VERSION "HINBNNNYNNNNNNNNNNNNNNNNNNNNNNNNNNNYYNNNNN/4>%%%/4/'%**4NNN///"

NS_ :

BS_:

BU_: Traffic Tester CGW ADU

BO_ 1103 ADU_HMI_Information_1: 32 ADU
 SG_ PDA_disp_forward_vehicle : 249|2@0+ (1,0) [0|0] ""  CGW
 SG_ PDA_disp_traffic : 251|2@0+ (1,0) [0|0] ""  CGW
 SG_ PDA_disp_curve : 253|2@0+ (1,0) [0|0] ""  CGW
 SG_ PDA_state : 241|4@0+ (1,0) [0|0] ""  CGW
 SG_ ISA_fallback : 244|2@0+ (1,0) [0|0] ""  CGW
 SG_ ISA_overspeed : 246|2@0+ (1,0) [0|0] ""  CGW
 SG_ ISA_state : 234|4@0+ (1,0) [0|0] ""  CGW
 SG_ ISA_EV_kickdown : 235|1@0+ (1,0) [0|0] ""  CGW
 SG_ ISA_sign : 237|2@0+ (1,0) [0|0] ""  CGW
 SG_ ASC_state : 225|4@0+ (1,0) [0|0] ""  CGW
 SG_ ACC_EV_override : 226|1@0+ (1,0) [0|0] ""  CGW
 SG_ ACC_EV_offer_sign : 227|1@0+ (1,0) [0|0] ""  CGW
 SG_ ACC_EV_mode_change_reject : 228|1@0+ (1,0) [0|0] ""  CGW
 SG_ ACC_EV_mode_change_accept : 229|1@0+ (1,0) [0|0] ""  CGW
 SG_ ACC_EV_set_dist : 230|1@0+ (1,0) [0|0] ""  CGW
 SG_ ACC_set_distance : 218|4@0+ (1,0) [0|0] ""  CGW
 SG_ ACC_set_velocity : 210|8@0+ (1,0) [0|127] "Unitless"  CGW
 SG_ ACC_sign : 213|3@0+ (1,0) [0|0] ""  CGW
 SG_ ACC_stop : 215|2@0+ (1,0) [0|0] ""  CGW
 SG_ ACC_target_decel : 203|4@0+ (1,0) [0|0] ""  CGW
 SG_ ACC_state : 207|4@0+ (1,0) [0|0] ""  CGW
 SG_ ACC_target : 194|3@0+ (1,0) [0|0] ""  CGW
 SG_ AD_state : 199|4@0+ (1,0) [0|0] ""  CGW
 SG_ OCP_opp_lh : 176|2@0+ (1,0) [0|0] ""  CGW
 SG_ OCP_opp_rh : 178|2@0+ (1,0) [0|0] ""  CGW
 SG_ OCP_lane_lh : 180|2@0+ (1,0) [0|0] ""  CGW
 SG_ OCP_lane_rh : 182|2@0+ (1,0) [0|0] ""  CGW
 SG_ OCP_state : 170|4@0+ (1,0) [0|0] ""  CGW
 SG_ CBDA_target_lh : 163|2@0+ (1,0) [0|0] ""  CGW
 SG_ CBDA_target_rh : 165|2@0+ (1,0) [0|0] ""  CGW
 SG_ CBDA_state : 153|4@0+ (1,0) [0|0] ""  CGW
 SG_ BSM_target_lh : 146|2@0+ (1,0) [0|0] ""  CGW
 SG_ BSM_target_rh : 148|2@0+ (1,0) [0|0] ""  CGW
 SG_ BSM_state : 136|4@0+ (1,0) [0|0] ""  CGW
 SG_ FCTA_target_lh : 129|2@0+ (1,0) [0|0] ""  CGW
 SG_ FCTA_target_rh : 131|2@0+ (1,0) [0|0] ""  CGW
 SG_ FCTA_state : 135|4@0+ (1,0) [0|0] ""  CGW
 SG_ BSP_target_lh : 112|2@0+ (1,0) [0|0] ""  CGW
 SG_ BSP_target_rh : 114|2@0+ (1,0) [0|0] ""  CGW
 SG_ BSP_lane_lh : 116|2@0+ (1,0) [0|0] ""  CGW
 SG_ BSP_lane_rh : 118|2@0+ (1,0) [0|0] ""  CGW
 SG_ BSP_state : 106|4@0+ (1,0) [0|0] ""  CGW
 SG_ RDP_roadedge_lh : 99|2@0+ (1,0) [0|0] ""  CGW
 SG_ RDP_roadedge_rh : 101|2@0+ (1,0) [0|0] ""  CGW
 SG_ RDP_state : 89|4@0+ (1,0) [0|0] ""  CGW
 SG_ LDW_lane_lh : 82|2@0+ (1,0) [0|0] ""  CGW
 SG_ LDW_lane_rh : 84|2@0+ (1,0) [0|0] ""  CGW
 SG_ LDW_state : 72|4@0+ (1,0) [0|0] ""  CGW
 SG_ LDP_lane_lh : 65|2@0+ (1,0) [0|0] ""  CGW
 SG_ LDP_lane_rh : 67|2@0+ (1,0) [0|0] ""  CGW
 SG_ LDP_state : 71|4@0+ (1,0) [0|0] ""  CGW
 SG_ AES_state : 48|4@0+ (1,0) [0|0] ""  CGW
 SG_ RCTB_state : 55|4@0+ (1,0) [0|0] ""  CGW
 SG_ RCTA_target_lh : 44|2@0+ (1,0) [0|0] ""  CGW
 SG_ RCTA_target_rh : 46|2@0+ (1,0) [0|0] ""  CGW
 SG_ RCTA_state : 34|4@0+ (1,0) [0|0] ""  CGW
 SG_ RPTC_state : 25|4@0+ (1,0) [0|0] ""  CGW
 SG_ PAEB_state : 16|4@0+ (1,0) [0|0] ""  CGW
 SG_ CTB_target_lh : 21|2@0+ (1,0) [0|0] ""  CGW
 SG_ CTB_target_rh : 23|2@0+ (1,0) [0|0] ""  CGW
 SG_ CTB_state : 11|4@0+ (1,0) [0|0] ""  CGW
 SG_ PTC_state : 15|4@0+ (1,0) [0|0] ""  CGW
 SG_ SBS_IND_state : 3|4@0+ (1,0) [0|0] ""  CGW
 SG_ AEB_state : 7|4@0+ (1,0) [0|0] ""  CGW

BO_ 1100 ADAS_HMI_Information6: 32 ADU
 SG_ LMkrRCrv_FSC2_01 : 115|10@0+ (0.00002,-0.01) [-0.01|0.01004] "1/m"  CGW
 SG_ LMkrLCrv_FSC2_01 : 109|10@0+ (0.00002,-0.01) [-0.01|0.01004] "1/m"  CGW
 SG_ LMkrRYaw_FSC1_01 : 101|8@0+ (0.25,-30) [-30|30.5] "deg"  CGW
 SG_ LMkrLYaw_FSC1_01 : 93|8@0+ (0.25,-30) [-30|30.5] "deg"  CGW
 SG_ LMkrRY0_FSC1_01 : 87|10@0+ (0.01,-10) [-10|0.02] "m"  CGW
 SG_ LMkrLY0_FSC1_01 : 65|10@0+ (0.01,0) [0|10.02] "m"  CGW
 SG_ LMkrRReli_FSC1_01 : 68|3@0+ (1,0) [0|0] ""  CGW
 SG_ LMkrLReli_FSC1_01 : 71|3@0+ (1,0) [0|0] ""  CGW

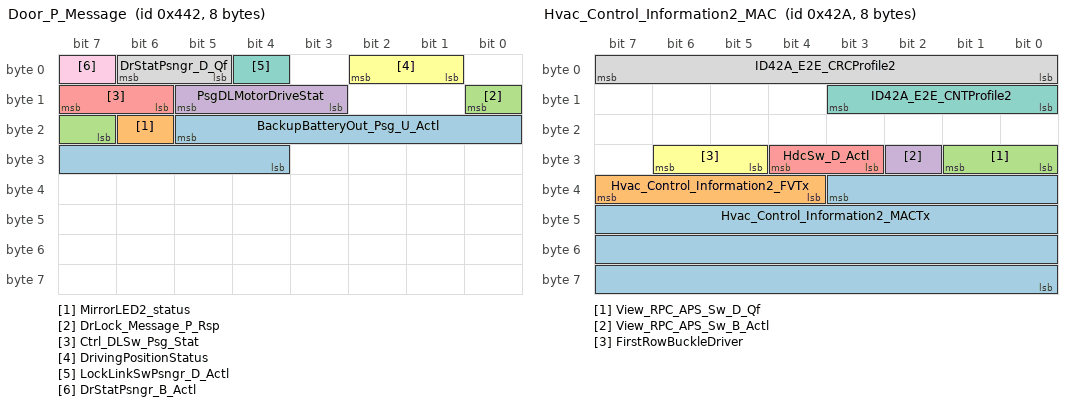
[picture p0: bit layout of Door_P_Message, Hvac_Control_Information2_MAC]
BO_ 1090 Door_P_Message: 8 CGW
 SG_ BackupBatteryOut_Psg_U_Actl : 21|10@0+ (0.02,0) [0|20.44] "V" Vector__XXX
 SG_ MirrorLED2_status : 22|1@0+ (1,0) [0|0] ""  ADU
 SG_ DrLock_Message_P_Rsp : 8|2@0+ (1,0) [0|0] "" Vector__XXX
 SG_ PsgDLMotorDriveStat : 13|3@0+ (1,0) [0|0] "" Vector__XXX
 SG_ Ctrl_DLSw_Psg_Stat : 15|2@0+ (1,0) [0|0] "" Vector__XXX
 SG_ DrivingPositionStatus : 2|2@0+ (1,0) [0|0] "" Vector__XXX
 SG_ LockLinkSwPsngr_D_Actl : 4|1@0+ (1,0) [0|0] ""  ADU
 SG_ DrStatPsngr_D_Qf : 6|2@0+ (1,0) [0|0] ""  ADU
 SG_ DrStatPsngr_B_Actl : 7|1@0+ (1,0) [0|0] ""  ADU

BO_ 1089 TripData_Control2: 32 CGW
 SG_ AvlFuelG_BCM : 119|10@0+ (0.1,0) [0|102.3] "L/100km" Vector__XXX
 SG_ AvlFuelE_BCM : 99|12@0+ (0.025,0) [0|102.375] "km/L" Vector__XXX
 SG_ OdoDistance : 78|27@0+ (0.02,0) [0|2684354.54] "km"  ADU
 SG_ AvlPwrG_BCM : 11|10@0+ (0.1,0) [0|102.3] "kwh/100km" Vector__XXX
 SG_ AvPwrE_BCM : 7|12@0+ (0.025,0) [0|102.375] "km/kwh" Vector__XXX

BO_ 1088 Door_D_Message: 8 CGW
 SG_ DOORDMSG_No_Cs : 63|8@0+ (1,0) [0|255] "" Vector__XXX
 SG_ DOORDMSG_No_Cnt : 51|4@0+ (1,0) [0|15] "" Vector__XXX
 SG_ Move_AutoDposMirror_Res : 53|2@0+ (1,0) [0|0] "" Vector__XXX
 SG_ BackupBatteryOut_Drv_U_Act : 47|10@0+ (0.02,0) [0|20.44] "V" Vector__XXX
 SG_ MirrorLED1_status : 32|1@0+ (1,0) [0|0] ""  ADU
 SG_ DrLock_Message_D_Rsp : 34|2@0+ (1,0) [0|0] "" Vector__XXX
 SG_ DrivingPositionRequest : 36|2@0+ (1,0) [0|0] "" Vector__XXX
 SG_ Mirror_AjustSelSW_Status : 38|2@0+ (1,0) [0|0] "" Vector__XXX
 SG_ MirrorFoldRequest : 24|2@0+ (1,0) [0|0] "" Vector__XXX
 SG_ MirrorAdjustRequest : 27|3@0+ (1,0) [0|0] "" Vector__XXX
 SG_ MirrorAdjst_Manual_Status : 28|1@0+ (1,0) [0|0] "" Vector__XXX
 SG_ MirrorAdjst_Status : 29|1@0+ (1,0) [0|0] "" Vector__XXX
 SG_ Erase_MirrorMem_Res : 31|2@0+ (1,0) [0|0] "" Vector__XXX
 SG_ Recall_MirrorMem_Res : 17|2@0+ (1,0) [0|0] "" Vector__XXX
 SG_ Record_MirrorMem_Res : 19|2@0+ (1,0) [0|0] "" Vector__XXX
 SG_ PW_Move_R : 22|3@0+ (1,0) [0|0] "" Vector__XXX
 SG_ PW_Move_P : 9|3@0+ (1,0) [0|0] "" Vector__XXX
 SG_ PWcut_D_Actl : 11|2@0+ (1,0) [0|0] "" Vector__XXX
 SG_ DrvDLMotorDriveStat : 15|4@0+ (1,0) [0|0] "" Vector__XXX
 SG_ Ctrl_DLSw_Drv_Stat : 1|2@0+ (1,0) [0|0] "" Vector__XXX
 SG_ LockLinkSwDrv_D_Actl : 3|2@0+ (1,0) [0|0] ""  ADU
 SG_ DrStatDrv_D_Qf : 6|2@0+ (1,0) [0|0] ""  ADU
 SG_ DrStatDrv_B_Actl : 7|1@0+ (1,0) [0|0] ""  ADU

BO_ 1087 RBCM_Information1: 8 CGW
 SG_ RBCMINFO1_No_Cs : 63|8@0+ (1,0) [0|255] "" Vector__XXX
 SG_ RBCMINFO1_No_Cnt : 51|4@0+ (1,0) [0|15] "" Vector__XXX
 SG_ RearWipr_Pos_Actl : 53|2@0+ (1,0) [0|0] "" Vector__XXX
 SG_ Rearfog_D_Act : 55|2@0+ (1,0) [0|0] "" Vector__XXX
 SG_ Reverse_D_Act : 41|2@0+ (1,0) [0|0] "" Vector__XXX
 SG_ Stoplamp_D_Act : 43|2@0+ (1,0) [0|0] ""  ADU
 SG_ Taillamp2_D_Act : 45|2@0+ (1,0) [0|0] "" Vector__XXX
 SG_ Taillamp1_D_Act : 47|2@0+ (1,0) [0|0] "" Vector__XXX
 SG_ RearTurnL_D_Act : 33|2@0+ (1,0) [0|0] ""  ADU
 SG_ RearTurnR_D_Act : 35|2@0+ (1,0) [0|0] ""  ADU
 SG_ RearWipr_Stall_Status : 36|1@0+ (1,0) [0|0] "" Vector__XXX
 SG_ RearWipr_Ctrl_Status : 39|3@0+ (1,0) [0|0] "" Vector__XXX
 SG_ Trailer_Towing_B_Actl : 24|1@0+ (1,0) [0|0] ""  ADU
 SG_ Trailer_Hitch_B_Actl : 25|1@0+ (1,0) [0|0] ""  ADU
 SG_ FuelLvlVref_No_Raw : 19|10@0+ (1,0) [0|1023] "" Vector__XXX
 SG_ FuelLvlDssvSide_No_Raw : 13|10@0+ (1,0) [0|1023] "" Vector__XXX
 SG_ FuelLvlActvSide_No_Raw : 7|10@0+ (1,0) [0|1023] "" Vector__XXX

BO_ 1086 Gateway_Information1: 32 CGW
 SG_ PreAirCon_Timer_Reservation_FS : 80|1@0+ (1,0) [0|0] "" Vector__XXX
 SG_ Charge_Timer_Reservation_FS : 81|1@0+ (1,0) [0|0] "" Vector__XXX
 SG_ RsvTime_PreAirCon_Status : 82|1@0+ (1,0) [0|0] "" Vector__XXX
 SG_ Charge_Distance_Impossible : 83|1@0+ (1,0) [0|0] "" Vector__XXX
 SG_ Charge_SOCdistance : 74|7@0+ (1,0) [0|100] "%" Vector__XXX
 SG_ Charge_Available_Distance_Upper : 70|9@0+ (2,0) [0|1000] "km" Vector__XXX
 SG_ RsvTime_Charge_Status : 71|1@0+ (1,0) [0|0] "" Vector__XXX
 SG_ Balarm_Reason_D_Actl : 48|4@0+ (1,0) [0|0] "" Vector__XXX
 SG_ OilDtr_InitTime : 54|6@0+ (1,0) [0|63] "month" Vector__XXX
 SG_ OilDtr_InitDistK : 44|6@0+ (1000,0) [0|63000] "km" Vector__XXX
 SG_ UP_Light_SENSOR_Meas : 38|10@0+ (1,0) [0|1023] "HEX"  ADU
 SG_ UP_Light_SENSOR_Qf : 39|1@0+ (1,0) [0|0] ""  ADU
 SG_ OilDtrWrnB_D_Rq : 25|2@0+ (1,0) [0|3] "" Vector__XXX
 SG_ DrStatHood_B_Actl : 28|1@0+ (1,0) [0|0] "" Vector__XXX
 SG_ Burglar_Status : 31|3@0+ (1,0) [0|0] "" Vector__XXX

BO_ 1084 CBCM_Message: 32 CGW
 SG_ Ota_SuppIgonStat : 127|4@0+ (1,0) [0|0] "" Vector__XXX
 SG_ Charge_Remote_Flag : 113|2@0+ (1,0) [0|0] "" Vector__XXX
 SG_ Defroster_Rear_Remote : 115|2@0+ (1,0) [0|0] "" Vector__XXX
 SG_ Defroster_Front_Remote : 117|2@0+ (1,0) [0|0] "" Vector__XXX
 SG_ PreAircon_RemoteTemperature : 109|8@0+ (0.1,12) [12|37.5] "deg.C" Vector__XXX
 SG_ PreAircon_Remote_Flag : 111|2@0+ (1,0) [0|0] "" Vector__XXX
 SG_ PreAircon_Remote_Cancel_Flag : 97|2@0+ (1,0) [0|0] "" Vector__XXX
 SG_ SeatCtrl_Remote_Rr_LH : 101|4@0+ (1,0) [0|0] "" Vector__XXX
 SG_ SeatCtrl_Remote_Rr_RH : 89|4@0+ (1,0) [0|0] "" Vector__XXX
 SG_ SteeringHeater_Remote : 91|2@0+ (1,0) [0|0] "" Vector__XXX
 SG_ SeatCtrl_Remote_Ps : 95|4@0+ (1,0) [0|0] "" Vector__XXX
 SG_ SeatCtrl_Remote_Dr : 83|4@0+ (1,0) [0|0] "" Vector__XXX
 SG_ RemDrvDistPer_D_Actl : 50|8@0+ (0.5,0) [0|100] "percent" Vector__XXX
 SG_ Fuel_Lid_Motor_Lock_Request : 52|2@0+ (1,0) [0|0] "" Vector__XXX
 SG_ FWD_Light_SENSOR_Meas : 46|10@0+ (1,0) [0|1023] "HEX"  ADU
 SG_ FWD_Light_SENSOR_Qf : 47|1@0+ (1,0) [0|0] ""  ADU
 SG_ DrStatRr_B_Actl : 32|1@0+ (1,0) [0|0] ""  ADU
 SG_ PwSavMode_D_Actl : 34|2@0+ (1,0) [0|0] "" Vector__XXX
 SG_ DrStatC_D_Qf : 36|2@0+ (1,0) [0|0] ""  ADU
 SG_ SecurityStatus : 37|1@0+ (1,0) [0|0] "" Vector__XXX
 SG_ PwSavModeDisp_D_Req : 24|2@0+ (1,0) [0|0] "" Vector__XXX
 SG_ GlobalOpenClose_Request : 26|2@0+ (1,0) [0|0] "" Vector__XXX
 SG_ TrnkLg_Motor_Request : 27|1@0+ (1,0) [0|0] "" Vector__XXX
 SG_ DrLockUnlock_Ctl_Rq : 31|4@0+ (1,0) [0|0] "" Vector__XXX
 SG_ DrLock_Message : 7|24@0+ (1,0) [0|16777215] "" Vector__XXX

BO_ 1078 Hvac_Control_Information2: 8 CGW
 SG_ SteerHeatIndic_D_Req : 57|2@0+ (1,0) [0|0] "" Vector__XXX
 SG_ SeatVentIndicRr_D_Req : 60|3@0+ (1,0) [0|0] "" Vector__XXX
 SG_ SeatVentIndicRl_D_Req : 63|3@0+ (1,0) [0|0] "" Vector__XXX
 SG_ SeatHeatIndicRr_D_Req : 50|3@0+ (1,0) [0|0] "" Vector__XXX
 SG_ SteerHeat_Elm_Enable : 52|2@0+ (1,0) [0|0] "" Vector__XXX
 SG_ SeatHeat_Elm_Enable : 54|2@0+ (1,0) [0|0] "" Vector__XXX
 SG_ Charge_Mode_Enabled_SW : 40|2@0+ (1,0) [0|0] "" Vector__XXX
 SG_ Drive_Mode_Enabled_Switch : 42|2@0+ (1,0) [0|0] "" Vector__XXX
 SG_ atcControlStatus : 45|3@0+ (1,0) [0|0] "" Vector__XXX
 SG_ SeatVentIndicFr_D_Req : 32|3@0+ (1,0) [0|0] "" Vector__XXX
 SG_ SeatVentIndicFl_D_Req : 35|3@0+ (1,0) [0|0] "" Vector__XXX
 SG_ SeatHeatIndicFr_D_Req : 38|3@0+ (1,0) [0|0] "" Vector__XXX
 SG_ SeatHeatIndicFl_D_Req : 25|3@0+ (1,0) [0|0] "" Vector__XXX
 SG_ atcACmodeDisp : 28|3@0+ (1,0) [0|0] "" Vector__XXX
 SG_ atcAImodeDisp : 16|4@0+ (1,0) [0|0] ""  ADU
 SG_ atcADmodeDisp : 20|4@0+ (1,0) [0|0] "" Vector__XXX
 SG_ atcBlwLvlDisp : 8|4@0+ (1,0) [0|0] "" Vector__XXX
 SG_ HvacEngStopCtrl_D_Actl : 10|2@0+ (1,0) [0|0] "" Vector__XXX
 SG_ SeatHeatIndicRl_D_Req : 13|3@0+ (1,0) [0|0] "" Vector__XXX
 SG_ BlowerSpeed : 1|4@0+ (1,0) [0|0] "" Vector__XXX
 SG_ HvacEngStopInputFail_D_Rq : 4|3@0+ (1,0) [0|0] "" Vector__XXX
 SG_ HvacAirCond_B_Rq : 5|1@0+ (1,0) [0|0] ""  ADU
 SG_ HvacEngStopDis_B_Rq_exceptTEva : 6|1@0+ (1,0) [0|0] "" Vector__XXX
 SG_ HvacEngStopDis_B_Rq : 7|1@0+ (1,0) [0|0] "" Vector__XXX

BO_ 1066 Hvac_Control_Information2_MAC: 8 CGW
 SG_ Hvac_Control_Information2_MACTx : 35|28@0+ (1,0) [0|268435455] ""  ADU
 SG_ Hvac_Control_Information2_FVTx : 39|4@0+ (1,0) [0|15] ""  ADU
 SG_ View_RPC_APS_Sw_D_Qf : 25|2@0+ (1,0) [0|0] ""  ADU
 SG_ View_RPC_APS_Sw_B_Actl : 26|1@0+ (1,0) [0|0] ""  ADU
 SG_ HdcSw_D_Actl : 28|2@0+ (1,0) [0|0] ""  ADU
 SG_ FirstRowBuckleDriver : 30|2@0+ (1,0) [0|0] ""  ADU
 SG_ ID42A_E2E_CNTProfile2 : 11|4@0+ (1,0) [0|15] ""  ADU
 SG_ ID42A_E2E_CRCProfile2 : 7|8@0+ (1,0) [0|255] ""  ADU

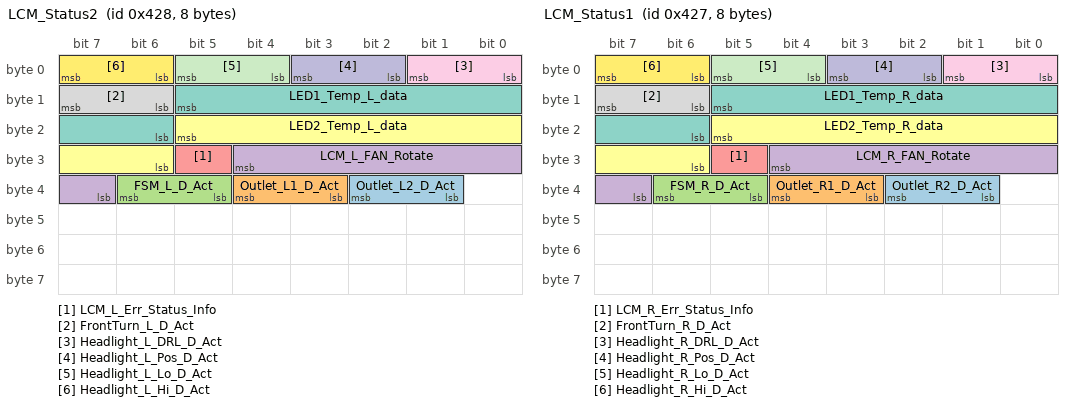
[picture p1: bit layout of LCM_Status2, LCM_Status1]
BO_ 1064 LCM_Status2: 8 CGW
 SG_ Outlet_L2_D_Act : 34|2@0+ (1,0) [0|0] "" Vector__XXX
 SG_ Outlet_L1_D_Act : 36|2@0+ (1,0) [0|0] "" Vector__XXX
 SG_ FSM_L_D_Act : 38|2@0+ (1,0) [0|0] "" Vector__XXX
 SG_ LCM_L_FAN_Rotate : 28|6@0+ (100,0) [0|5000] "rpm" Vector__XXX
 SG_ LCM_L_Err_Status_Info : 29|1@0+ (1,0) [0|0] ""  ADU
 SG_ LED2_Temp_L_data : 21|8@0+ (1,-40) [-40|210] "degC" Vector__XXX
 SG_ LED1_Temp_L_data : 13|8@0+ (1,-40) [-40|210] "degC" Vector__XXX
 SG_ FrontTurn_L_D_Act : 15|2@0+ (1,0) [0|0] ""  ADU
 SG_ Headlight_L_DRL_D_Act : 1|2@0+ (1,0) [0|0] "" Vector__XXX
 SG_ Headlight_L_Pos_D_Act : 3|2@0+ (1,0) [0|0] "" Vector__XXX
 SG_ Headlight_L_Lo_D_Act : 5|2@0+ (1,0) [0|0] ""  ADU
 SG_ Headlight_L_Hi_D_Act : 7|2@0+ (1,0) [0|0] ""  ADU

BO_ 1063 LCM_Status1: 8 CGW
 SG_ Outlet_R2_D_Act : 34|2@0+ (1,0) [0|0] "" Vector__XXX
 SG_ Outlet_R1_D_Act : 36|2@0+ (1,0) [0|0] "" Vector__XXX
 SG_ FSM_R_D_Act : 38|2@0+ (1,0) [0|0] "" Vector__XXX
 SG_ LCM_R_FAN_Rotate : 28|6@0+ (100,0) [0|5000] "rpm" Vector__XXX
 SG_ LCM_R_Err_Status_Info : 29|1@0+ (1,0) [0|0] ""  ADU
 SG_ LED2_Temp_R_data : 21|8@0+ (1,-40) [-40|210] "degC" Vector__XXX
 SG_ LED1_Temp_R_data : 13|8@0+ (1,-40) [-40|210] "degC" Vector__XXX
 SG_ FrontTurn_R_D_Act : 15|2@0+ (1,0) [0|0] ""  ADU
 SG_ Headlight_R_DRL_D_Act : 1|2@0+ (1,0) [0|0] "" Vector__XXX
 SG_ Headlight_R_Pos_D_Act : 3|2@0+ (1,0) [0|0] "" Vector__XXX
 SG_ Headlight_R_Lo_D_Act : 5|2@0+ (1,0) [0|0] ""  ADU
 SG_ Headlight_R_Hi_D_Act : 7|2@0+ (1,0) [0|0] ""  ADU

BO_ 1052 AVN1SB1: 32 CGW
 SG_ GRDTIME : 255|8@0+ (1,0) [0|255] "s"  ADU
 SG_ GRDDIST : 247|8@0+ (10,0) [0|2550] "m"  ADU
 SG_ FORMID_D : 239|8@0+ (1,0) [0|255] ""  ADU
 SG_ MDCREQID : 231|8@0+ (1,0) [0|255] ""  ADU
 SG_ PADDING1 : 199|32@0+ (1,0) [0|4294967295] ""  ADU
 SG_ FORMID_C : 191|8@0+ (1,0) [0|255] ""  ADU
 SG_ MAXTRG : 179|4@0+ (1,0) [0|15] ""  ADU
 SG_ LOGIOPE : 183|4@0+ (1,0) [0|15] ""  ADU
 SG_ FORMID_B : 175|8@0+ (1,0) [0|255] ""  ADU
 SG_ FORMID_A : 167|8@0+ (1,0) [0|255] ""  ADU
 SG_ COMPVAL : 135|32@0+ (0.1,0) [0|429496729.5] ""  ADU
 SG_ Y_CONST : 103|32@0+ (1,0) [0|4294967295] ""  ADU
 SG_ COMPOPE : 91|4@0+ (1,0) [0|15] ""  ADU
 SG_ PREPROC : 95|4@0+ (1,0) [0|15] ""  ADU
 SG_ Y_DELAY : 87|8@0+ (0.1,0) [0|25.5] "s"  ADU
 SG_ PADDINGY : 75|4@0+ (1,0) [0|15] ""  ADU
 SG_ Y_TYPE : 79|4@0+ (1,0) [0|15] ""  ADU
 SG_ Y_DATAID : 63|16@0+ (1,0) [0|65535] ""  ADU
 SG_ X_DELAY : 55|8@0+ (0.1,0) [0|25.5] "s"  ADU
 SG_ PADDINGX : 43|4@0+ (1,0) [0|15] ""  ADU
 SG_ X_TYPE : 47|4@0+ (1,0) [0|15] ""  ADU
 SG_ X_DATAID : 31|16@0+ (1,0) [0|65535] ""  ADU
 SG_ FORMID : 23|8@0+ (1,0) [0|255] ""  ADU
 SG_ FRAMID0 : 15|8@0+ (1,0) [0|255] ""  ADU
 SG_ TTLFRAM : 7|8@0+ (1,0) [0|255] ""  ADU

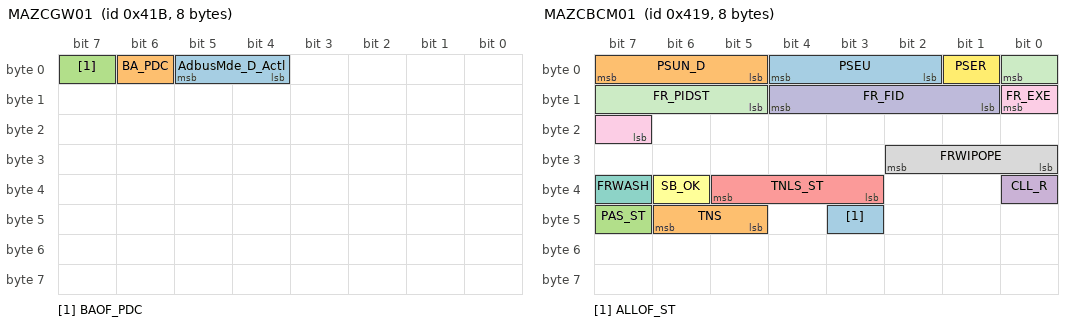
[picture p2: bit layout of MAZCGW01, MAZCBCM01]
BO_ 1051 MAZCGW01: 8 CGW
 SG_ AdbusMde_D_Actl : 5|2@0+ (1,0) [0|0] ""  ADU
 SG_ BA_PDC : 6|1@0+ (1,0) [0|0] ""  ADU
 SG_ BAOF_PDC : 7|1@0+ (1,0) [0|0] ""  ADU

BO_ 1050 MAZCBCM02: 8 CGW
 SG_ ID41A_No_Cs : 63|8@0+ (1,0) [0|255] ""  ADU
 SG_ GSNSOFF : 53|1@0+ (1,0) [0|0] "" Vector__XXX
 SG_ EIGRCPFG : 42|1@0+ (1,0) [0|1] ""  ADU
 SG_ TNLS : 44|2@0+ (1,0) [0|3] "" Vector__XXX
 SG_ G_DETECT : 33|1@0+ (1,0) [0|0] "" Vector__XXX
 SG_ AdbusMde_D_Actl_BCM : 25|2@0+ (1,0) [0|0] ""  ADU
 SG_ ERROR : 28|3@0+ (1,0) [0|7] ""  ADU
 SG_ MO_IND : 29|1@0+ (1,0) [0|1] ""  ADU
 SG_ TB_CONN : 31|2@0+ (1,0) [0|3] ""  ADU
 SG_ PARK_S : 21|6@0+ (1,0) [0|63] ""  ADU
 SG_ BA_PDC_BCM : 15|1@0+ (1,0) [0|0] ""  ADU
 SG_ BAOF_PDC_BCM : 0|1@0+ (1,0) [0|0] ""  ADU
 SG_ ACC_PDC : 1|1@0+ (1,0) [0|0] ""  ADU
 SG_ IGR_PDC : 2|1@0+ (1,0) [0|0] ""  ADU
 SG_ IGP_PDC : 3|1@0+ (1,0) [0|0] ""  ADU
 SG_ TRNR_S : 4|1@0+ (1,0) [0|0] "" Vector__XXX
 SG_ TRNL_S : 5|1@0+ (1,0) [0|0] "" Vector__XXX
 SG_ CRGR_S : 6|1@0+ (1,0) [0|1] "" Vector__XXX
 SG_ CRGL_S : 7|1@0+ (1,0) [0|1] "" Vector__XXX

BO_ 1049 MAZCBCM01: 8 CGW
 SG_ ALLOF_ST : 43|1@0+ (1,0) [0|0] ""  ADU
 SG_ TNS : 46|2@0+ (1,0) [0|0] "" Vector__XXX
 SG_ PAS_ST : 47|1@0+ (1,0) [0|0] "" Vector__XXX
 SG_ CLL_R : 32|1@0+ (1,0) [0|0] "" Vector__XXX
 SG_ TNLS_ST : 37|3@0+ (1,0) [0|0] "" Vector__XXX
 SG_ SB_OK : 38|1@0+ (1,0) [0|0] ""  ADU
 SG_ FRWASH : 39|1@0+ (1,0) [0|0] ""  ADU
 SG_ FRWIPOPE : 26|3@0+ (1,0) [0|0] ""  ADU
 SG_ FR_EXE : 8|2@0+ (1,0) [0|0] ""  ADU
 SG_ FR_FID : 12|4@0+ (1,0) [0|0] ""  ADU
 SG_ FR_PIDST : 0|4@0+ (1,0) [0|0] ""  ADU
 SG_ PSER : 1|1@0+ (1,0) [0|0] "" Vector__XXX
 SG_ PSEU : 4|3@0+ (1,0) [0|0] "" Vector__XXX
 SG_ PSUN_D : 7|3@0+ (1,0) [0|0] "" Vector__XXX

BO_ 1048 MAZDRD01: 8 CGW
 SG_ MRMV_R : 7|2@0+ (1,0) [0|0] ""  ADU

BO_ 1047 BrakeSysFeatures: 8 CGW
 SG_ BrakeSysFeatures_No_Cs : 63|8@0+ (1,0) [0|255] ""  ADU
 SG_ BrakeSysFeatures_No_Cnt : 51|4@0+ (1,0) [0|15] ""  ADU
 SG_ EPB_TrqRequire : 19|1@0+ (1,0) [0|0] "" Vector__XXX
 SG_ EPB_IGoff_Apply_Inhibit : 20|1@0+ (1,0) [0|0] "" Vector__XXX
 SG_ RGN_StpLmp_Fail_Flag : 21|1@0+ (1,0) [0|0] "" Vector__XXX
 SG_ BrkSupWhlTq_B_Falt : 22|1@0+ (1,0) [0|0] "" Vector__XXX
 SG_ BrkFluidLvl_D_Actl : 8|2@0+ (1,0) [0|0] "" Vector__XXX
 SG_ DSC_OnOff_status : 9|1@0+ (1,0) [0|0] ""  ADU
 SG_ TCS_ENG_FAILD : 10|1@0+ (1,0) [0|0] "" Vector__XXX
 SG_ TCS_BRK_FAILD : 11|1@0+ (1,0) [0|0] "" Vector__XXX
 SG_ Dsc_B_Falt : 12|1@0+ (1,0) [0|0] ""  ADU
 SG_ EPB_Status : 15|3@0+ (1,0) [0|0] "" Vector__XXX
 SG_ EPB_SwitchPosition : 1|2@0+ (1,0) [0|0] "" Vector__XXX
 SG_ EPB_EnableExternalApply_PT : 2|1@0+ (1,0) [0|0] "" Vector__XXX
 SG_ EPB_EnableDecelRequest : 3|1@0+ (1,0) [0|0] "" Vector__XXX
 SG_ EPB_EnableExternalApply_VCM : 4|1@0+ (1,0) [0|0] "" Vector__XXX
 SG_ AutoHoldStdbyLamp_D_Rq : 6|2@0+ (1,0) [0|0] "" Vector__XXX

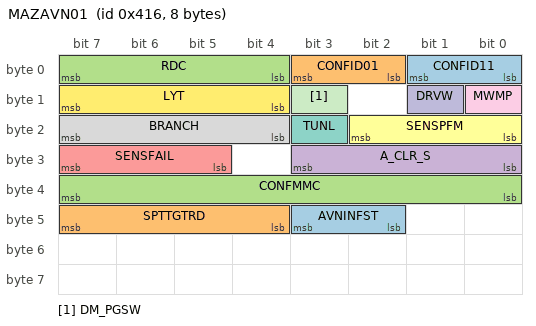
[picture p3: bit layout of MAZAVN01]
BO_ 1046 MAZAVN01: 8 CGW
 SG_ AVNINFST : 43|2@0+ (1,0) [0|3] ""  ADU
 SG_ SPTTGTRD : 47|4@0+ (1,0) [0|15] ""  ADU
 SG_ CONFMMC : 39|8@0+ (1,0) [0|255] ""  ADU
 SG_ A_CLR_S : 27|4@0+ (1,0) [0|0] ""  ADU
 SG_ SENSFAIL : 31|3@0+ (1,0) [0|7] ""  ADU
 SG_ SENSPFM : 18|3@0+ (1,0) [0|7] "s"  ADU
 SG_ TUNL : 19|1@0+ (1,0) [0|1] ""  ADU
 SG_ BRANCH : 23|4@0+ (1,0) [0|15] ""  ADU
 SG_ MWMP : 8|1@0+ (1,0) [0|1] ""  ADU
 SG_ DRVW : 9|1@0+ (1,0) [0|1] "s"  ADU
 SG_ DM_PGSW : 11|1@0+ (1,0) [0|1] ""  ADU
 SG_ LYT : 15|4@0+ (1,0) [0|15] ""  ADU
 SG_ CONFID11 : 1|2@0+ (1,0) [0|3] ""  ADU
 SG_ CONFID01 : 3|2@0+ (1,0) [0|3] ""  ADU
 SG_ RDC : 7|4@0+ (1,0) [0|15] ""  ADU

BO_ 1045 ADU1S06: 32 ADU
 SG_ DTSSLTID : 239|6@0+ (1,0) [0|63] ""  CGW
 SG_ DEPSAEST : 223|16@0+ (0.001,0) [0|65.535] "rad"  CGW
 SG_ DTSSSTR : 207|16@0+ (0.001,0) [0|65.535] "rad"  CGW
 SG_ ERMFLSV : 191|16@0+ (0.1,0) [0|6553.5] "mL"  CGW
 SG_ ERMEESV : 175|16@0+ (0.1,0) [0|6553.5] "Wh"  CGW
 SG_ DSTVIB : 162|3@0+ (1,0) [0|0] ""  CGW
 SG_ GAERR3_H : 153|7@0+ (0.1,0) [0|12.7] "deg"  CGW
 SG_ GAEVAL_H : 144|7@0+ (0.1,0) [0|12.7] "deg"  CGW
 SG_ GAERR1_V : 151|7@0+ (0.5,0) [0|63.5] "deg"  CGW
 SG_ DRTCNT_G : 135|16@0+ (1,0) [0|65535] ""  CGW
 SG_ GAE_V_R1 : 123|4@0+ (1,0) [0|15] ""  CGW
 SG_ SDIRT_G : 117|10@0+ (1,0) [0|1023] ""  CGW
 SG_ FRDHTR_G : 118|1@0+ (1,0) [0|0] ""  CGW
 SG_ GAE_H_R3 : 109|7@0+ (0.02,0) [0|2.54] "deg"  CGW
 SG_ ERMCNTST : 111|2@0+ (1,0) [0|0] ""  CGW
 SG_ DM_PVMCS : 95|16@0+ (1,0) [0|65535] ""  CGW
 SG_ DM_PVMVW : 79|16@0+ (1,0) [0|65535] ""  CGW
 SG_ PV_AREA : 71|8@0+ (0.04,0) [0|10.2] "m^2"  CGW
 SG_ V_IDARGL : 59|3@0+ (1,0) [0|0] ""  CGW
 SG_ V_IDANOA : 62|3@0+ (1,0) [0|0] ""  CGW
 SG_ EJLDACP : 63|1@0+ (1,0) [0|0] ""  CGW
 SG_ EJDEVPRD : 55|8@0+ (1,0) [0|255] ""  CGW
 SG_ V_IDACCL : 46|4@0+ (1,0) [0|0] ""  CGW
 SG_ SWSSTAT : 34|4@0+ (1,0) [0|15] ""  CGW
 SG_ LDARCGR : 38|4@0+ (1,0) [0|15] ""  CGW
 SG_ LDARCGL : 26|4@0+ (1,0) [0|15] ""  CGW
 SG_ FCMINTMP : 31|5@0+ (2,0) [0|62] "deg.C"  CGW
 SG_ LDARSN : 23|8@0+ (1,0) [0|255] ""  CGW
 SG_ LDASTATR : 15|8@0+ (1,0) [0|255] ""  CGW
 SG_ LDASTATL : 7|8@0+ (1,0) [0|255] ""  CGW

BO_ 1044 ADU1S05: 32 ADU
 SG_ ACCMARB : 23|1@0+ (1,0) [0|0] ""  CGW
 SG_ ACCMRCG : 10|3@0+ (1,0) [0|0] ""  CGW
 SG_ ACCMSGN : 12|2@0+ (1,0) [0|0] ""  CGW
 SG_ ACCMPHS : 15|3@0+ (1,0) [0|0] ""  CGW
 SG_ ACCMDST : 7|8@0+ (2,0) [0|510] "m"  CGW

BO_ 1036 GCC_Config_Mgmt2: 8 CGW
 SG_ Central_CRC_40C m224 : 55|16@0+ (1,0) [0|65534] "" Vector__XXX
 SG_ CDID_Total_Number_40C m224 : 47|8@0+ (1,0) [0|254] "" Vector__XXX
 SG_ Reserved_E0_2_40C m224 : 31|16@0+ (1,0) [0|65534] "" Vector__XXX
 SG_ Reserved_E0_1_40C m224 : 15|16@0+ (1,0) [0|65534] "" Vector__XXX
 SG_ Reserved_95_7_40C m149 : 63|8@0+ (1,0) [0|254] "" Vector__XXX
 SG_ Reserved_95_6_40C m149 : 55|8@0+ (1,0) [0|254] "" Vector__XXX
 SG_ Reserved_95_5_40C m149 : 47|8@0+ (1,0) [0|254] "" Vector__XXX
 SG_ Reserved_95_4_40C m149 : 39|8@0+ (1,0) [0|254] "" Vector__XXX
 SG_ Reserved_95_3_40C m149 : 31|8@0+ (1,0) [0|254] "" Vector__XXX
 SG_ Reserved_95_2_40C m149 : 23|8@0+ (1,0) [0|254] "" Vector__XXX
 SG_ Reserved_95_1_40C m149 : 15|8@0+ (1,0) [0|254] "" Vector__XXX
 SG_ Reserved_94_7_40C m148 : 63|8@0+ (1,0) [0|254] "" Vector__XXX
 SG_ Reserved_94_6_40C m148 : 55|8@0+ (1,0) [0|254] "" Vector__XXX
 SG_ Reserved_94_5_40C m148 : 47|8@0+ (1,0) [0|254] "" Vector__XXX
 SG_ Reserved_94_4_40C m148 : 39|8@0+ (1,0) [0|254] "" Vector__XXX
 SG_ Reserved_94_3_40C m148 : 31|8@0+ (1,0) [0|254] "" Vector__XXX
 SG_ Reserved_94_2_40C m148 : 23|8@0+ (1,0) [0|254] "" Vector__XXX
 SG_ Reserved_94_1_40C m148 : 15|8@0+ (1,0) [0|254] "" Vector__XXX
 SG_ Reserved_93_7_40C m147 : 63|8@0+ (1,0) [0|254] "" Vector__XXX
 SG_ Reserved_93_6_40C m147 : 55|8@0+ (1,0) [0|254] "" Vector__XXX
 SG_ Reserved_93_5_40C m147 : 47|8@0+ (1,0) [0|254] "" Vector__XXX
 SG_ Reserved_93_4_40C m147 : 39|8@0+ (1,0) [0|254] "" Vector__XXX
 SG_ Reserved_93_3_40C m147 : 31|8@0+ (1,0) [0|254] "" Vector__XXX
 SG_ Reserved_93_2_40C m147 : 23|8@0+ (1,0) [0|254] "" Vector__XXX
 SG_ Reserved_93_1_40C m147 : 15|8@0+ (1,0) [0|254] "" Vector__XXX
 SG_ Reserved_92_7_40C m146 : 63|8@0+ (1,0) [0|254] "" Vector__XXX
 SG_ Reserved_92_6_40C m146 : 55|8@0+ (1,0) [0|254] "" Vector__XXX
 SG_ Reserved_92_5_40C m146 : 47|8@0+ (1,0) [0|254] "" Vector__XXX
 SG_ Reserved_92_4_40C m146 : 39|8@0+ (1,0) [0|254] "" Vector__XXX
 SG_ Reserved_92_3_40C m146 : 31|8@0+ (1,0) [0|254] "" Vector__XXX
 SG_ Reserved_92_2_40C m146 : 23|8@0+ (1,0) [0|254] "" Vector__XXX
 SG_ Reserved_92_1_40C m146 : 15|8@0+ (1,0) [0|254] "" Vector__XXX
 SG_ Reserved_91_7_40C m145 : 63|8@0+ (1,0) [0|254] "" Vector__XXX
 SG_ Reserved_91_6_40C m145 : 55|8@0+ (1,0) [0|254] "" Vector__XXX
 SG_ Reserved_91_5_40C m145 : 47|8@0+ (1,0) [0|254] "" Vector__XXX
 SG_ Reserved_91_4_40C m145 : 39|8@0+ (1,0) [0|254] "" Vector__XXX
 SG_ Reserved_91_3_40C m145 : 31|8@0+ (1,0) [0|254] "" Vector__XXX
 SG_ Reserved_91_2_40C m145 : 23|8@0+ (1,0) [0|254] "" Vector__XXX
 SG_ Reserved_91_1_40C m145 : 15|8@0+ (1,0) [0|254] "" Vector__XXX
 SG_ Reserved_90_7_40C m144 : 63|8@0+ (1,0) [0|254] "" Vector__XXX
 SG_ Reserved_90_6_40C m144 : 55|8@0+ (1,0) [0|254] "" Vector__XXX
 SG_ Reserved_90_5_40C m144 : 47|8@0+ (1,0) [0|254] "" Vector__XXX
 SG_ Reserved_90_4_40C m144 : 39|8@0+ (1,0) [0|254] "" Vector__XXX
 SG_ Reserved_90_3_40C m144 : 31|8@0+ (1,0) [0|254] "" Vector__XXX
 SG_ Reserved_90_2_40C m144 : 23|8@0+ (1,0) [0|254] "" Vector__XXX
 SG_ Reserved_90_1_40C m144 : 15|8@0+ (1,0) [0|254] "" Vector__XXX
 SG_ Reserved_82_7_40C m130 : 63|8@0+ (1,0) [0|254] "" Vector__XXX
 SG_ Reserved_82_6_40C m130 : 55|8@0+ (1,0) [0|254] "" Vector__XXX
 SG_ Reserved_82_5_40C m130 : 47|8@0+ (1,0) [0|254] "" Vector__XXX
 SG_ Reserved_82_4_40C m130 : 39|8@0+ (1,0) [0|254] "" Vector__XXX
 SG_ Reserved_82_3_40C m130 : 31|8@0+ (1,0) [0|254] "" Vector__XXX
 SG_ Reserved_82_2_40C m130 : 23|8@0+ (1,0) [0|254] "" Vector__XXX
 SG_ Reserved_82_1_40C m130 : 15|8@0+ (1,0) [0|254] "" Vector__XXX
 SG_ Reserved_80_7_40C m128 : 63|8@0+ (1,0) [0|254] "" Vector__XXX
 SG_ Reserved_80_6_40C m128 : 55|8@0+ (1,0) [0|254] "" Vector__XXX
 SG_ Reserved_80_5_40C m128 : 47|8@0+ (1,0) [0|254] "" Vector__XXX
 SG_ Reserved_80_4_40C m128 : 39|8@0+ (1,0) [0|254] "" Vector__XXX
 SG_ Reserved_80_3_40C m128 : 31|8@0+ (1,0) [0|254] "" Vector__XXX
 SG_ Reserved_80_2_40C m128 : 23|8@0+ (1,0) [0|254] "" Vector__XXX
 SG_ Reserved_80_1_40C m128 : 15|8@0+ (1,0) [0|254] "" Vector__XXX
 SG_ Reserved_72_7_40C m114 : 63|8@0+ (1,0) [0|254] "" Vector__XXX
 SG_ Reserved_72_6_40C m114 : 55|8@0+ (1,0) [0|254] "" Vector__XXX
 SG_ Reserved_72_5_40C m114 : 47|8@0+ (1,0) [0|254] "" Vector__XXX
 SG_ Reserved_72_4_40C m114 : 39|8@0+ (1,0) [0|254] "" Vector__XXX
 SG_ Reserved_72_3_40C m114 : 31|8@0+ (1,0) [0|254] "" Vector__XXX
 SG_ Reserved_72_2_40C m114 : 23|8@0+ (1,0) [0|254] "" Vector__XXX
 SG_ Reserved_72_1_40C m114 : 15|8@0+ (1,0) [0|254] "" Vector__XXX
 SG_ Reserved_70_7_40C m112 : 63|8@0+ (1,0) [0|254] "" Vector__XXX
 SG_ Reserved_70_6_40C m112 : 55|8@0+ (1,0) [0|254] "" Vector__XXX
 SG_ Reserved_70_5_40C m112 : 47|8@0+ (1,0) [0|254] "" Vector__XXX
 SG_ Reserved_70_4_40C m112 : 39|8@0+ (1,0) [0|254] "" Vector__XXX
 SG_ Reserved_70_3_40C m112 : 31|8@0+ (1,0) [0|254] "" Vector__XXX
 SG_ Reserved_70_2_40C m112 : 23|8@0+ (1,0) [0|254] "" Vector__XXX
 SG_ Reserved_70_1_40C m112 : 15|8@0+ (1,0) [0|254] "" Vector__XXX
 SG_ Reserved_63_7_40C m99 : 63|8@0+ (1,0) [0|254] "" Vector__XXX
 SG_ Reserved_63_6_40C m99 : 55|8@0+ (1,0) [0|254] "" Vector__XXX
 SG_ Reserved_63_5_40C m99 : 47|8@0+ (1,0) [0|254] "" Vector__XXX
 SG_ Reserved_63_4_40C m99 : 39|8@0+ (1,0) [0|254] "" Vector__XXX
 SG_ Reserved_63_3_40C m99 : 31|8@0+ (1,0) [0|254] "" Vector__XXX
 SG_ Reserved_63_2_40C m99 : 23|8@0+ (1,0) [0|254] "" Vector__XXX
 SG_ Reserved_63_1_40C m99 : 15|8@0+ (1,0) [0|254] "" Vector__XXX
 SG_ Reserved_62_7_40C m98 : 63|8@0+ (1,0) [0|254] "" Vector__XXX
 SG_ Reserved_62_6_40C m98 : 55|8@0+ (1,0) [0|254] "" Vector__XXX
 SG_ Reserved_62_5_40C m98 : 47|8@0+ (1,0) [0|254] "" Vector__XXX
 SG_ Reserved_62_4_40C m98 : 39|8@0+ (1,0) [0|254] "" Vector__XXX
 SG_ Reserved_62_3_40C m98 : 31|8@0+ (1,0) [0|254] "" Vector__XXX
 SG_ Reserved_62_2_40C m98 : 23|8@0+ (1,0) [0|254] "" Vector__XXX
 SG_ Reserved_62_1_40C m98 : 15|8@0+ (1,0) [0|254] "" Vector__XXX
 SG_ Reserved_60_7_40C m96 : 63|8@0+ (1,0) [0|254] "" Vector__XXX
 SG_ Reserved_60_6_40C m96 : 55|8@0+ (1,0) [0|254] "" Vector__XXX
 SG_ Reserved_60_5_40C m96 : 47|8@0+ (1,0) [0|254] "" Vector__XXX
 SG_ Reserved_60_4_40C m96 : 39|8@0+ (1,0) [0|254] "" Vector__XXX
 SG_ Reserved_60_3_40C m96 : 31|8@0+ (1,0) [0|254] "" Vector__XXX
 SG_ Reserved_60_2_40C m96 : 23|8@0+ (1,0) [0|254] "" Vector__XXX
 SG_ Reserved_60_1_40C m96 : 15|8@0+ (1,0) [0|254] "" Vector__XXX
 SG_ Reserved_52_7_40C m82 : 63|8@0+ (1,0) [0|254] "" Vector__XXX
 SG_ Reserved_52_6_40C m82 : 55|8@0+ (1,0) [0|254] "" Vector__XXX
 SG_ Reserved_52_5_40C m82 : 47|8@0+ (1,0) [0|254] "" Vector__XXX
 SG_ Reserved_52_4_40C m82 : 39|8@0+ (1,0) [0|254] "" Vector__XXX
 SG_ Reserved_52_3_40C m82 : 31|8@0+ (1,0) [0|254] "" Vector__XXX
 SG_ Reserved_52_2_40C m82 : 23|8@0+ (1,0) [0|254] "" Vector__XXX
 SG_ Reserved_52_1_40C m82 : 15|8@0+ (1,0) [0|254] "" Vector__XXX
 SG_ Reserved_50_7_40C m80 : 63|8@0+ (1,0) [0|254] "" Vector__XXX
 SG_ Reserved_50_6_40C m80 : 55|8@0+ (1,0) [0|254] "" Vector__XXX
 SG_ Reserved_50_5_40C m80 : 47|8@0+ (1,0) [0|254] "" Vector__XXX
 SG_ Reserved_50_4_40C m80 : 39|8@0+ (1,0) [0|254] "" Vector__XXX
 SG_ Reserved_50_3_40C m80 : 31|8@0+ (1,0) [0|254] "" Vector__XXX
 SG_ Reserved_50_2_40C m80 : 23|8@0+ (1,0) [0|254] "" Vector__XXX
 SG_ Reserved_50_1_40C m80 : 15|8@0+ (1,0) [0|254] "" Vector__XXX
 SG_ Reserved_40_7_40C m64 : 63|8@0+ (1,0) [0|254] "" Vector__XXX
 SG_ Reserved_40_6_40C m64 : 55|8@0+ (1,0) [0|254] "" Vector__XXX
 SG_ Reserved_40_5_40C m64 : 47|8@0+ (1,0) [0|254] "" Vector__XXX
 SG_ Reserved_40_4_40C m64 : 39|8@0+ (1,0) [0|254] "" Vector__XXX
 SG_ Reserved_40_3_40C m64 : 31|8@0+ (1,0) [0|254] "" Vector__XXX
 SG_ Reserved_40_2_40C m64 : 23|8@0+ (1,0) [0|254] "" Vector__XXX
 SG_ Reserved_40_1_40C m64 : 15|8@0+ (1,0) [0|254] "" Vector__XXX
 SG_ Reserved_30_7_40C m48 : 63|8@0+ (1,0) [0|254] "" Vector__XXX
 SG_ Reserved_30_6_40C m48 : 55|8@0+ (1,0) [0|254] "" Vector__XXX
 SG_ Reserved_30_5_40C m48 : 47|8@0+ (1,0) [0|254] "" Vector__XXX
 SG_ Reserved_30_4_40C m48 : 39|8@0+ (1,0) [0|254] "" Vector__XXX
 SG_ Reserved_30_3_40C m48 : 31|8@0+ (1,0) [0|254] "" Vector__XXX
 SG_ Reserved_30_2_40C m48 : 23|8@0+ (1,0) [0|254] "" Vector__XXX
 SG_ Reserved_30_1_40C m48 : 15|8@0+ (1,0) [0|254] "" Vector__XXX
 SG_ Reserved_25_7_40C m37 : 63|8@0+ (1,0) [0|254] "" Vector__XXX
 SG_ Reserved_25_6_40C m37 : 55|8@0+ (1,0) [0|254] "" Vector__XXX
 SG_ Reserved_25_5_40C m37 : 47|8@0+ (1,0) [0|254] "" Vector__XXX
 SG_ Reserved_25_4_40C m37 : 39|8@0+ (1,0) [0|254] "" Vector__XXX
 SG_ Reserved_25_3_40C m37 : 31|8@0+ (1,0) [0|254] "" Vector__XXX
 SG_ Reserved_25_2_40C m37 : 23|8@0+ (1,0) [0|254] "" Vector__XXX
 SG_ Reserved_25_1_40C m37 : 15|8@0+ (1,0) [0|254] "" Vector__XXX
 SG_ Reserved_20_7_40C m32 : 63|8@0+ (1,0) [0|254] "" Vector__XXX
 SG_ Reserved_20_6_40C m32 : 55|8@0+ (1,0) [0|254] "" Vector__XXX
 SG_ Reserved_20_5_40C m32 : 47|8@0+ (1,0) [0|254] "" Vector__XXX
 SG_ Reserved_20_4_40C m32 : 39|8@0+ (1,0) [0|254] "" Vector__XXX
 SG_ Reserved_20_3_40C m32 : 31|8@0+ (1,0) [0|254] "" Vector__XXX
 SG_ Reserved_20_2_40C m32 : 23|8@0+ (1,0) [0|254] "" Vector__XXX
 SG_ Reserved_20_1_40C m32 : 15|8@0+ (1,0) [0|254] "" Vector__XXX
 SG_ Reserved_16_7_40C m22 : 63|8@0+ (1,0) [0|254] "" Vector__XXX
 SG_ Reserved_16_6_40C m22 : 55|8@0+ (1,0) [0|254] "" Vector__XXX
 SG_ Reserved_16_5_40C m22 : 47|8@0+ (1,0) [0|254] "" Vector__XXX
 SG_ Reserved_16_4_40C m22 : 39|8@0+ (1,0) [0|254] "" Vector__XXX
 SG_ Reserved_16_3_40C m22 : 31|8@0+ (1,0) [0|254] "" Vector__XXX
 SG_ Reserved_16_2_40C m22 : 23|8@0+ (1,0) [0|254] "" Vector__XXX
 SG_ Reserved_16_1_40C m22 : 15|8@0+ (1,0) [0|254] "" Vector__XXX
 SG_ Reserved_15_7_40C m21 : 63|8@0+ (1,0) [0|254] "" Vector__XXX
 SG_ Reserved_15_6_40C m21 : 55|8@0+ (1,0) [0|254] "" Vector__XXX
 SG_ Reserved_15_5_40C m21 : 47|8@0+ (1,0) [0|254] "" Vector__XXX
 SG_ Reserved_15_4_40C m21 : 39|8@0+ (1,0) [0|254] "" Vector__XXX
 SG_ Reserved_15_3_40C m21 : 31|8@0+ (1,0) [0|254] "" Vector__XXX
 SG_ Reserved_15_2_40C m21 : 23|8@0+ (1,0) [0|254] "" Vector__XXX
 SG_ Reserved_15_1_40C m21 : 15|8@0+ (1,0) [0|254] "" Vector__XXX
 SG_ Reserved_14_7_40C m20 : 63|8@0+ (1,0) [0|254] "" Vector__XXX
 SG_ Reserved_14_6_40C m20 : 55|8@0+ (1,0) [0|254] "" Vector__XXX
 SG_ Reserved_14_5_40C m20 : 47|8@0+ (1,0) [0|254] "" Vector__XXX
 SG_ Reserved_14_4_40C m20 : 39|8@0+ (1,0) [0|254] "" Vector__XXX
 SG_ Reserved_14_3_40C m20 : 31|8@0+ (1,0) [0|254] "" Vector__XXX
 SG_ Reserved_14_2_40C m20 : 23|8@0+ (1,0) [0|254] "" Vector__XXX
 SG_ Reserved_14_1_40C m20 : 15|8@0+ (1,0) [0|254] "" Vector__XXX
 SG_ Reserved_13_7_40C m19 : 63|8@0+ (1,0) [0|254] "" Vector__XXX
 SG_ Reserved_13_6_40C m19 : 55|8@0+ (1,0) [0|254] "" Vector__XXX
 SG_ Reserved_13_5_40C m19 : 47|8@0+ (1,0) [0|254] "" Vector__XXX
 SG_ Reserved_13_4_40C m19 : 39|8@0+ (1,0) [0|254] "" Vector__XXX
 SG_ Reserved_13_3_40C m19 : 31|8@0+ (1,0) [0|254] "" Vector__XXX
 SG_ Reserved_13_2_40C m19 : 23|8@0+ (1,0) [0|254] "" Vector__XXX
 SG_ Reserved_13_1_40C m19 : 15|8@0+ (1,0) [0|254] "" Vector__XXX
 SG_ Reserved_12_7_40C m18 : 63|8@0+ (1,0) [0|254] "" Vector__XXX
 SG_ Reserved_12_6_40C m18 : 55|8@0+ (1,0) [0|254] "" Vector__XXX
 SG_ Reserved_12_5_40C m18 : 47|8@0+ (1,0) [0|254] "" Vector__XXX
 SG_ Reserved_12_4_40C m18 : 39|8@0+ (1,0) [0|254] "" Vector__XXX
 SG_ Reserved_12_3_40C m18 : 31|8@0+ (1,0) [0|254] "" Vector__XXX
 SG_ Reserved_12_2_40C m18 : 23|8@0+ (1,0) [0|254] "" Vector__XXX
 SG_ Reserved_12_1_40C m18 : 15|8@0+ (1,0) [0|254] "" Vector__XXX
 SG_ Reserved_11_7_40C m17 : 63|8@0+ (1,0) [0|254] "" Vector__XXX
 SG_ Reserved_11_6_40C m17 : 55|8@0+ (1,0) [0|254] "" Vector__XXX
 SG_ Reserved_11_5_40C m17 : 47|8@0+ (1,0) [0|254] "" Vector__XXX
 SG_ Reserved_11_4_40C m17 : 39|8@0+ (1,0) [0|254] "" Vector__XXX
 SG_ Country_3 m17 : 31|8@0+ (1,0) [0|254] ""  ADU
 SG_ Country_2 m17 : 23|8@0+ (1,0) [0|254] ""  ADU
 SG_ Country_1 m17 : 15|8@0+ (1,0) [0|254] ""  ADU
 SG_ AIC_14 m16 : 63|8@0+ (1,0) [0|254] "" Vector__XXX
 SG_ AIC_13 m16 : 55|8@0+ (1,0) [0|254] "" Vector__XXX
 SG_ AIC_12 m16 : 47|8@0+ (1,0) [0|254] "" Vector__XXX
 SG_ AIC_11 m16 : 39|8@0+ (1,0) [0|254] "" Vector__XXX
 SG_ AIC_10 m16 : 31|8@0+ (1,0) [0|254] "" Vector__XXX
 SG_ AIC_09 m16 : 23|8@0+ (1,0) [0|254] "" Vector__XXX
 SG_ AIC_08 m16 : 15|8@0+ (1,0) [0|254] "" Vector__XXX
 SG_ AIC_07 m6 : 63|8@0+ (1,0) [0|254] "" Vector__XXX
 SG_ AIC_06 m6 : 55|8@0+ (1,0) [0|254] "" Vector__XXX
 SG_ AIC_05 m6 : 47|8@0+ (1,0) [0|254] "" Vector__XXX
 SG_ AIC_04 m6 : 39|8@0+ (1,0) [0|254] "" Vector__XXX
 SG_ AIC_03 m6 : 31|8@0+ (1,0) [0|254] "" Vector__XXX
 SG_ AIC_02 m6 : 23|8@0+ (1,0) [0|254] "" Vector__XXX
 SG_ AIC_01 m6 : 15|8@0+ (1,0) [0|254] "" Vector__XXX
 SG_ Reserved_05_1_40C m5 : 47|24@0+ (1,0) [0|16777214] "" Vector__XXX
 SG_ Project_Code_4th_40C m5 : 39|8@0+ (1,0) [0|254] "" Vector__XXX
 SG_ Project_Code_3rd_40C m5 : 31|8@0+ (1,0) [0|254] "" Vector__XXX
 SG_ Project_Code_2nd_40C m5 : 23|8@0+ (1,0) [0|254] "" Vector__XXX
 SG_ Project_Code_1st_40C m5 : 15|8@0+ (1,0) [0|254] "" Vector__XXX
 SG_ Outer_Color_3_40C m4 : 63|8@0+ (1,0) [0|254] "" Vector__XXX
 SG_ Outer_Color_2_40C m4 : 55|8@0+ (1,0) [0|254] "" Vector__XXX
 SG_ Outer_Color_1_40C m4 : 47|8@0+ (1,0) [0|254] "" Vector__XXX
 SG_ Unit_Serial_Number_40C m4 : 39|8@0+ (1,0) [0|254] "" Vector__XXX
 SG_ Unit_Destination_40C m4 : 31|8@0+ (1,0) [0|254] "" Vector__XXX
 SG_ Unit_Series_40C m4 : 23|8@0+ (1,0) [0|254] "" Vector__XXX
 SG_ Unit_Car_Line_40C m4 : 15|8@0+ (1,0) [0|254] "" Vector__XXX
 SG_ VIN_Character_21_40C m3 : 63|8@0+ (1,0) [0|254] "" Vector__XXX
 SG_ VIN_Character_20_40C m3 : 55|8@0+ (1,0) [0|254] "" Vector__XXX
 SG_ VIN_Character_19_40C m3 : 47|8@0+ (1,0) [0|254] "" Vector__XXX
 SG_ VIN_Character_18_40C m3 : 39|8@0+ (1,0) [0|254] "" Vector__XXX
 SG_ VIN_Character_17_40C m3 : 31|8@0+ (1,0) [0|254] "" Vector__XXX
 SG_ VIN_Character_16_40C m3 : 23|8@0+ (1,0) [0|254] "" Vector__XXX
 SG_ VIN_Character_15_40C m3 : 15|8@0+ (1,0) [0|254] "" Vector__XXX
 SG_ VIN_Character_14_40C m2 : 63|8@0+ (1,0) [0|254] "" Vector__XXX
 SG_ VIN_Character_13_40C m2 : 55|8@0+ (1,0) [0|254] "" Vector__XXX
 SG_ VIN_Character_12_40C m2 : 47|8@0+ (1,0) [0|254] "" Vector__XXX
 SG_ VIN_Character_11_40C m2 : 39|8@0+ (1,0) [0|254] "" Vector__XXX
 SG_ VIN_Character_10_40C m2 : 31|8@0+ (1,0) [0|254] "" Vector__XXX
 SG_ VIN_Character_09_40C m2 : 23|8@0+ (1,0) [0|254] "" Vector__XXX
 SG_ VIN_Character_08_40C m2 : 15|8@0+ (1,0) [0|254] "" Vector__XXX
 SG_ VIN_Character_07_40C m1 : 63|8@0+ (1,0) [0|254] "" Vector__XXX
 SG_ VIN_Character_06_40C m1 : 55|8@0+ (1,0) [0|254] "" Vector__XXX
 SG_ VIN_Character_05_40C m1 : 47|8@0+ (1,0) [0|254] "" Vector__XXX
 SG_ VIN_Character_04_40C m1 : 39|8@0+ (1,0) [0|254] "" Vector__XXX
 SG_ VIN_Character_03_40C m1 : 31|8@0+ (1,0) [0|254] "" Vector__XXX
 SG_ VIN_Character_02_40C m1 : 23|8@0+ (1,0) [0|254] "" Vector__XXX
 SG_ VIN_Character_01_40C m1 : 15|8@0+ (1,0) [0|254] "" Vector__XXX
 SG_ EngRunTimer_40C m243 : 55|16@0+ (1,0) [0|65535] "" Vector__XXX
 SG_ Reserved_F3_2_40C m243 : 47|8@0+ (1,0) [0|255] "" Vector__XXX
 SG_ BrakePedal_40C m243 : 39|8@0+ (1,0) [0|255] "" Vector__XXX
 SG_ Reserved_F3_1_40C m243 : 31|8@0+ (1,0) [0|255] "" Vector__XXX
 SG_ VehicleSpeed_40C m243 : 23|8@0+ (1,0) [0|255] "" Vector__XXX
 SG_ Engine_RPM_40C m243 : 15|8@0+ (1,0) [0|255] "" Vector__XXX
 SG_ ShiftPosition_40C m242 : 63|8@0+ (1,0) [0|255] "" Vector__XXX
 SG_ Engine_Coolant_Temperature_40C m242 : 55|8@0+ (1,-40) [-40|215] "" Vector__XXX
 SG_ AccelPedalPosition_40C m242 : 47|8@0+ (1,0) [0|255] "" Vector__XXX
 SG_ Reserved_F2_1_40C m242 : 39|8@0+ (1,0) [0|255] "" Vector__XXX
 SG_ SOC_40C m242 : 31|8@0+ (1,0) [0|255] "" Vector__XXX
 SG_ IG_OnTimer_40C m242 : 15|16@0+ (1,0) [0|65535] "" Vector__XXX
 SG_ PwMdeExtern_D_Actl_40C m241 : 63|8@0+ (1,0) [0|255] "" Vector__XXX
 SG_ Ambient_Air_Temperature_40C m241 : 55|8@0+ (1,-40) [-40|215] "" Vector__XXX
 SG_ MECU_supply_voltage_40C m241 : 47|8@0+ (1,0) [0|255] "" Vector__XXX
 SG_ VehicleOdometerInformation_40C m241 : 15|32@0+ (1,0) [0|4294967295] "" Vector__XXX
 SG_ SOC2_SS_40C m240 : 63|8@0+ (1,0) [0|255] "" Vector__XXX
 SG_ MotorRPM_SS_40C m240 : 47|16@0+ (1,0) [0|65535] "" Vector__XXX
 SG_ Global_Real_Time_40C m240 : 15|32@0+ (1,0) [0|4294967295] "" Vector__XXX
 SG_ GCC_CfgParam_40C M : 7|8@0+ (1,0) [0|0] ""  ADU

BO_ 1034 GCC_Config_Mgmt: 8 CGW
 SG_ Central_CRC m224 : 55|16@0+ (1,0) [0|65534] ""  ADU
 SG_ CDID_Total_Number m224 : 47|8@0+ (1,0) [0|254] ""  ADU
 SG_ Reserved_E0_2 m224 : 31|16@0+ (1,0) [0|65534] ""  ADU
 SG_ Reserved_E0_1 m224 : 15|16@0+ (1,0) [0|65534] ""  ADU
 SG_ Reserved_95_7 m149 : 63|8@0+ (1,0) [0|254] ""  ADU
 SG_ Reserved_95_6 m149 : 55|8@0+ (1,0) [0|254] ""  ADU
 SG_ Reserved_95_5 m149 : 47|8@0+ (1,0) [0|254] ""  ADU
 SG_ Reserved_95_4 m149 : 39|8@0+ (1,0) [0|254] ""  ADU
 SG_ Reserved_95_3 m149 : 31|8@0+ (1,0) [0|254] ""  ADU
 SG_ Reserved_95_2 m149 : 23|8@0+ (1,0) [0|254] ""  ADU
 SG_ Reserved_95_1 m149 : 15|8@0+ (1,0) [0|254] ""  ADU
 SG_ Reserved_94_7 m148 : 63|8@0+ (1,0) [0|254] ""  ADU
 SG_ Reserved_94_6 m148 : 55|8@0+ (1,0) [0|254] ""  ADU
 SG_ Reserved_94_5 m148 : 47|8@0+ (1,0) [0|254] ""  ADU
 SG_ Reserved_94_4 m148 : 39|8@0+ (1,0) [0|254] ""  ADU
 SG_ Reserved_94_3 m148 : 31|8@0+ (1,0) [0|254] ""  ADU
 SG_ Reserved_94_2 m148 : 23|8@0+ (1,0) [0|254] ""  ADU
 SG_ Reserved_94_1 m148 : 15|8@0+ (1,0) [0|254] ""  ADU
 SG_ Reserved_93_7 m147 : 63|8@0+ (1,0) [0|254] ""  ADU
 SG_ Reserved_93_6 m147 : 55|8@0+ (1,0) [0|254] ""  ADU
 SG_ Reserved_93_5 m147 : 47|8@0+ (1,0) [0|254] ""  ADU
 SG_ Reserved_93_4 m147 : 39|8@0+ (1,0) [0|254] ""  ADU
 SG_ Reserved_93_3 m147 : 31|8@0+ (1,0) [0|254] ""  ADU
 SG_ Reserved_93_2 m147 : 23|8@0+ (1,0) [0|254] ""  ADU
 SG_ Reserved_93_1 m147 : 15|8@0+ (1,0) [0|254] ""  ADU
 SG_ Reserved_92_7 m146 : 63|8@0+ (1,0) [0|254] ""  ADU
 SG_ Reserved_92_6 m146 : 55|8@0+ (1,0) [0|254] ""  ADU
 SG_ Reserved_92_5 m146 : 47|8@0+ (1,0) [0|254] ""  ADU
 SG_ Reserved_92_4 m146 : 39|8@0+ (1,0) [0|254] ""  ADU
 SG_ Reserved_92_3 m146 : 31|8@0+ (1,0) [0|254] ""  ADU
 SG_ Reserved_92_2 m146 : 23|8@0+ (1,0) [0|254] ""  ADU
 SG_ ADAS_VARIATION_1 m146 : 15|8@0+ (1,0) [0|254] ""  ADU
 SG_ Reserved_91_7 m145 : 63|8@0+ (1,0) [0|254] ""  ADU
 SG_ Reserved_91_6 m145 : 55|8@0+ (1,0) [0|254] ""  ADU
 SG_ Reserved_91_5 m145 : 47|8@0+ (1,0) [0|254] ""  ADU
 SG_ Reserved_91_4 m145 : 39|8@0+ (1,0) [0|254] ""  ADU
 SG_ ADAS_COUNTRY_3 m145 : 31|8@0+ (1,0) [0|254] ""  ADU
 SG_ ADAS_COUNTRY_2 m145 : 23|8@0+ (1,0) [0|254] ""  ADU
 SG_ ADAS_COUNTRY_1 m145 : 15|8@0+ (1,0) [0|254] ""  ADU
 SG_ Reserved_90_7 m144 : 63|8@0+ (1,0) [0|254] ""  ADU
 SG_ Reserved_90_6 m144 : 55|8@0+ (1,0) [0|254] ""  ADU
 SG_ PRECEDING_VEHICLE_NOTIFICATION m144 : 47|8@0+ (1,0) [0|254] ""  ADU
 SG_ Reserved_90_4 m144 : 39|8@0+ (1,0) [0|254] ""  ADU
 SG_ Reserved_90_3 m144 : 31|8@0+ (1,0) [0|254] ""  ADU
 SG_ FR_POSITION_TYPE m144 : 23|8@0+ (1,0) [0|254] ""  ADU
 SG_ RBUMPER_SHAPE_TYPE m144 : 15|8@0+ (1,0) [0|254] ""  ADU
 SG_ Reserved_82_8 m130 : 59|4@0+ (1,0) [0|14] ""  ADU
 SG_ IP_DECORATION_ILLUMI m130 : 63|4@0+ (1,0) [0|14] ""  ADU
 SG_ DRIVE_RECORDER m130 : 51|4@0+ (1,0) [0|14] ""  ADU
 SG_ ALEXA m130 : 55|4@0+ (1,0) [0|14] ""  ADU
 SG_ ASE_SYSTEM m130 : 43|4@0+ (1,0) [0|14] ""  ADU
 SG_ WIRELESS_CHARGE m130 : 47|4@0+ (1,0) [0|14] ""  ADU
 SG_ FBUMPER_ASSY_TYPE m130 : 35|4@0+ (1,0) [0|14] ""  ADU
 SG_ FBUMPER_SHAPE_TYPE m130 : 39|4@0+ (1,0) [0|14] ""  ADU
 SG_ EMERGENCY_DRIVER_ASSIST m130 : 27|4@0+ (1,0) [0|14] ""  ADU
 SG_ VMC_COMMUNICATION_TYPE m130 : 31|4@0+ (1,0) [0|14] ""  ADU
 SG_ VMC_POSITION m130 : 17|2@0+ (1,0) [0|2] ""  ADU
 SG_ Reserved_82_3 m130 : 19|2@0+ (1,0) [0|2] ""  ADU
 SG_ INTERSECTION_BRAKE_SUPP m130 : 23|4@0+ (1,0) [0|14] ""  ADU
 SG_ PERSONALIZE_SYSTEM m130 : 11|4@0+ (1,0) [0|14] ""  ADU
 SG_ TAP m130 : 15|4@0+ (1,0) [0|14] ""  ADU
 SG_ Reserved_80_5 m128 : 59|4@0+ (1,0) [0|14] ""  ADU
 SG_ ENGINE_POWER_TYPE m128 : 63|4@0+ (1,0) [0|14] ""  ADU
 SG_ Number_Of_Cylinders m128 : 51|4@0+ (1,0) [0|14] ""  ADU
 SG_ TURBO_ENGINE m128 : 55|4@0+ (1,0) [0|14] ""  ADU
 SG_ CYLINDER_DEACTIVATION m128 : 43|4@0+ (1,0) [0|14] ""  ADU
 SG_ UPGRADE_ENGINE m128 : 47|4@0+ (1,0) [0|14] ""  ADU
 SG_ ENGINE_TYPE m128 : 39|8@0+ (1,0) [0|254] ""  ADU
 SG_ Reserved_80_3 m128 : 27|4@0+ (1,0) [0|14] ""  ADU
 SG_ AC_CHARGING_TYPE m128 : 31|4@0+ (1,0) [0|14] ""  ADU
 SG_ DC_CHARGING_TYPE m128 : 19|4@0+ (1,0) [0|14] ""  ADU
 SG_ AUX_POWER_UNIT m128 : 23|4@0+ (1,0) [0|14] ""  ADU
 SG_ Reserved_80_1 m128 : 11|4@0+ (1,0) [0|14] ""  ADU
 SG_ XEV_TYPE m128 : 15|4@0+ (1,0) [0|14] ""  ADU
 SG_ Reserved_72_3 m114 : 55|16@0+ (1,0) [0|65535] ""  ADU
 SG_ Reserved_72_4 m114 : 41|2@0+ (1,0) [0|2] ""  ADU
 SG_ REMOTE_ENGINE_START_OPT m114 : 43|2@0+ (1,0) [0|2] ""  ADU
 SG_ DOWN_LIGHT m114 : 45|2@0+ (1,0) [0|2] ""  ADU
 SG_ KEYLESS_WINDOW_CONTROL m114 : 47|2@0+ (1,0) [0|2] ""  ADU
 SG_ KEY_LESS_COMPT m114 : 33|2@0+ (1,0) [0|2] ""  ADU
 SG_ SMART_KEYLESS m114 : 35|2@0+ (1,0) [0|2] ""  ADU
 SG_ KEY_LESS_ENTRY m114 : 39|4@0+ (1,0) [0|14] ""  ADU
 SG_ Reserved_72_2 m114 : 27|4@0+ (1,0) [0|14] ""  ADU
 SG_ PGR_AIR_BAG_CUT_INDICATOR m114 : 31|4@0+ (1,0) [0|14] ""  ADU
 SG_ REMINDER_CONTROL_SPEC m114 : 23|8@0+ (1,0) [0|254] ""  ADU
 SG_ SEAT_BELT_WARNING_SYSTEM m114 : 11|4@0+ (1,0) [0|14] ""  ADU
 SG_ OCCUPANT_SENSING_SYSTEM m114 : 15|4@0+ (1,0) [0|14] ""  ADU
 SG_ Reserved_70_4 m112 : 63|8@0+ (1,0) [0|254] ""  ADU
 SG_ R_SEAT_NO2_TYPE m112 : 51|4@0+ (1,0) [0|14] ""  ADU
 SG_ R_SEAT_NO1_TYPE m112 : 55|4@0+ (1,0) [0|14] ""  ADU
 SG_ EXTERIOR_ALERT_TYPE m112 : 43|4@0+ (1,0) [0|14] ""  ADU
 SG_ CPD_CONTROL_TYPE m112 : 47|4@0+ (1,0) [0|14] ""  ADU
 SG_ Reserved_70_3 m112 : 33|2@0+ (1,0) [0|2] ""  ADU
 SG_ F_SEAT_VENTILATION m112 : 35|2@0+ (1,0) [0|2] ""  ADU
 SG_ F_SEAT_TYPE m112 : 39|4@0+ (1,0) [0|14] ""  ADU
 SG_ Reserved_70_2 m112 : 25|2@0+ (1,0) [0|2] ""  ADU
 SG_ R_SEAT_WARMER m112 : 27|2@0+ (1,0) [0|2] ""  ADU
 SG_ F_SEAT_WARMER m112 : 31|4@0+ (1,0) [0|14] ""  ADU
 SG_ Reserved_70_1 m112 : 19|4@0+ (1,0) [0|14] ""  ADU
 SG_ F_SEAT_LIFT_MECHANISM m112 : 23|4@0+ (1,0) [0|14] ""  ADU
 SG_ SEAT_MATERIAL m112 : 15|8@0+ (1,0) [0|254] ""  ADU
 SG_ Reserved_63_1 m99 : 63|8@0+ (1,0) [0|254] ""  ADU
 SG_ Vehicle_Height m99 : 47|16@0+ (1,0) [0|65534] ""  ADU
 SG_ Vehicle_Width m99 : 31|16@0+ (1,0) [0|65534] ""  ADU
 SG_ Vehicle_Length m99 : 15|16@0+ (1,0) [0|65534] ""  ADU
 SG_ Reserved_62_2 m98 : 57|2@0+ (1,0) [0|2] ""  ADU
 SG_ TOUCH_PANEL m98 : 59|2@0+ (1,0) [0|2] ""  ADU
 SG_ DISPLAY_SIZE m98 : 63|4@0+ (1,0) [0|14] ""  ADU
 SG_ HD_Radio m98 : 49|2@0+ (1,0) [0|2] ""  ADU
 SG_ TELEMATICS_COM_UNIT m98 : 51|2@0+ (1,0) [0|2] ""  ADU
 SG_ B_CALL m98 : 43|8@0+ (1,0) [0|254] ""  ADU
 SG_ CMU_Spec m98 : 47|4@0+ (1,0) [0|14] ""  ADU
 SG_ Number_Of_Seat_Rows m98 : 33|2@0+ (1,0) [0|2] ""  ADU
 SG_ Tuner_AM_Range m98 : 35|2@0+ (1,0) [0|2] ""  ADU
 SG_ Pandora m98 : 37|2@0+ (1,0) [0|2] ""  ADU
 SG_ Mobile_911 m98 : 39|2@0+ (1,0) [0|2] ""  ADU
 SG_ HDMI m98 : 25|2@0+ (1,0) [0|2] ""  ADU
 SG_ LW m98 : 27|2@0+ (1,0) [0|2] ""  ADU
 SG_ Limit_Of_DAB_Range m98 : 31|4@0+ (1,0) [0|14] ""  ADU
 SG_ ELK_CUSTOMIZE_TYPE m98 : 17|2@0+ (1,0) [0|2] ""  ADU
 SG_ Microphone m98 : 19|2@0+ (1,0) [0|2] ""  ADU
 SG_ DAA_Default m98 : 21|2@0+ (1,0) [0|2] ""  ADU
 SG_ Carplay m98 : 23|2@0+ (1,0) [0|2] ""  ADU
 SG_ Android_Auto m98 : 9|2@0+ (1,0) [0|2] ""  ADU
 SG_ Wi_Fi_Frequency m98 : 11|2@0+ (1,0) [0|2] ""  ADU
 SG_ Commander_Touchpad m98 : 13|2@0+ (1,0) [0|2] ""  ADU
 SG_ TPEG m98 : 15|2@0+ (1,0) [0|2] ""  ADU
 SG_ Reserved_60_1 m96 : 63|8@0+ (1,0) [0|254] ""  ADU
 SG_ SIGN_DISPLAY m96 : 51|4@0+ (1,0) [0|14] ""  ADU
 SG_ UI_RESTRICTION m96 : 55|4@0+ (1,0) [0|14] ""  ADU
 SG_ ADAS_MAP_SYSTEM m96 : 43|4@0+ (1,0) [0|14] ""  ADU
 SG_ RDS_SPEC m96 : 47|4@0+ (1,0) [0|14] ""  ADU
 SG_ EMERGENCY_CALL m96 : 35|4@0+ (1,0) [0|14] ""  ADU
 SG_ SATELITE_SPEC m96 : 39|4@0+ (1,0) [0|14] ""  ADU
 SG_ NAVI_MAP_DATA m96 : 27|4@0+ (1,0) [0|14] ""  ADU
 SG_ CD_Ripping m96 : 29|2@0+ (1,0) [0|2] ""  ADU
 SG_ TV_TUNER m96 : 31|2@0+ (1,0) [0|2] ""  ADU
 SG_ SPEAKER_TYPE m96 : 19|4@0+ (1,0) [0|14] ""  ADU
 SG_ DVD m96 : 21|2@0+ (1,0) [0|2] ""  ADU
 SG_ CD m96 : 23|2@0+ (1,0) [0|2] ""  ADU
 SG_ FREQUENCY m96 : 11|4@0+ (1,0) [0|14] ""  ADU
 SG_ RDS m96 : 13|2@0+ (1,0) [0|2] ""  ADU
 SG_ DAB m96 : 15|2@0+ (1,0) [0|2] ""  ADU
 SG_ Reserved_52_6 m82 : 63|8@0+ (1,0) [0|254] ""  ADU
 SG_ AT_SHIFT_SW m82 : 51|4@0+ (1,0) [0|14] ""  ADU
 SG_ ELECTRIC_SHIFT m82 : 55|4@0+ (1,0) [0|14] ""  ADU
 SG_ Reserved_52_5 m82 : 41|2@0+ (1,0) [0|2] ""  ADU
 SG_ STG_WHEEL_WARMER m82 : 43|2@0+ (1,0) [0|2] ""  ADU
 SG_ TILT_STG m82 : 47|4@0+ (1,0) [0|14] ""  ADU
 SG_ Reserved_52_4 m82 : 39|8@0+ (1,0) [0|254] ""  ADU
 SG_ DRIVE_SELECTION_MODE m82 : 27|4@0+ (1,0) [0|14] ""  ADU
 SG_ Reserved_52_3 m82 : 29|2@0+ (1,0) [0|2] ""  ADU
 SG_ DRIVE_SELECTION m82 : 31|2@0+ (1,0) [0|2] ""  ADU
 SG_ I_DM m82 : 17|2@0+ (1,0) [0|2] ""  ADU
 SG_ Reserved_52_2 m82 : 19|2@0+ (1,0) [0|2] ""  ADU
 SG_ OVER_HEAD_CONSOLE m82 : 23|4@0+ (1,0) [0|14] ""  ADU
 SG_ AT_INTERLOCK_UNLOCK_SYS m82 : 11|4@0+ (1,0) [0|14] ""  ADU
 SG_ BURGLAR_ALARM_SYSTEM m82 : 15|4@0+ (1,0) [0|14] ""  ADU
 SG_ Reserved_50_3 m80 : 47|24@0+ (1,0) [0|16777214] ""  ADU
 SG_ TSR_GSR_TYPE m80 : 35|4@0+ (1,0) [0|14] ""  ADU
 SG_ SPEED_METER m80 : 39|4@0+ (1,0) [0|14] ""  ADU
 SG_ FUEL_CONSUMPTION_UNIT m80 : 27|4@0+ (1,0) [0|14] ""  ADU
 SG_ TRIP_COMPUTER m80 : 31|4@0+ (1,0) [0|14] ""  ADU
 SG_ HEAD_UP_DISPLAY m80 : 17|2@0+ (1,0) [0|2] ""  ADU
 SG_ WARNING_BUZZER_120KMH m80 : 19|2@0+ (1,0) [0|2] ""  ADU
 SG_ TURN_SIGNAL_SWITCH m80 : 21|2@0+ (1,0) [0|2] ""  ADU
 SG_ Reserved_50_1 m80 : 23|2@0+ (1,0) [0|2] ""  ADU
 SG_ MULTI_DOT_DISPLAY m80 : 9|2@0+ (1,0) [0|2] ""  ADU
 SG_ Reserved_50_4 m80 : 11|2@0+ (1,0) [0|2] ""  ADU
 SG_ IND_STD_OF_SPEED_METER m80 : 15|4@0+ (1,0) [0|14] ""  ADU
 SG_ Reserved_40_4 m64 : 55|16@0+ (1,0) [0|65535] ""  ADU
 SG_ F_EX_MIRROR_AUTO_FOLD m64 : 41|2@0+ (1,0) [0|2] ""  ADU
 SG_ F_EXT_MIRROR_ADJ_MEMORY m64 : 43|2@0+ (1,0) [0|2] ""  ADU
 SG_ F_EXT_MIRROR_HEATER m64 : 45|2@0+ (1,0) [0|2] ""  ADU
 SG_ F_EX_MIRROR_POWER_FOLD m64 : 47|2@0+ (1,0) [0|2] ""  ADU
 SG_ Reserved_40_3 m64 : 31|16@0+ (1,0) [0|65534] ""  ADU
 SG_ R_SEAT_NO1_SEAT_TRACK m64 : 19|4@0+ (1,0) [0|14] ""  ADU
 SG_ ONE_TOUCH_SYSTEM m64 : 23|4@0+ (1,0) [0|14] ""  ADU
 SG_ R_SEAT_VENTILATION m64 : 9|2@0+ (1,0) [0|2] ""  ADU
 SG_ WASHER_LEVEL_LAMP m64 : 11|2@0+ (1,0) [0|2] ""  ADU
 SG_ F_WIPER_INTERMITTENT m64 : 15|4@0+ (1,0) [0|14] ""  ADU
 SG_ Reserved_30_6 m48 : 63|8@0+ (1,0) [0|254] ""  ADU
 SG_ AUTO_DOOR_LOCK m48 : 51|4@0+ (1,0) [0|14] ""  ADU
 SG_ Reserved_30_5 m48 : 53|2@0+ (1,0) [0|2] ""  ADU
 SG_ SUPER_LOCK_SYSTEM m48 : 55|2@0+ (1,0) [0|2] ""  ADU
 SG_ POWER_DOOR_LOCK_SW m48 : 43|4@0+ (1,0) [0|14] ""  ADU
 SG_ POWER_DOOR_LOCK m48 : 47|4@0+ (1,0) [0|14] ""  ADU
 SG_ Reserved_30_4 m48 : 39|8@0+ (1,0) [0|254] ""  ADU
 SG_ Reserved_30_3 m48 : 29|6@0+ (1,0) [0|62] ""  ADU
 SG_ POWER_BACK_DOOR m48 : 31|2@0+ (1,0) [0|2] ""  ADU
 SG_ Reserved_30_2 m48 : 23|8@0+ (1,0) [0|254] ""  ADU
 SG_ Reserved_30_1 m48 : 11|4@0+ (1,0) [0|14] ""  ADU
 SG_ TRUNK_LID_OPENER m48 : 15|4@0+ (1,0) [0|14] ""  ADU
 SG_ Reserved_25_4 m37 : 47|24@0+ (1,0) [0|16777214] ""  ADU
 SG_ DEFAULT_ONE_TOUCH_TURN m37 : 33|2@0+ (1,0) [0|2] ""  ADU
 SG_ ESS m37 : 35|2@0+ (1,0) [0|2] ""  ADU
 SG_ R_FOG_LAMP m37 : 37|2@0+ (1,0) [0|2] ""  ADU
 SG_ F_FOG_LAMP m37 : 39|2@0+ (1,0) [0|2] ""  ADU
 SG_ Reserved_25_3 m37 : 27|4@0+ (1,0) [0|14] ""  ADU
 SG_ PASSIVE_COLLISION_SIGNAL m37 : 31|4@0+ (1,0) [0|14] ""  ADU
 SG_ F_AND_R_SIDE_MARKER_US m37 : 17|2@0+ (1,0) [0|2] ""  ADU
 SG_ AUTO_HEAD_LAMP_ON_OFF m37 : 19|2@0+ (1,0) [0|2] ""  ADU
 SG_ RUNNING_LAMP_CUSTOMIZE m37 : 23|4@0+ (1,0) [0|14] ""  ADU
 SG_ F_COMBI_SIGNATURE_ILLUMI m37 : 9|2@0+ (1,0) [0|2] ""  ADU
 SG_ HEAD_LAMP_CLEANER m37 : 11|2@0+ (1,0) [0|2] ""  ADU
 SG_ Headlamp_Control m37 : 15|4@0+ (1,0) [0|14] ""  ADU
 SG_ Reserved_20_3 m32 : 55|16@0+ (1,0) [0|65535] ""  ADU
 SG_ AC_Refrigerant_Gas m32 : 43|4@0+ (1,0) [0|14] ""  ADU
 SG_ AC_Compressor m32 : 47|4@0+ (1,0) [0|14] ""  ADU
 SG_ Reserved_20_2 m32 : 35|4@0+ (1,0) [0|14] ""  ADU
 SG_ SERVER_REGION m32 : 39|4@0+ (1,0) [0|14] ""  ADU
 SG_ DEFROSTER_CIRCULATION_CONTROL m32 : 27|4@0+ (1,0) [0|14] ""  ADU
 SG_ TEMPERATURE_SETTING_RANGE m32 : 31|4@0+ (1,0) [0|14] ""  ADU
 SG_ Reserved_20_1 m32 : 17|2@0+ (1,0) [0|2] ""  ADU
 SG_ PreAirCon_OperatingTime m32 : 21|4@0+ (1,0) [0|14] ""  ADU
 SG_ R_VENT_COOLER m32 : 23|2@0+ (1,0) [0|2] ""  ADU
 SG_ HUMIDITY_SENSOR m32 : 9|2@0+ (1,0) [0|2] ""  ADU
 SG_ PTC_HEATER m32 : 11|2@0+ (1,0) [0|2] ""  ADU
 SG_ F_AIR_CONDITIONER m32 : 15|4@0+ (1,0) [0|14] ""  ADU
 SG_ Reserved_16_3 m22 : 47|24@0+ (1,0) [0|16777214] ""  ADU
 SG_ Reserved_16_2 m22 : 35|4@0+ (1,0) [0|14] ""  ADU
 SG_ OCCUPANT_MONITOR_SYSTEM m22 : 37|2@0+ (1,0) [0|2] ""  ADU
 SG_ FRONT_SIDE_RADAR m22 : 39|2@0+ (1,0) [0|2] ""  ADU
 SG_ TJA_TYPE m22 : 27|4@0+ (1,0) [0|14] ""  ADU
 SG_ VIEW_MONITOR_CAMERA m22 : 31|4@0+ (1,0) [0|14] ""  ADU
 SG_ FRONT_REAR_SIDE_SONAR m22 : 19|4@0+ (1,0) [0|14] ""  ADU
 SG_ DRIVER_MONITOR m22 : 21|2@0+ (1,0) [0|2] ""  ADU
 SG_ FRONT_CROSS_TRAFFIC_ALERT m22 : 23|2@0+ (1,0) [0|2] ""  ADU
 SG_ INTERSECTION_BRAKE_TYPE m22 : 11|4@0+ (1,0) [0|14] ""  ADU
 SG_ BLIND_SPOT_PREVENTION m22 : 13|2@0+ (1,0) [0|2] ""  ADU
 SG_ Reserved_16_1 m22 : 15|2@0+ (1,0) [0|2] ""  ADU
 SG_ Reserved_15_3 m21 : 47|24@0+ (1,0) [0|16777214] ""  ADU
 SG_ SBS_VRU_TYPE m21 : 35|4@0+ (1,0) [0|14] ""  ADU
 SG_ ADAS_REGULATION_TYPE m21 : 39|4@0+ (1,0) [0|14] ""  ADU
 SG_ REMOTE_PARKING m21 : 25|2@0+ (1,0) [0|2] ""  ADU
 SG_ AUTO_PARKING m21 : 27|2@0+ (1,0) [0|2] ""  ADU
 SG_ ACCELERATION_RESTRAINT m21 : 31|4@0+ (1,0) [0|14] ""  ADU
 SG_ REAR_SONAR m21 : 19|4@0+ (1,0) [0|14] ""  ADU
 SG_ FRONT_SONAR m21 : 23|4@0+ (1,0) [0|14] ""  ADU
 SG_ PARKING_SENSOR m21 : 11|4@0+ (1,0) [0|14] ""  ADU
 SG_ REAR_DIRECTION_BASE_SAFETY m21 : 15|4@0+ (1,0) [0|14] ""  ADU
 SG_ Reserved_14_2 m20 : 59|4@0+ (1,0) [0|14] ""  ADU
 SG_ SBS_TARGET_TYPE m20 : 63|4@0+ (1,0) [0|14] ""  ADU
 SG_ IACC_TYPE m20 : 51|4@0+ (1,0) [0|14] ""  ADU
 SG_ HEAD_ON m20 : 55|4@0+ (1,0) [0|14] ""  ADU
 SG_ LAS_TYPE m20 : 43|4@0+ (1,0) [0|14] ""  ADU
 SG_ MRCC_TYPE m20 : 47|4@0+ (1,0) [0|14] ""  ADU
 SG_ Reserved_14_1 m20 : 33|2@0+ (1,0) [0|2] ""  ADU
 SG_ BLIND_SPOT_MONITORING m20 : 35|2@0+ (1,0) [0|2] ""  ADU
 SG_ REAR_SIDE_RADAR m20 : 37|2@0+ (1,0) [0|2] ""  ADU
 SG_ FRONT_RADAR m20 : 39|2@0+ (1,0) [0|2] ""  ADU
 SG_ ADJUSTABLE_SPEED_LIMITER m20 : 27|4@0+ (1,0) [0|14] ""  ADU
 SG_ AUTO_CRUISER m20 : 31|4@0+ (1,0) [0|14] ""  ADU
 SG_ DAS_TYPE m20 : 19|4@0+ (1,0) [0|14] ""  ADU
 SG_ DRIVER_ATTENTION_ALERT m20 : 21|2@0+ (1,0) [0|2] ""  ADU
 SG_ TRAFFIC_SIGN_RECOGNITION m20 : 23|2@0+ (1,0) [0|2] ""  ADU
 SG_ FRONT_DIRECTION_BASE_SAFETY m20 : 11|4@0+ (1,0) [0|14] ""  ADU
 SG_ HIGH_BEAM_CONTROL m20 : 13|2@0+ (1,0) [0|2] ""  ADU
 SG_ FORWARD_SENSING_CAMERA m20 : 15|2@0+ (1,0) [0|2] ""  ADU
 SG_ Reserved_13_3 m19 : 47|24@0+ (1,0) [0|16777214] ""  ADU
 SG_ Reserved_13_2 m19 : 39|8@0+ (1,0) [0|254] ""  ADU
 SG_ Reserved_13_1 m19 : 27|4@0+ (1,0) [0|14] ""  ADU
 SG_ F_TIRE_SIZE m19 : 31|4@0+ (1,0) [0|14] ""  ADU
 SG_ Tire_Circumference m19 : 15|16@0+ (1,0) [0|65535] ""  ADU
 SG_ Reserved_12_3 m18 : 55|16@0+ (1,0) [0|65535] ""  ADU
 SG_ EPS_Assist_Map m18 : 47|8@0+ (1,0) [0|254] ""  ADU
 SG_ Reserved_12_2 m18 : 31|16@0+ (1,0) [0|65535] ""  ADU
 SG_ Booster_Failure_Support m18 : 17|2@0+ (1,0) [0|2] ""  ADU
 SG_ DYC m18 : 19|2@0+ (1,0) [0|2] ""  ADU
 SG_ Brake_Pad_Material m18 : 23|4@0+ (1,0) [0|14] ""  ADU
 SG_ Rear_Brake_Size m18 : 11|4@0+ (1,0) [0|14] ""  ADU
 SG_ Front_Brake_Size m18 : 15|4@0+ (1,0) [0|14] ""  ADU
 SG_ Reserved_11_4 m17 : 55|16@0+ (1,0) [0|65535] ""  ADU
 SG_ NVH_SPEC m17 : 43|4@0+ (1,0) [0|14] ""  ADU
 SG_ TIRE_PRESSURE_MONITOR_S m17 : 47|4@0+ (1,0) [0|14] ""  ADU
 SG_ Reserved_11_2 m17 : 31|16@0+ (1,0) [0|65535] ""  ADU
 SG_ BATTERY_HEATER m17 : 19|4@0+ (1,0) [0|14] ""  ADU
 SG_ Reserved_11_1 m17 : 21|2@0+ (1,0) [0|2] ""  ADU
 SG_ TSA m17 : 23|2@0+ (1,0) [0|2] ""  ADU
 SG_ AUTO_HOLD m17 : 9|2@0+ (1,0) [0|2] ""  ADU
 SG_ EPB m17 : 11|2@0+ (1,0) [0|2] ""  ADU
 SG_ Brake_Control m17 : 15|4@0+ (1,0) [0|14] ""  ADU
 SG_ Reserved_10_2 m16 : 55|16@0+ (1,0) [0|65534] ""  ADU
 SG_ OBD_CONFIG_INFORMATION m16 : 43|4@0+ (1,0) [0|14] ""  ADU
 SG_ CLOSED_FUEL_TANK_SYSTEM m16 : 47|4@0+ (1,0) [0|14] ""  ADU
 SG_ BEV_MAINTENANCE_LIMIT m16 : 39|8@0+ (1,0) [0|254] ""  ADU
 SG_ Reserved_10_1 m16 : 19|12@0+ (1,0) [0|4094] ""  ADU
 SG_ E_OIL_MAINTENANCE_LIMIT m16 : 23|4@0+ (1,0) [0|14] ""  ADU
 SG_ REGENERATION_TYPE m16 : 11|4@0+ (1,0) [0|14] ""  ADU
 SG_ I_STOP_TYPE m16 : 15|4@0+ (1,0) [0|14] ""  ADU
 SG_ Reserved_06_2 m6 : 55|16@0+ (1,0) [0|65535] ""  ADU
 SG_ DEVELOPMENT_FUEL m6 : 43|4@0+ (1,0) [0|14] ""  ADU
 SG_ PLANT m6 : 47|4@0+ (1,0) [0|14] ""  ADU
 SG_ Reserved_06_1 m6 : 33|2@0+ (1,0) [0|2] ""  ADU
 SG_ Steering_Position m6 : 35|2@0+ (1,0) [0|2] ""  ADU
 SG_ ROOF m6 : 39|4@0+ (1,0) [0|14] ""  ADU
 SG_ TRANSMISSION m6 : 25|2@0+ (1,0) [0|2] ""  ADU
 SG_ DRIVE m6 : 27|2@0+ (1,0) [0|2] ""  ADU
 SG_ ENGINE m6 : 31|4@0+ (1,0) [0|14] ""  ADU
 SG_ BODY m6 : 19|4@0+ (1,0) [0|14] ""  ADU
 SG_ BRAND m6 : 23|4@0+ (1,0) [0|14] ""  ADU
 SG_ MARKET m6 : 15|8@0+ (1,0) [0|254] ""  ADU
 SG_ Reserved_05_1 m5 : 47|24@0+ (1,0) [0|16777214] ""  ADU
 SG_ Project_Code_4th m5 : 39|8@0+ (1,0) [0|254] ""  ADU
 SG_ Project_Code_3rd m5 : 31|8@0+ (1,0) [0|254] ""  ADU
 SG_ Project_Code_2nd m5 : 23|8@0+ (1,0) [0|254] ""  ADU
 SG_ Project_Code_1st m5 : 15|8@0+ (1,0) [0|254] ""  ADU
 SG_ Outer_Color_3 m4 : 63|8@0+ (1,0) [0|254] ""  ADU
 SG_ Outer_Color_2 m4 : 55|8@0+ (1,0) [0|254] ""  ADU
 SG_ Outer_Color_1 m4 : 47|8@0+ (1,0) [0|254] ""  ADU
 SG_ Unit_Serial_Number m4 : 39|8@0+ (1,0) [0|254] ""  ADU
 SG_ Unit_Destination m4 : 31|8@0+ (1,0) [0|254] ""  ADU
 SG_ Unit_Series m4 : 23|8@0+ (1,0) [0|254] ""  ADU
 SG_ Unit_Car_Line m4 : 15|8@0+ (1,0) [0|254] ""  ADU
 SG_ VIN_Character_21 m3 : 63|8@0+ (1,0) [0|254] ""  ADU
 SG_ VIN_Character_20 m3 : 55|8@0+ (1,0) [0|254] ""  ADU
 SG_ VIN_Character_19 m3 : 47|8@0+ (1,0) [0|254] ""  ADU
 SG_ VIN_Character_18 m3 : 39|8@0+ (1,0) [0|254] ""  ADU
 SG_ VIN_Character_17 m3 : 31|8@0+ (1,0) [0|254] ""  ADU
 SG_ VIN_Character_16 m3 : 23|8@0+ (1,0) [0|254] ""  ADU
 SG_ VIN_Character_15 m3 : 15|8@0+ (1,0) [0|254] ""  ADU
 SG_ VIN_Character_14 m2 : 63|8@0+ (1,0) [0|254] ""  ADU
 SG_ VIN_Character_13 m2 : 55|8@0+ (1,0) [0|254] ""  ADU
 SG_ VIN_Character_12 m2 : 47|8@0+ (1,0) [0|254] ""  ADU
 SG_ VIN_Character_11 m2 : 39|8@0+ (1,0) [0|254] ""  ADU
 SG_ VIN_Character_10 m2 : 31|8@0+ (1,0) [0|254] ""  ADU
 SG_ VIN_Character_09 m2 : 23|8@0+ (1,0) [0|254] ""  ADU
 SG_ VIN_Character_08 m2 : 15|8@0+ (1,0) [0|254] ""  ADU
 SG_ VIN_Character_07 m1 : 63|8@0+ (1,0) [0|254] ""  ADU
 SG_ VIN_Character_06 m1 : 55|8@0+ (1,0) [0|254] ""  ADU
 SG_ VIN_Character_05 m1 : 47|8@0+ (1,0) [0|254] ""  ADU
 SG_ VIN_Character_04 m1 : 39|8@0+ (1,0) [0|254] ""  ADU
 SG_ VIN_Character_03 m1 : 31|8@0+ (1,0) [0|254] ""  ADU
 SG_ VIN_Character_02 m1 : 23|8@0+ (1,0) [0|254] ""  ADU
 SG_ VIN_Character_01 m1 : 15|8@0+ (1,0) [0|254] ""  ADU
 SG_ EngRunTimer m243 : 55|16@0+ (1,0) [0|65535] ""  ADU
 SG_ Reserved_F3_2 m243 : 47|8@0+ (1,0) [0|255] ""  ADU
 SG_ BrakePedal m243 : 39|8@0+ (1,0) [0|255] ""  ADU
 SG_ Reserved_F3_1 m243 : 31|8@0+ (1,0) [0|255] ""  ADU
 SG_ VehicleSpeed m243 : 23|8@0+ (1,0) [0|255] ""  ADU
 SG_ Engine_RPM m243 : 15|8@0+ (1,0) [0|255] ""  ADU
 SG_ ShiftPosition m242 : 63|8@0+ (1,0) [0|255] ""  ADU
 SG_ Engine_Coolant_Temperature m242 : 55|8@0+ (1,-40) [-40|215] ""  ADU
 SG_ AccelPedalPosition m242 : 47|8@0+ (1,0) [0|255] ""  ADU
 SG_ Reserved_F2_1 m242 : 39|8@0+ (1,0) [0|255] ""  ADU
 SG_ SOC m242 : 31|8@0+ (1,0) [0|255] ""  ADU
 SG_ IG_OnTimer m242 : 15|16@0+ (1,0) [0|65535] ""  ADU
 SG_ PwMdeExtern_D_Actl m241 : 63|8@0+ (1,0) [0|255] ""  ADU
 SG_ Ambient_Air_Temperature m241 : 55|8@0+ (1,-40) [-40|215] ""  ADU
 SG_ MECU_supply_voltage m241 : 47|8@0+ (1,0) [0|255] ""  ADU
 SG_ Vehicle_Odometer_Information m241 : 15|32@0+ (1,0) [0|4294967295] ""  ADU
 SG_ SOC2_SS m240 : 63|8@0+ (1,0) [0|255] ""  ADU
 SG_ MotorRPM_SS m240 : 47|16@0+ (1,0) [0|65535] ""  ADU
 SG_ Global_Real_Time m240 : 15|32@0+ (1,0) [0|4294967295] ""  ADU
 SG_ GCC_CfgParam M : 7|8@0+ (1,0) [0|0] ""  ADU

BO_ 1033 ADU1S04: 32 ADU
 SG_ MOURELV : 33|4@0+ (1,0) [0|0] ""  CGW
 SG_ EYERELV : 37|4@0+ (1,0) [0|0] ""  CGW
 SG_ F_RL_OFS : 25|4@0+ (1,0) [0|15] "deg"  CGW
 SG_ F_YW_OFS : 29|4@0+ (1,0) [0|15] "deg"  CGW
 SG_ F_PT_OFS : 19|6@0+ (1,0) [0|63] "deg"  CGW
 SG_ DMCFAIL : 9|6@0+ (1,0) [0|63] ""  CGW
 SG_ S_SMOKE : 10|1@0+ (1,0) [0|0] ""  CGW
 SG_ S_SDIST : 11|1@0+ (1,0) [0|0] ""  CGW
 SG_ S_PHONE : 12|1@0+ (1,0) [0|0] ""  CGW
 SG_ S_ABUSE : 13|1@0+ (1,0) [0|0] ""  CGW
 SG_ WL_SDIST : 15|2@0+ (1,0) [0|0] ""  CGW
 SG_ WL_ABUSE : 1|2@0+ (1,0) [0|0] ""  CGW
 SG_ WNGVALID : 4|3@0+ (1,0) [0|0] ""  CGW
 SG_ GAZEFLAG : 7|3@0+ (1,0) [0|0] ""  CGW

BO_ 1032 ADU1S03: 32 ADU
 SG_ ACCMMOD : 1|2@0+ (1,0) [0|0] ""  CGW
 SG_ ACCMAPP : 4|3@0+ (1,0) [0|0] ""  CGW

BA_DEF_REL_ BU_SG_REL_  "SC_Verification" ENUM  "No","Yes";
BA_DEF_ BO_  "SCP_FreshnessValueTxLength" INT 0 512;
BA_DEF_ BO_  "SCP_FreshnessValueLength" INT 0 512;
BA_DEF_ BO_  "SCP_DataId" INT 0 65535;
BA_DEF_ BO_  "SCP_AuthInfoTxLength" INT 0 512;
BA_DEF_ BO_  "SC_Message" ENUM  "No","Yes";
BA_DEF_ BO_  "CANFD_BRS" ENUM  "0","1";
BA_DEF_ BO_  "VFrameFormat" ENUM  "StandardCAN","ExtendedCAN","reserved","reserved","reserved","reserved","reserved","reserved","reserved","reserved","reserved","reserved","reserved","reserved","StandardCAN_FD","ExtendedCAN_FD";
BA_DEF_ BO_  "DiagRequest" ENUM  "No","Yes";
BA_DEF_ BO_  "DiagResponse" ENUM  "No","Yes";
BA_DEF_ BO_  "DiagState" ENUM  "No","Yes";
BA_DEF_ BO_  "DiagConnection" INT 0 65535;
BA_DEF_ BO_  "GenMsgCycleTime" INT 0 10000;
BA_DEF_ BO_  "GenMsgCycleTimeFast" INT 0 100000;
BA_DEF_ BO_  "GenMsgDelayTime" INT 0 1000;
BA_DEF_ BO_  "GenMsgILSupport" ENUM  "No","Yes";
BA_DEF_ BO_  "GenMsgNrOfRepetition" INT 0 100;
BA_DEF_ BO_  "GenMsgSendType" ENUM  "FixedPeriodic","Event","EnabledPeriodic","NotUsed","NotUsed","EventPeriodic","NotUsed","NotUsed","NoMsgSendType";
BA_DEF_ SG_  "GenSigSendType" ENUM  "Cyclic","OnWrite","OnWriteWithRepetition","OnChange","OnChangeWithRepetition","IfActive","IfActiveWithRepetition","NoSigSendType";
BA_DEF_ SG_  "GenSigStartValue" FLOAT 0 1E+011;
BA_DEF_ SG_  "GenSigTimeoutTime_CGW" INT 0 100000;
BA_DEF_ SG_  "GenSigTimeoutTime_ADU" INT 0 100000;
BA_DEF_ BO_  "NetworkInitialization" ENUM  "No","Yes";
BA_DEF_ SG_  "GenSigEnvVarType" ENUM  "int","float","undef";
BA_DEF_ SG_  "NWM-WakeupAllowed" ENUM  "No","Yes";
BA_DEF_ BO_  "NmAsrMessage" ENUM  "No","Yes";
BA_DEF_ BO_  "GenMsgTxConditionAccOn" ENUM  "No","Yes";
BA_DEF_ BO_  "GenMsgTxConditionIg1On" ENUM  "No","Yes";
BA_DEF_ BO_  "GenMsgTxConditionPlusBOn" ENUM  "No","Yes";
BA_DEF_ SG_  "GenSigInvalidValue" INT 0 10000000000;
BA_DEF_ BO_  "CANoeMsgTxTimingIgnitionSwitched" ENUM  "AccOn","IG1On","IG2On","NoMsgTxTiming";
BA_DEF_DEF_REL_ "SC_Verification" "Yes";
BA_DEF_DEF_  "SCP_FreshnessValueTxLength" 4;
BA_DEF_DEF_  "SCP_FreshnessValueLength" 48;
BA_DEF_DEF_  "SCP_DataId" 0;
BA_DEF_DEF_  "SCP_AuthInfoTxLength" 28;
BA_DEF_DEF_  "SC_Message" "No";
BA_DEF_DEF_  "CANFD_BRS" "1";
BA_DEF_DEF_  "VFrameFormat" "ExtendedCAN_FD";
BA_DEF_DEF_  "DiagRequest" "No";
BA_DEF_DEF_  "DiagResponse" "No";
BA_DEF_DEF_  "DiagState" "No";
BA_DEF_DEF_  "DiagConnection" 0;
BA_DEF_DEF_  "GenMsgCycleTime" 0;
BA_DEF_DEF_  "GenMsgCycleTimeFast" 0;
BA_DEF_DEF_  "GenMsgDelayTime" 20;
BA_DEF_DEF_  "GenMsgILSupport" "Yes";
BA_DEF_DEF_  "GenMsgNrOfRepetition" 0;
BA_DEF_DEF_  "GenMsgSendType" "NoMsgSendType";
BA_DEF_DEF_  "GenSigSendType" "NoSigSendType";
BA_DEF_DEF_  "GenSigStartValue" 0;
BA_DEF_DEF_  "GenSigTimeoutTime_CGW" 5000;
BA_DEF_DEF_  "GenSigTimeoutTime_ADU" 5000;
BA_DEF_DEF_  "NetworkInitialization" "No";
BA_DEF_DEF_  "GenSigEnvVarType" "undef";
BA_DEF_DEF_  "NWM-WakeupAllowed" "No";
BA_DEF_DEF_  "NmAsrMessage" "No";
BA_DEF_DEF_  "GenMsgTxConditionAccOn" "No";
BA_DEF_DEF_  "GenMsgTxConditionIg1On" "No";
BA_DEF_DEF_  "GenMsgTxConditionPlusBOn" "No";
BA_DEF_DEF_  "GenSigInvalidValue" 0;
BA_DEF_DEF_  "CANoeMsgTxTimingIgnitionSwitched" "NoMsgTxTiming";
BA_ "GenMsgSendType" BO_ 1103 5;
BA_ "GenMsgCycleTime" BO_ 1103 100;
BA_ "VFrameFormat" BO_ 1103 14;
BA_ "GenMsgSendType" BO_ 1100 5;
BA_ "GenMsgCycleTime" BO_ 1100 100;
BA_ "VFrameFormat" BO_ 1100 14;
BA_ "GenMsgSendType" BO_ 1090 5;
BA_ "GenMsgCycleTime" BO_ 1090 500;
BA_ "GenMsgCycleTimeFast" BO_ 1090 50;
BA_ "GenMsgNrOfRepetition" BO_ 1090 5;
BA_ "VFrameFormat" BO_ 1090 14;
BA_ "GenMsgSendType" BO_ 1089 0;
BA_ "GenMsgCycleTime" BO_ 1089 100;
BA_ "VFrameFormat" BO_ 1089 14;
BA_ "GenMsgSendType" BO_ 1088 5;
BA_ "GenMsgCycleTime" BO_ 1088 500;
BA_ "GenMsgCycleTimeFast" BO_ 1088 50;
BA_ "GenMsgNrOfRepetition" BO_ 1088 5;
BA_ "VFrameFormat" BO_ 1088 14;
BA_ "GenMsgSendType" BO_ 1087 5;
BA_ "GenMsgCycleTime" BO_ 1087 50;
BA_ "VFrameFormat" BO_ 1087 14;
BA_ "GenMsgSendType" BO_ 1086 5;
BA_ "GenMsgCycleTime" BO_ 1086 500;
BA_ "GenMsgCycleTimeFast" BO_ 1086 50;
BA_ "GenMsgNrOfRepetition" BO_ 1086 5;
BA_ "VFrameFormat" BO_ 1086 14;
BA_ "GenMsgSendType" BO_ 1084 5;
BA_ "GenMsgCycleTime" BO_ 1084 200;
BA_ "GenMsgCycleTimeFast" BO_ 1084 50;
BA_ "GenMsgNrOfRepetition" BO_ 1084 3;
BA_ "VFrameFormat" BO_ 1084 14;
BA_ "GenMsgSendType" BO_ 1078 5;
BA_ "GenMsgCycleTime" BO_ 1078 50;
BA_ "VFrameFormat" BO_ 1078 14;
BA_ "GenMsgSendType" BO_ 1066 5;
BA_ "SC_Message" BO_ 1066 1;
BA_ "SCP_DataId" BO_ 1066 1066;
BA_ "GenMsgCycleTime" BO_ 1066 50;
BA_ "VFrameFormat" BO_ 1066 14;
BA_ "GenMsgSendType" BO_ 1064 5;
BA_ "GenMsgCycleTime" BO_ 1064 1000;
BA_ "VFrameFormat" BO_ 1064 14;
BA_ "GenMsgSendType" BO_ 1063 5;
BA_ "GenMsgCycleTime" BO_ 1063 1000;
BA_ "VFrameFormat" BO_ 1063 14;
BA_ "GenMsgSendType" BO_ 1052 5;
BA_ "GenMsgCycleTime" BO_ 1052 1000;
BA_ "VFrameFormat" BO_ 1052 14;
BA_ "GenMsgSendType" BO_ 1051 5;
BA_ "GenMsgCycleTime" BO_ 1051 300;
BA_ "VFrameFormat" BO_ 1051 14;
BA_ "GenMsgSendType" BO_ 1050 5;
BA_ "GenMsgCycleTime" BO_ 1050 300;
BA_ "VFrameFormat" BO_ 1050 14;
BA_ "GenMsgSendType" BO_ 1049 5;
BA_ "GenMsgCycleTime" BO_ 1049 1000;
BA_ "VFrameFormat" BO_ 1049 14;
BA_ "GenMsgSendType" BO_ 1048 5;
BA_ "GenMsgCycleTime" BO_ 1048 200;
BA_ "VFrameFormat" BO_ 1048 14;
BA_ "GenMsgSendType" BO_ 1047 5;
BA_ "GenMsgCycleTime" BO_ 1047 100;
BA_ "VFrameFormat" BO_ 1047 14;
BA_ "GenMsgSendType" BO_ 1046 5;
BA_ "GenMsgCycleTime" BO_ 1046 1000;
BA_ "VFrameFormat" BO_ 1046 14;
BA_ "GenMsgSendType" BO_ 1045 5;
BA_ "GenMsgCycleTime" BO_ 1045 1000;
BA_ "NetworkInitialization" BO_ 1045 1;
BA_ "VFrameFormat" BO_ 1045 14;
BA_ "GenMsgSendType" BO_ 1044 0;
BA_ "GenMsgCycleTime" BO_ 1044 500;
BA_ "NetworkInitialization" BO_ 1044 1;
BA_ "VFrameFormat" BO_ 1044 14;
BA_ "GenMsgSendType" BO_ 1036 0;
BA_ "GenMsgCycleTime" BO_ 1036 50;
BA_ "VFrameFormat" BO_ 1036 14;
BA_ "GenMsgSendType" BO_ 1034 0;
BA_ "GenMsgCycleTime" BO_ 1034 50;
BA_ "VFrameFormat" BO_ 1034 14;
BA_ "GenMsgSendType" BO_ 1033 0;
BA_ "GenMsgCycleTime" BO_ 1033 100;
BA_ "NetworkInitialization" BO_ 1033 1;
BA_ "VFrameFormat" BO_ 1033 14;
BA_ "GenMsgSendType" BO_ 1032 5;
BA_ "GenMsgCycleTime" BO_ 1032 500;
BA_ "NetworkInitialization" BO_ 1032 1;
BA_ "VFrameFormat" BO_ 1032 14;
BA_ "GenMsgTxConditionIg1On" BO_ 1100 1;
BA_ "GenMsgTxConditionIg1On" BO_ 1052 1;
BA_ "GenMsgTxConditionIg1On" BO_ 1045 1;
BA_ "GenMsgTxConditionIg1On" BO_ 1044 1;
BA_ "GenMsgTxConditionIg1On" BO_ 1033 1;
BA_ "GenMsgTxConditionIg1On" BO_ 1032 1;
BA_ "GenMsgTxConditionAccOn" BO_ 1046 1;
BA_ "GenMsgTxConditionPlusBOn" BO_ 1103 1;
BA_ "GenMsgTxConditionPlusBOn" BO_ 1090 1;
BA_ "GenMsgTxConditionPlusBOn" BO_ 1089 1;
BA_ "GenMsgTxConditionPlusBOn" BO_ 1088 1;
BA_ "GenMsgTxConditionPlusBOn" BO_ 1087 1;
BA_ "GenMsgTxConditionPlusBOn" BO_ 1086 1;
BA_ "GenMsgTxConditionPlusBOn" BO_ 1084 1;
BA_ "GenMsgTxConditionPlusBOn" BO_ 1078 1;
BA_ "GenMsgTxConditionPlusBOn" BO_ 1066 1;
BA_ "GenMsgTxConditionPlusBOn" BO_ 1064 1;
BA_ "GenMsgTxConditionPlusBOn" BO_ 1063 1;
BA_ "GenMsgTxConditionPlusBOn" BO_ 1051 1;
BA_ "GenMsgTxConditionPlusBOn" BO_ 1050 1;
BA_ "GenMsgTxConditionPlusBOn" BO_ 1049 1;
BA_ "GenMsgTxConditionPlusBOn" BO_ 1048 1;
BA_ "GenMsgTxConditionPlusBOn" BO_ 1047 1;
BA_ "GenMsgTxConditionPlusBOn" BO_ 1036 1;
BA_ "GenMsgTxConditionPlusBOn" BO_ 1034 1;
BA_ "GenSigSendType" SG_ 1103 PDA_disp_forward_vehicle 3;
BA_ "GenSigSendType" SG_ 1103 PDA_disp_traffic 3;
BA_ "GenSigSendType" SG_ 1103 PDA_disp_curve 3;
BA_ "GenSigSendType" SG_ 1103 PDA_state 3;
BA_ "GenSigSendType" SG_ 1103 ISA_fallback 3;
BA_ "GenSigSendType" SG_ 1103 ISA_overspeed 3;
BA_ "GenSigSendType" SG_ 1103 ISA_state 3;
BA_ "GenSigSendType" SG_ 1103 ISA_EV_kickdown 3;
BA_ "GenSigSendType" SG_ 1103 ISA_sign 3;
BA_ "GenSigSendType" SG_ 1103 ASC_state 3;
BA_ "GenSigSendType" SG_ 1103 ACC_EV_override 3;
BA_ "GenSigSendType" SG_ 1103 ACC_EV_offer_sign 3;
BA_ "GenSigSendType" SG_ 1103 ACC_EV_mode_change_reject 3;
BA_ "GenSigSendType" SG_ 1103 ACC_EV_mode_change_accept 3;
BA_ "GenSigSendType" SG_ 1103 ACC_EV_set_dist 3;
BA_ "GenSigSendType" SG_ 1103 ACC_set_distance 3;
BA_ "GenSigSendType" SG_ 1103 ACC_set_velocity 3;
BA_ "GenSigSendType" SG_ 1103 ACC_sign 3;
BA_ "GenSigSendType" SG_ 1103 ACC_stop 3;
BA_ "GenSigSendType" SG_ 1103 ACC_target_decel 3;
BA_ "GenSigSendType" SG_ 1103 ACC_state 3;
BA_ "GenSigSendType" SG_ 1103 ACC_target 3;
BA_ "GenSigSendType" SG_ 1103 AD_state 3;
BA_ "GenSigSendType" SG_ 1103 OCP_opp_lh 3;
BA_ "GenSigSendType" SG_ 1103 OCP_opp_rh 3;
BA_ "GenSigSendType" SG_ 1103 OCP_lane_lh 3;
BA_ "GenSigSendType" SG_ 1103 OCP_lane_rh 3;
BA_ "GenSigSendType" SG_ 1103 OCP_state 3;
BA_ "GenSigSendType" SG_ 1103 CBDA_target_lh 3;
BA_ "GenSigSendType" SG_ 1103 CBDA_target_rh 3;
BA_ "GenSigSendType" SG_ 1103 CBDA_state 3;
BA_ "GenSigSendType" SG_ 1103 BSM_target_lh 3;
BA_ "GenSigSendType" SG_ 1103 BSM_target_rh 3;
BA_ "GenSigSendType" SG_ 1103 BSM_state 3;
BA_ "GenSigSendType" SG_ 1103 FCTA_target_lh 3;
BA_ "GenSigSendType" SG_ 1103 FCTA_target_rh 3;
BA_ "GenSigSendType" SG_ 1103 FCTA_state 3;
BA_ "GenSigSendType" SG_ 1103 BSP_target_lh 3;
BA_ "GenSigSendType" SG_ 1103 BSP_target_rh 3;
BA_ "GenSigSendType" SG_ 1103 BSP_lane_lh 3;
BA_ "GenSigSendType" SG_ 1103 BSP_lane_rh 3;
BA_ "GenSigSendType" SG_ 1103 BSP_state 3;
BA_ "GenSigSendType" SG_ 1103 RDP_roadedge_lh 3;
BA_ "GenSigSendType" SG_ 1103 RDP_roadedge_rh 3;
BA_ "GenSigSendType" SG_ 1103 RDP_state 3;
BA_ "GenSigSendType" SG_ 1103 LDW_lane_lh 3;
BA_ "GenSigSendType" SG_ 1103 LDW_lane_rh 3;
BA_ "GenSigSendType" SG_ 1103 LDW_state 3;
BA_ "GenSigSendType" SG_ 1103 LDP_lane_lh 3;
BA_ "GenSigSendType" SG_ 1103 LDP_lane_rh 3;
BA_ "GenSigSendType" SG_ 1103 LDP_state 3;
BA_ "GenSigSendType" SG_ 1103 AES_state 3;
BA_ "GenSigSendType" SG_ 1103 RCTB_state 3;
BA_ "GenSigSendType" SG_ 1103 RCTA_target_lh 3;
BA_ "GenSigSendType" SG_ 1103 RCTA_target_rh 3;
BA_ "GenSigSendType" SG_ 1103 RCTA_state 3;
BA_ "GenSigSendType" SG_ 1103 RPTC_state 3;
BA_ "GenSigSendType" SG_ 1103 PAEB_state 3;
BA_ "GenSigSendType" SG_ 1103 CTB_target_lh 3;
BA_ "GenSigSendType" SG_ 1103 CTB_target_rh 3;
BA_ "GenSigSendType" SG_ 1103 CTB_state 3;
BA_ "GenSigSendType" SG_ 1103 PTC_state 3;
BA_ "GenSigSendType" SG_ 1103 SBS_IND_state 3;
BA_ "GenSigSendType" SG_ 1103 AEB_state 3;
BA_ "GenSigSendType" SG_ 1100 LMkrRCrv_FSC2_01 3;
BA_ "GenSigStartValue" SG_ 1100 LMkrRCrv_FSC2_01 1001;
BA_ "GenSigInvalidValue" SG_ 1100 LMkrRCrv_FSC2_01 1002;
BA_ "GenSigSendType" SG_ 1100 LMkrLCrv_FSC2_01 3;
BA_ "GenSigStartValue" SG_ 1100 LMkrLCrv_FSC2_01 1001;
BA_ "GenSigInvalidValue" SG_ 1100 LMkrLCrv_FSC2_01 1002;
BA_ "GenSigSendType" SG_ 1100 LMkrRYaw_FSC1_01 3;
BA_ "GenSigStartValue" SG_ 1100 LMkrRYaw_FSC1_01 241;
BA_ "GenSigInvalidValue" SG_ 1100 LMkrRYaw_FSC1_01 242;
BA_ "GenSigSendType" SG_ 1100 LMkrLYaw_FSC1_01 3;
BA_ "GenSigStartValue" SG_ 1100 LMkrLYaw_FSC1_01 241;
BA_ "GenSigInvalidValue" SG_ 1100 LMkrLYaw_FSC1_01 242;
BA_ "GenSigSendType" SG_ 1100 LMkrRY0_FSC1_01 3;
BA_ "GenSigStartValue" SG_ 1100 LMkrRY0_FSC1_01 1001;
BA_ "GenSigInvalidValue" SG_ 1100 LMkrRY0_FSC1_01 1002;
BA_ "GenSigSendType" SG_ 1100 LMkrLY0_FSC1_01 3;
BA_ "GenSigStartValue" SG_ 1100 LMkrLY0_FSC1_01 1001;
BA_ "GenSigInvalidValue" SG_ 1100 LMkrLY0_FSC1_01 1002;
BA_ "GenSigSendType" SG_ 1100 LMkrRReli_FSC1_01 3;
BA_ "GenSigInvalidValue" SG_ 1100 LMkrRReli_FSC1_01 7;
BA_ "GenSigSendType" SG_ 1100 LMkrLReli_FSC1_01 3;
BA_ "GenSigInvalidValue" SG_ 1100 LMkrLReli_FSC1_01 7;
BA_ "GenSigInvalidValue" SG_ 1090 BackupBatteryOut_Psg_U_Actl 1023;
BA_ "GenSigSendType" SG_ 1090 MirrorLED2_status 4;
BA_ "GenSigTimeoutTime_ADU" SG_ 1090 MirrorLED2_status 1500;
BA_ "GenSigSendType" SG_ 1090 DrLock_Message_P_Rsp 4;
BA_ "GenSigSendType" SG_ 1090 PsgDLMotorDriveStat 4;
BA_ "GenSigSendType" SG_ 1090 Ctrl_DLSw_Psg_Stat 4;
BA_ "GenSigSendType" SG_ 1090 DrivingPositionStatus 4;
BA_ "GenSigSendType" SG_ 1090 LockLinkSwPsngr_D_Actl 4;
BA_ "GenSigStartValue" SG_ 1090 LockLinkSwPsngr_D_Actl 1;
BA_ "GenSigInvalidValue" SG_ 1090 LockLinkSwPsngr_D_Actl 1;
BA_ "GenSigSendType" SG_ 1090 DrStatPsngr_D_Qf 4;
BA_ "GenSigStartValue" SG_ 1090 DrStatPsngr_D_Qf 1;
BA_ "GenSigTimeoutTime_ADU" SG_ 1090 DrStatPsngr_D_Qf 1500;
BA_ "GenSigSendType" SG_ 1090 DrStatPsngr_B_Actl 4;
BA_ "GenSigTimeoutTime_ADU" SG_ 1090 DrStatPsngr_B_Actl 1500;
BA_ "GenSigInvalidValue" SG_ 1089 AvlFuelG_BCM 1023;
BA_ "GenSigInvalidValue" SG_ 1089 AvlFuelE_BCM 4095;
BA_ "GenSigInvalidValue" SG_ 1089 AvlPwrG_BCM 1023;
BA_ "GenSigInvalidValue" SG_ 1089 AvPwrE_BCM 4095;
BA_ "GenSigSendType" SG_ 1088 Move_AutoDposMirror_Res 4;
BA_ "GenSigInvalidValue" SG_ 1088 BackupBatteryOut_Drv_U_Act 1023;
BA_ "GenSigSendType" SG_ 1088 MirrorLED1_status 4;
BA_ "GenSigTimeoutTime_ADU" SG_ 1088 MirrorLED1_status 1500;
BA_ "GenSigSendType" SG_ 1088 DrLock_Message_D_Rsp 4;
BA_ "GenSigSendType" SG_ 1088 DrivingPositionRequest 4;
BA_ "GenSigSendType" SG_ 1088 Mirror_AjustSelSW_Status 4;
BA_ "GenSigSendType" SG_ 1088 MirrorFoldRequest 4;
BA_ "GenSigSendType" SG_ 1088 MirrorAdjustRequest 4;
BA_ "GenSigSendType" SG_ 1088 MirrorAdjst_Manual_Status 4;
BA_ "GenSigSendType" SG_ 1088 MirrorAdjst_Status 4;
BA_ "GenSigSendType" SG_ 1088 Erase_MirrorMem_Res 4;
BA_ "GenSigSendType" SG_ 1088 Recall_MirrorMem_Res 4;
BA_ "GenSigSendType" SG_ 1088 Record_MirrorMem_Res 4;
BA_ "GenSigSendType" SG_ 1088 PW_Move_R 4;
BA_ "GenSigSendType" SG_ 1088 PW_Move_P 4;
BA_ "GenSigSendType" SG_ 1088 PWcut_D_Actl 4;
BA_ "GenSigSendType" SG_ 1088 DrvDLMotorDriveStat 4;
BA_ "GenSigSendType" SG_ 1088 Ctrl_DLSw_Drv_Stat 4;
BA_ "GenSigSendType" SG_ 1088 LockLinkSwDrv_D_Actl 4;
BA_ "GenSigSendType" SG_ 1088 DrStatDrv_D_Qf 4;
BA_ "GenSigStartValue" SG_ 1088 DrStatDrv_D_Qf 1;
BA_ "GenSigTimeoutTime_ADU" SG_ 1088 DrStatDrv_D_Qf 1500;
BA_ "GenSigSendType" SG_ 1088 DrStatDrv_B_Actl 4;
BA_ "GenSigTimeoutTime_ADU" SG_ 1088 DrStatDrv_B_Actl 1500;
BA_ "GenSigSendType" SG_ 1087 RearWipr_Pos_Actl 3;
BA_ "GenSigSendType" SG_ 1087 Rearfog_D_Act 3;
BA_ "GenSigSendType" SG_ 1087 Reverse_D_Act 3;
BA_ "GenSigSendType" SG_ 1087 Stoplamp_D_Act 3;
BA_ "GenSigSendType" SG_ 1087 Taillamp2_D_Act 3;
BA_ "GenSigSendType" SG_ 1087 Taillamp1_D_Act 3;
BA_ "GenSigSendType" SG_ 1087 RearTurnL_D_Act 3;
BA_ "GenSigSendType" SG_ 1087 RearTurnR_D_Act 3;
BA_ "GenSigSendType" SG_ 1087 RearWipr_Stall_Status 3;
BA_ "GenSigSendType" SG_ 1087 RearWipr_Ctrl_Status 3;
BA_ "GenSigTimeoutTime_ADU" SG_ 1087 Trailer_Towing_B_Actl 150;
BA_ "GenSigTimeoutTime_ADU" SG_ 1087 Trailer_Hitch_B_Actl 150;
BA_ "GenSigStartValue" SG_ 1087 FuelLvlVref_No_Raw 1023;
BA_ "GenSigStartValue" SG_ 1087 FuelLvlDssvSide_No_Raw 1023;
BA_ "GenSigStartValue" SG_ 1087 FuelLvlActvSide_No_Raw 1023;
BA_ "GenSigStartValue" SG_ 1086 Charge_SOCdistance 127;
BA_ "GenSigInvalidValue" SG_ 1086 Charge_SOCdistance 127;
BA_ "GenSigStartValue" SG_ 1086 Charge_Available_Distance_Upper 511;
BA_ "GenSigInvalidValue" SG_ 1086 Charge_Available_Distance_Upper 511;
BA_ "GenSigStartValue" SG_ 1086 OilDtr_InitTime 63;
BA_ "GenSigInvalidValue" SG_ 1086 OilDtr_InitTime 63;
BA_ "GenSigStartValue" SG_ 1086 OilDtr_InitDistK 63;
BA_ "GenSigInvalidValue" SG_ 1086 OilDtr_InitDistK 63;
BA_ "GenSigTimeoutTime_ADU" SG_ 1086 UP_Light_SENSOR_Meas 1500;
BA_ "GenSigStartValue" SG_ 1086 UP_Light_SENSOR_Qf 1;
BA_ "GenSigTimeoutTime_ADU" SG_ 1086 UP_Light_SENSOR_Qf 1500;
BA_ "GenSigSendType" SG_ 1086 OilDtrWrnB_D_Rq 4;
BA_ "GenSigSendType" SG_ 1086 DrStatHood_B_Actl 4;
BA_ "GenSigSendType" SG_ 1086 Burglar_Status 4;
BA_ "GenSigInvalidValue" SG_ 1084 RemDrvDistPer_D_Actl 255;
BA_ "GenSigSendType" SG_ 1084 Fuel_Lid_Motor_Lock_Request 4;
BA_ "GenSigStartValue" SG_ 1084 FWD_Light_SENSOR_Qf 1;
BA_ "GenSigSendType" SG_ 1084 DrStatRr_B_Actl 4;
BA_ "GenSigTimeoutTime_ADU" SG_ 1084 DrStatRr_B_Actl 600;
BA_ "GenSigSendType" SG_ 1084 DrStatC_D_Qf 4;
BA_ "GenSigStartValue" SG_ 1084 DrStatC_D_Qf 1;
BA_ "GenSigTimeoutTime_ADU" SG_ 1084 DrStatC_D_Qf 600;
BA_ "GenSigSendType" SG_ 1084 SecurityStatus 4;
BA_ "GenSigSendType" SG_ 1084 GlobalOpenClose_Request 4;
BA_ "GenSigSendType" SG_ 1084 TrnkLg_Motor_Request 4;
BA_ "GenSigSendType" SG_ 1084 DrLockUnlock_Ctl_Rq 4;
BA_ "GenSigSendType" SG_ 1084 DrLock_Message 4;
BA_ "GenSigSendType" SG_ 1078 SteerHeatIndic_D_Req 3;
BA_ "GenSigSendType" SG_ 1078 SeatVentIndicRr_D_Req 3;
BA_ "GenSigSendType" SG_ 1078 SeatVentIndicRl_D_Req 3;
BA_ "GenSigSendType" SG_ 1078 SeatHeatIndicRr_D_Req 3;
BA_ "GenSigSendType" SG_ 1078 SteerHeat_Elm_Enable 3;
BA_ "GenSigSendType" SG_ 1078 SeatHeat_Elm_Enable 3;
BA_ "GenSigSendType" SG_ 1078 Charge_Mode_Enabled_SW 3;
BA_ "GenSigSendType" SG_ 1078 Drive_Mode_Enabled_Switch 3;
BA_ "GenSigSendType" SG_ 1078 atcControlStatus 3;
BA_ "GenSigSendType" SG_ 1078 SeatVentIndicFr_D_Req 3;
BA_ "GenSigSendType" SG_ 1078 SeatVentIndicFl_D_Req 3;
BA_ "GenSigSendType" SG_ 1078 SeatHeatIndicFr_D_Req 3;
BA_ "GenSigSendType" SG_ 1078 SeatHeatIndicFl_D_Req 3;
BA_ "GenSigSendType" SG_ 1078 atcACmodeDisp 3;
BA_ "GenSigSendType" SG_ 1078 atcAImodeDisp 3;
BA_ "GenSigSendType" SG_ 1078 atcADmodeDisp 3;
BA_ "GenSigSendType" SG_ 1078 atcBlwLvlDisp 3;
BA_ "GenSigSendType" SG_ 1078 HvacEngStopCtrl_D_Actl 3;
BA_ "GenSigSendType" SG_ 1078 SeatHeatIndicRl_D_Req 3;
BA_ "GenSigSendType" SG_ 1078 BlowerSpeed 3;
BA_ "GenSigSendType" SG_ 1078 HvacEngStopInputFail_D_Rq 3;
BA_ "GenSigSendType" SG_ 1078 HvacAirCond_B_Rq 3;
BA_ "GenSigSendType" SG_ 1078 HvacEngStopDis_B_Rq_exceptTEva 3;
BA_ "GenSigSendType" SG_ 1078 HvacEngStopDis_B_Rq 3;
BA_REL_ "SC_Verification" BU_SG_REL_ ADU SG_ 1066 Hvac_Control_Information2_MACTx 0;
BA_ "GenSigTimeoutTime_ADU" SG_ 1066 Hvac_Control_Information2_MACTx 150;
BA_REL_ "SC_Verification" BU_SG_REL_ ADU SG_ 1066 Hvac_Control_Information2_FVTx 0;
BA_ "GenSigTimeoutTime_ADU" SG_ 1066 Hvac_Control_Information2_FVTx 150;
BA_ "GenSigSendType" SG_ 1066 View_RPC_APS_Sw_D_Qf 3;
BA_ "GenSigStartValue" SG_ 1066 View_RPC_APS_Sw_D_Qf 2;
BA_ "GenSigTimeoutTime_ADU" SG_ 1066 View_RPC_APS_Sw_D_Qf 150;
BA_ "GenSigSendType" SG_ 1066 View_RPC_APS_Sw_B_Actl 3;
BA_ "GenSigTimeoutTime_ADU" SG_ 1066 View_RPC_APS_Sw_B_Actl 150;
BA_ "GenSigSendType" SG_ 1066 HdcSw_D_Actl 3;
BA_ "GenSigTimeoutTime_ADU" SG_ 1066 HdcSw_D_Actl 150;
BA_ "GenSigSendType" SG_ 1066 FirstRowBuckleDriver 3;
BA_ "GenSigStartValue" SG_ 1066 FirstRowBuckleDriver 1;
BA_ "GenSigTimeoutTime_ADU" SG_ 1066 FirstRowBuckleDriver 150;
BA_ "GenSigSendType" SG_ 1066 ID42A_E2E_CNTProfile2 3;
BA_ "GenSigTimeoutTime_ADU" SG_ 1066 ID42A_E2E_CNTProfile2 150;
BA_ "GenSigSendType" SG_ 1066 ID42A_E2E_CRCProfile2 3;
BA_ "GenSigTimeoutTime_ADU" SG_ 1066 ID42A_E2E_CRCProfile2 150;
BA_ "GenSigSendType" SG_ 1064 Outlet_L2_D_Act 3;
BA_ "GenSigSendType" SG_ 1064 Outlet_L1_D_Act 3;
BA_ "GenSigSendType" SG_ 1064 FSM_L_D_Act 3;
BA_ "GenSigSendType" SG_ 1064 LCM_L_Err_Status_Info 3;
BA_ "GenSigSendType" SG_ 1064 FrontTurn_L_D_Act 3;
BA_ "GenSigTimeoutTime_ADU" SG_ 1064 FrontTurn_L_D_Act 3000;
BA_ "GenSigSendType" SG_ 1064 Headlight_L_DRL_D_Act 3;
BA_ "GenSigSendType" SG_ 1064 Headlight_L_Pos_D_Act 3;
BA_ "GenSigSendType" SG_ 1064 Headlight_L_Lo_D_Act 3;
BA_ "GenSigTimeoutTime_ADU" SG_ 1064 Headlight_L_Lo_D_Act 3000;
BA_ "GenSigSendType" SG_ 1064 Headlight_L_Hi_D_Act 3;
BA_ "GenSigTimeoutTime_ADU" SG_ 1064 Headlight_L_Hi_D_Act 3000;
BA_ "GenSigSendType" SG_ 1063 Outlet_R2_D_Act 3;
BA_ "GenSigSendType" SG_ 1063 Outlet_R1_D_Act 3;
BA_ "GenSigSendType" SG_ 1063 FSM_R_D_Act 3;
BA_ "GenSigSendType" SG_ 1063 LCM_R_Err_Status_Info 3;
BA_ "GenSigSendType" SG_ 1063 FrontTurn_R_D_Act 3;
BA_ "GenSigTimeoutTime_ADU" SG_ 1063 FrontTurn_R_D_Act 3000;
BA_ "GenSigSendType" SG_ 1063 Headlight_R_DRL_D_Act 3;
BA_ "GenSigSendType" SG_ 1063 Headlight_R_Pos_D_Act 3;
BA_ "GenSigSendType" SG_ 1063 Headlight_R_Lo_D_Act 3;
BA_ "GenSigTimeoutTime_ADU" SG_ 1063 Headlight_R_Lo_D_Act 3000;
BA_ "GenSigSendType" SG_ 1063 Headlight_R_Hi_D_Act 3;
BA_ "GenSigTimeoutTime_ADU" SG_ 1063 Headlight_R_Hi_D_Act 3000;
BA_ "GenSigSendType" SG_ 1052 GRDTIME 3;
BA_ "GenSigSendType" SG_ 1052 GRDDIST 3;
BA_ "GenSigSendType" SG_ 1052 FORMID_D 3;
BA_ "GenSigSendType" SG_ 1052 MDCREQID 3;
BA_ "GenSigStartValue" SG_ 1052 MDCREQID 255;
BA_ "GenSigSendType" SG_ 1052 PADDING1 3;
BA_ "GenSigSendType" SG_ 1052 FORMID_C 3;
BA_ "GenSigStartValue" SG_ 1052 FORMID_C 255;
BA_ "GenSigSendType" SG_ 1052 MAXTRG 3;
BA_ "GenSigSendType" SG_ 1052 LOGIOPE 3;
BA_ "GenSigSendType" SG_ 1052 FORMID_B 3;
BA_ "GenSigStartValue" SG_ 1052 FORMID_B 255;
BA_ "GenSigSendType" SG_ 1052 FORMID_A 3;
BA_ "GenSigStartValue" SG_ 1052 FORMID_A 255;
BA_ "GenSigSendType" SG_ 1052 COMPVAL 3;
BA_ "GenSigSendType" SG_ 1052 Y_CONST 3;
BA_ "GenSigSendType" SG_ 1052 COMPOPE 3;
BA_ "GenSigSendType" SG_ 1052 PREPROC 3;
BA_ "GenSigSendType" SG_ 1052 Y_DELAY 3;
BA_ "GenSigSendType" SG_ 1052 PADDINGY 3;
BA_ "GenSigSendType" SG_ 1052 Y_TYPE 3;
BA_ "GenSigSendType" SG_ 1052 Y_DATAID 3;
BA_ "GenSigSendType" SG_ 1052 X_DELAY 3;
BA_ "GenSigSendType" SG_ 1052 PADDINGX 3;
BA_ "GenSigSendType" SG_ 1052 X_TYPE 3;
BA_ "GenSigSendType" SG_ 1052 X_DATAID 3;
BA_ "GenSigSendType" SG_ 1052 FORMID 3;
BA_ "GenSigStartValue" SG_ 1052 FORMID 255;
BA_ "GenSigSendType" SG_ 1052 FRAMID0 3;
BA_ "GenSigStartValue" SG_ 1052 FRAMID0 255;
BA_ "GenSigSendType" SG_ 1052 TTLFRAM 3;
BA_ "GenSigSendType" SG_ 1051 AdbusMde_D_Actl 3;
BA_ "GenSigSendType" SG_ 1051 BA_PDC 3;
BA_ "GenSigSendType" SG_ 1051 BAOF_PDC 3;
BA_ "GenSigSendType" SG_ 1050 ID41A_No_Cs 3;
BA_ "GenSigSendType" SG_ 1050 GSNSOFF 3;
BA_ "GenSigSendType" SG_ 1050 EIGRCPFG 3;
BA_ "GenSigSendType" SG_ 1050 TNLS 3;
BA_ "GenSigSendType" SG_ 1050 G_DETECT 3;
BA_ "GenSigSendType" SG_ 1050 AdbusMde_D_Actl_BCM 3;
BA_ "GenSigSendType" SG_ 1050 ERROR 3;
BA_ "GenSigSendType" SG_ 1050 MO_IND 3;
BA_ "GenSigSendType" SG_ 1050 TB_CONN 3;
BA_ "GenSigSendType" SG_ 1050 PARK_S 3;
BA_ "GenSigSendType" SG_ 1050 BA_PDC_BCM 3;
BA_ "GenSigSendType" SG_ 1050 BAOF_PDC_BCM 3;
BA_ "GenSigSendType" SG_ 1050 ACC_PDC 3;
BA_ "GenSigSendType" SG_ 1050 IGR_PDC 3;
BA_ "GenSigSendType" SG_ 1050 IGP_PDC 3;
BA_ "GenSigSendType" SG_ 1050 TRNR_S 3;
BA_ "GenSigSendType" SG_ 1050 TRNL_S 3;
BA_ "GenSigSendType" SG_ 1050 CRGR_S 3;
BA_ "GenSigSendType" SG_ 1050 CRGL_S 3;
BA_ "GenSigSendType" SG_ 1049 ALLOF_ST 3;
BA_ "GenSigSendType" SG_ 1049 TNS 3;
BA_ "GenSigSendType" SG_ 1049 PAS_ST 3;
BA_ "GenSigSendType" SG_ 1049 CLL_R 3;
BA_ "GenSigSendType" SG_ 1049 TNLS_ST 3;
BA_ "GenSigSendType" SG_ 1049 SB_OK 3;
BA_ "GenSigSendType" SG_ 1049 FRWASH 3;
BA_ "GenSigSendType" SG_ 1049 FRWIPOPE 3;
BA_ "GenSigSendType" SG_ 1049 FR_EXE 3;
BA_ "GenSigSendType" SG_ 1049 FR_FID 3;
BA_ "GenSigSendType" SG_ 1049 FR_PIDST 3;
BA_ "GenSigSendType" SG_ 1049 PSER 3;
BA_ "GenSigSendType" SG_ 1049 PSEU 3;
BA_ "GenSigSendType" SG_ 1049 PSUN_D 3;
BA_ "GenSigStartValue" SG_ 1049 PSUN_D 7;
BA_ "GenSigSendType" SG_ 1048 MRMV_R 3;
BA_ "GenSigTimeoutTime_ADU" SG_ 1047 BrakeSysFeatures_No_Cs 300;
BA_ "GenSigTimeoutTime_ADU" SG_ 1047 BrakeSysFeatures_No_Cnt 300;
BA_ "GenSigSendType" SG_ 1047 EPB_TrqRequire 3;
BA_ "GenSigSendType" SG_ 1047 EPB_IGoff_Apply_Inhibit 3;
BA_ "GenSigSendType" SG_ 1047 RGN_StpLmp_Fail_Flag 3;
BA_ "GenSigSendType" SG_ 1047 BrkSupWhlTq_B_Falt 3;
BA_ "GenSigSendType" SG_ 1047 BrkFluidLvl_D_Actl 3;
BA_ "GenSigStartValue" SG_ 1047 BrkFluidLvl_D_Actl 3;
BA_ "GenSigSendType" SG_ 1047 DSC_OnOff_status 3;
BA_ "GenSigTimeoutTime_ADU" SG_ 1047 DSC_OnOff_status 300;
BA_ "GenSigSendType" SG_ 1047 TCS_ENG_FAILD 3;
BA_ "GenSigSendType" SG_ 1047 TCS_BRK_FAILD 3;
BA_ "GenSigSendType" SG_ 1047 Dsc_B_Falt 3;
BA_ "GenSigTimeoutTime_ADU" SG_ 1047 Dsc_B_Falt 300;
BA_ "GenSigSendType" SG_ 1047 EPB_Status 3;
BA_ "GenSigSendType" SG_ 1047 EPB_SwitchPosition 3;
BA_ "GenSigSendType" SG_ 1047 EPB_EnableExternalApply_PT 3;
BA_ "GenSigSendType" SG_ 1047 EPB_EnableDecelRequest 3;
BA_ "GenSigSendType" SG_ 1047 EPB_EnableExternalApply_VCM 3;
BA_ "GenSigSendType" SG_ 1047 AutoHoldStdbyLamp_D_Rq 3;
BA_ "GenSigSendType" SG_ 1046 AVNINFST 3;
BA_ "GenSigSendType" SG_ 1046 SPTTGTRD 3;
BA_ "GenSigSendType" SG_ 1046 CONFMMC 3;
BA_ "GenSigSendType" SG_ 1046 A_CLR_S 3;
BA_ "GenSigStartValue" SG_ 1046 A_CLR_S 15;
BA_ "GenSigSendType" SG_ 1046 SENSFAIL 3;
BA_ "GenSigSendType" SG_ 1046 SENSPFM 3;
BA_ "GenSigSendType" SG_ 1046 TUNL 3;
BA_ "GenSigSendType" SG_ 1046 BRANCH 3;
BA_ "GenSigSendType" SG_ 1046 MWMP 3;
BA_ "GenSigSendType" SG_ 1046 DRVW 3;
BA_ "GenSigSendType" SG_ 1046 DM_PGSW 3;
BA_ "GenSigSendType" SG_ 1046 LYT 3;
BA_ "GenSigStartValue" SG_ 1046 LYT 15;
BA_ "GenSigSendType" SG_ 1046 CONFID11 3;
BA_ "GenSigSendType" SG_ 1046 CONFID01 3;
BA_ "GenSigSendType" SG_ 1046 RDC 3;
BA_ "GenSigStartValue" SG_ 1046 RDC 15;
BA_ "GenSigSendType" SG_ 1045 DTSSLTID 3;
BA_ "GenSigSendType" SG_ 1045 DEPSAEST 3;
BA_ "GenSigSendType" SG_ 1045 DTSSSTR 3;
BA_ "GenSigSendType" SG_ 1045 ERMFLSV 3;
BA_ "GenSigSendType" SG_ 1045 ERMEESV 3;
BA_ "GenSigSendType" SG_ 1045 DSTVIB 3;
BA_ "GenSigSendType" SG_ 1045 GAERR3_H 3;
BA_ "GenSigSendType" SG_ 1045 GAEVAL_H 3;
BA_ "GenSigSendType" SG_ 1045 GAERR1_V 3;
BA_ "GenSigSendType" SG_ 1045 DRTCNT_G 3;
BA_ "GenSigSendType" SG_ 1045 GAE_V_R1 3;
BA_ "GenSigSendType" SG_ 1045 SDIRT_G 3;
BA_ "GenSigSendType" SG_ 1045 FRDHTR_G 3;
BA_ "GenSigSendType" SG_ 1045 GAE_H_R3 3;
BA_ "GenSigSendType" SG_ 1045 ERMCNTST 3;
BA_ "GenSigSendType" SG_ 1045 DM_PVMCS 3;
BA_ "GenSigSendType" SG_ 1045 DM_PVMVW 3;
BA_ "GenSigSendType" SG_ 1045 PV_AREA 3;
BA_ "GenSigSendType" SG_ 1045 V_IDARGL 3;
BA_ "GenSigSendType" SG_ 1045 V_IDANOA 3;
BA_ "GenSigSendType" SG_ 1045 EJLDACP 3;
BA_ "GenSigSendType" SG_ 1045 EJDEVPRD 3;
BA_ "GenSigSendType" SG_ 1045 V_IDACCL 3;
BA_ "GenSigSendType" SG_ 1045 SWSSTAT 3;
BA_ "GenSigSendType" SG_ 1045 LDARCGR 3;
BA_ "GenSigSendType" SG_ 1045 LDARCGL 3;
BA_ "GenSigSendType" SG_ 1045 FCMINTMP 3;
BA_ "GenSigSendType" SG_ 1045 LDARSN 3;
BA_ "GenSigSendType" SG_ 1045 LDASTATR 3;
BA_ "GenSigSendType" SG_ 1045 LDASTATL 3;
BA_ "GenSigStartValue" SG_ 1036 Central_CRC_40C 65535;
BA_ "GenSigInvalidValue" SG_ 1036 Central_CRC_40C 65535;
BA_ "GenSigStartValue" SG_ 1036 CDID_Total_Number_40C 255;
BA_ "GenSigInvalidValue" SG_ 1036 CDID_Total_Number_40C 255;
BA_ "GenSigStartValue" SG_ 1036 Reserved_E0_2_40C 65535;
BA_ "GenSigInvalidValue" SG_ 1036 Reserved_E0_2_40C 65535;
BA_ "GenSigStartValue" SG_ 1036 Reserved_E0_1_40C 65535;
BA_ "GenSigInvalidValue" SG_ 1036 Reserved_E0_1_40C 65535;
BA_ "GenSigStartValue" SG_ 1036 Reserved_95_7_40C 255;
BA_ "GenSigInvalidValue" SG_ 1036 Reserved_95_7_40C 255;
BA_ "GenSigStartValue" SG_ 1036 Reserved_95_6_40C 255;
BA_ "GenSigInvalidValue" SG_ 1036 Reserved_95_6_40C 255;
BA_ "GenSigStartValue" SG_ 1036 Reserved_95_5_40C 255;
BA_ "GenSigInvalidValue" SG_ 1036 Reserved_95_5_40C 255;
BA_ "GenSigStartValue" SG_ 1036 Reserved_95_4_40C 255;
BA_ "GenSigInvalidValue" SG_ 1036 Reserved_95_4_40C 255;
BA_ "GenSigStartValue" SG_ 1036 Reserved_95_3_40C 255;
BA_ "GenSigInvalidValue" SG_ 1036 Reserved_95_3_40C 255;
BA_ "GenSigStartValue" SG_ 1036 Reserved_95_2_40C 255;
BA_ "GenSigInvalidValue" SG_ 1036 Reserved_95_2_40C 255;
BA_ "GenSigStartValue" SG_ 1036 Reserved_95_1_40C 255;
BA_ "GenSigInvalidValue" SG_ 1036 Reserved_95_1_40C 255;
BA_ "GenSigStartValue" SG_ 1036 Reserved_94_7_40C 255;
BA_ "GenSigInvalidValue" SG_ 1036 Reserved_94_7_40C 255;
BA_ "GenSigStartValue" SG_ 1036 Reserved_94_6_40C 255;
BA_ "GenSigInvalidValue" SG_ 1036 Reserved_94_6_40C 255;
BA_ "GenSigStartValue" SG_ 1036 Reserved_94_5_40C 255;
BA_ "GenSigInvalidValue" SG_ 1036 Reserved_94_5_40C 255;
BA_ "GenSigStartValue" SG_ 1036 Reserved_94_4_40C 255;
BA_ "GenSigInvalidValue" SG_ 1036 Reserved_94_4_40C 255;
BA_ "GenSigStartValue" SG_ 1036 Reserved_94_3_40C 255;
BA_ "GenSigInvalidValue" SG_ 1036 Reserved_94_3_40C 255;
BA_ "GenSigStartValue" SG_ 1036 Reserved_94_2_40C 255;
BA_ "GenSigInvalidValue" SG_ 1036 Reserved_94_2_40C 255;
BA_ "GenSigStartValue" SG_ 1036 Reserved_94_1_40C 255;
BA_ "GenSigInvalidValue" SG_ 1036 Reserved_94_1_40C 255;
BA_ "GenSigStartValue" SG_ 1036 Reserved_93_7_40C 255;
BA_ "GenSigInvalidValue" SG_ 1036 Reserved_93_7_40C 255;
BA_ "GenSigStartValue" SG_ 1036 Reserved_93_6_40C 255;
BA_ "GenSigInvalidValue" SG_ 1036 Reserved_93_6_40C 255;
BA_ "GenSigStartValue" SG_ 1036 Reserved_93_5_40C 255;
BA_ "GenSigInvalidValue" SG_ 1036 Reserved_93_5_40C 255;
BA_ "GenSigStartValue" SG_ 1036 Reserved_93_4_40C 255;
BA_ "GenSigInvalidValue" SG_ 1036 Reserved_93_4_40C 255;
BA_ "GenSigStartValue" SG_ 1036 Reserved_93_3_40C 255;
BA_ "GenSigInvalidValue" SG_ 1036 Reserved_93_3_40C 255;
BA_ "GenSigStartValue" SG_ 1036 Reserved_93_2_40C 255;
BA_ "GenSigInvalidValue" SG_ 1036 Reserved_93_2_40C 255;
BA_ "GenSigStartValue" SG_ 1036 Reserved_93_1_40C 255;
BA_ "GenSigInvalidValue" SG_ 1036 Reserved_93_1_40C 255;
BA_ "GenSigStartValue" SG_ 1036 Reserved_92_7_40C 255;
BA_ "GenSigInvalidValue" SG_ 1036 Reserved_92_7_40C 255;
BA_ "GenSigStartValue" SG_ 1036 Reserved_92_6_40C 255;
BA_ "GenSigInvalidValue" SG_ 1036 Reserved_92_6_40C 255;
BA_ "GenSigStartValue" SG_ 1036 Reserved_92_5_40C 255;
BA_ "GenSigInvalidValue" SG_ 1036 Reserved_92_5_40C 255;
BA_ "GenSigStartValue" SG_ 1036 Reserved_92_4_40C 255;
BA_ "GenSigInvalidValue" SG_ 1036 Reserved_92_4_40C 255;
BA_ "GenSigStartValue" SG_ 1036 Reserved_92_3_40C 255;
BA_ "GenSigInvalidValue" SG_ 1036 Reserved_92_3_40C 255;
BA_ "GenSigStartValue" SG_ 1036 Reserved_92_2_40C 255;
BA_ "GenSigInvalidValue" SG_ 1036 Reserved_92_2_40C 255;
BA_ "GenSigStartValue" SG_ 1036 Reserved_92_1_40C 255;
BA_ "GenSigInvalidValue" SG_ 1036 Reserved_92_1_40C 255;
BA_ "GenSigStartValue" SG_ 1036 Reserved_91_7_40C 255;
BA_ "GenSigInvalidValue" SG_ 1036 Reserved_91_7_40C 255;
BA_ "GenSigStartValue" SG_ 1036 Reserved_91_6_40C 255;
BA_ "GenSigInvalidValue" SG_ 1036 Reserved_91_6_40C 255;
BA_ "GenSigStartValue" SG_ 1036 Reserved_91_5_40C 255;
BA_ "GenSigInvalidValue" SG_ 1036 Reserved_91_5_40C 255;
BA_ "GenSigStartValue" SG_ 1036 Reserved_91_4_40C 255;
BA_ "GenSigInvalidValue" SG_ 1036 Reserved_91_4_40C 255;
BA_ "GenSigStartValue" SG_ 1036 Reserved_91_3_40C 255;
BA_ "GenSigInvalidValue" SG_ 1036 Reserved_91_3_40C 255;
BA_ "GenSigStartValue" SG_ 1036 Reserved_91_2_40C 255;
BA_ "GenSigInvalidValue" SG_ 1036 Reserved_91_2_40C 255;
BA_ "GenSigStartValue" SG_ 1036 Reserved_91_1_40C 255;
BA_ "GenSigInvalidValue" SG_ 1036 Reserved_91_1_40C 255;
BA_ "GenSigStartValue" SG_ 1036 Reserved_90_7_40C 255;
BA_ "GenSigInvalidValue" SG_ 1036 Reserved_90_7_40C 255;
BA_ "GenSigStartValue" SG_ 1036 Reserved_90_6_40C 255;
BA_ "GenSigInvalidValue" SG_ 1036 Reserved_90_6_40C 255;
BA_ "GenSigStartValue" SG_ 1036 Reserved_90_5_40C 255;
BA_ "GenSigInvalidValue" SG_ 1036 Reserved_90_5_40C 255;
BA_ "GenSigStartValue" SG_ 1036 Reserved_90_4_40C 255;
BA_ "GenSigInvalidValue" SG_ 1036 Reserved_90_4_40C 255;
BA_ "GenSigStartValue" SG_ 1036 Reserved_90_3_40C 255;
BA_ "GenSigInvalidValue" SG_ 1036 Reserved_90_3_40C 255;
BA_ "GenSigStartValue" SG_ 1036 Reserved_90_2_40C 255;
BA_ "GenSigInvalidValue" SG_ 1036 Reserved_90_2_40C 255;
BA_ "GenSigStartValue" SG_ 1036 Reserved_90_1_40C 255;
BA_ "GenSigInvalidValue" SG_ 1036 Reserved_90_1_40C 255;
BA_ "GenSigStartValue" SG_ 1036 Reserved_82_7_40C 255;
BA_ "GenSigInvalidValue" SG_ 1036 Reserved_82_7_40C 255;
BA_ "GenSigStartValue" SG_ 1036 Reserved_82_6_40C 255;
BA_ "GenSigInvalidValue" SG_ 1036 Reserved_82_6_40C 255;
BA_ "GenSigStartValue" SG_ 1036 Reserved_82_5_40C 255;
BA_ "GenSigInvalidValue" SG_ 1036 Reserved_82_5_40C 255;
BA_ "GenSigStartValue" SG_ 1036 Reserved_82_4_40C 255;
BA_ "GenSigInvalidValue" SG_ 1036 Reserved_82_4_40C 255;
BA_ "GenSigStartValue" SG_ 1036 Reserved_82_3_40C 255;
BA_ "GenSigInvalidValue" SG_ 1036 Reserved_82_3_40C 255;
BA_ "GenSigStartValue" SG_ 1036 Reserved_82_2_40C 255;
BA_ "GenSigInvalidValue" SG_ 1036 Reserved_82_2_40C 255;
BA_ "GenSigStartValue" SG_ 1036 Reserved_82_1_40C 255;
BA_ "GenSigInvalidValue" SG_ 1036 Reserved_82_1_40C 255;
BA_ "GenSigStartValue" SG_ 1036 Reserved_80_7_40C 255;
BA_ "GenSigInvalidValue" SG_ 1036 Reserved_80_7_40C 255;
BA_ "GenSigStartValue" SG_ 1036 Reserved_80_6_40C 255;
BA_ "GenSigInvalidValue" SG_ 1036 Reserved_80_6_40C 255;
BA_ "GenSigStartValue" SG_ 1036 Reserved_80_5_40C 255;
BA_ "GenSigInvalidValue" SG_ 1036 Reserved_80_5_40C 255;
BA_ "GenSigStartValue" SG_ 1036 Reserved_80_4_40C 255;
BA_ "GenSigInvalidValue" SG_ 1036 Reserved_80_4_40C 255;
BA_ "GenSigStartValue" SG_ 1036 Reserved_80_3_40C 255;
BA_ "GenSigInvalidValue" SG_ 1036 Reserved_80_3_40C 255;
BA_ "GenSigStartValue" SG_ 1036 Reserved_80_2_40C 255;
BA_ "GenSigInvalidValue" SG_ 1036 Reserved_80_2_40C 255;
BA_ "GenSigStartValue" SG_ 1036 Reserved_80_1_40C 255;
BA_ "GenSigInvalidValue" SG_ 1036 Reserved_80_1_40C 255;
BA_ "GenSigStartValue" SG_ 1036 Reserved_72_7_40C 255;
BA_ "GenSigInvalidValue" SG_ 1036 Reserved_72_7_40C 255;
BA_ "GenSigStartValue" SG_ 1036 Reserved_72_6_40C 255;
BA_ "GenSigInvalidValue" SG_ 1036 Reserved_72_6_40C 255;
BA_ "GenSigStartValue" SG_ 1036 Reserved_72_5_40C 255;
BA_ "GenSigInvalidValue" SG_ 1036 Reserved_72_5_40C 255;
BA_ "GenSigStartValue" SG_ 1036 Reserved_72_4_40C 255;
BA_ "GenSigInvalidValue" SG_ 1036 Reserved_72_4_40C 255;
BA_ "GenSigStartValue" SG_ 1036 Reserved_72_3_40C 255;
BA_ "GenSigInvalidValue" SG_ 1036 Reserved_72_3_40C 255;
BA_ "GenSigStartValue" SG_ 1036 Reserved_72_2_40C 255;
BA_ "GenSigInvalidValue" SG_ 1036 Reserved_72_2_40C 255;
BA_ "GenSigStartValue" SG_ 1036 Reserved_72_1_40C 255;
BA_ "GenSigInvalidValue" SG_ 1036 Reserved_72_1_40C 255;
BA_ "GenSigStartValue" SG_ 1036 Reserved_70_7_40C 255;
BA_ "GenSigInvalidValue" SG_ 1036 Reserved_70_7_40C 255;
BA_ "GenSigStartValue" SG_ 1036 Reserved_70_6_40C 255;
BA_ "GenSigInvalidValue" SG_ 1036 Reserved_70_6_40C 255;
BA_ "GenSigStartValue" SG_ 1036 Reserved_70_5_40C 255;
BA_ "GenSigInvalidValue" SG_ 1036 Reserved_70_5_40C 255;
BA_ "GenSigStartValue" SG_ 1036 Reserved_70_4_40C 255;
BA_ "GenSigInvalidValue" SG_ 1036 Reserved_70_4_40C 255;
BA_ "GenSigStartValue" SG_ 1036 Reserved_70_3_40C 255;
BA_ "GenSigInvalidValue" SG_ 1036 Reserved_70_3_40C 255;
BA_ "GenSigStartValue" SG_ 1036 Reserved_70_2_40C 255;
BA_ "GenSigInvalidValue" SG_ 1036 Reserved_70_2_40C 255;
BA_ "GenSigStartValue" SG_ 1036 Reserved_70_1_40C 255;
BA_ "GenSigInvalidValue" SG_ 1036 Reserved_70_1_40C 255;
BA_ "GenSigStartValue" SG_ 1036 Reserved_63_7_40C 255;
BA_ "GenSigInvalidValue" SG_ 1036 Reserved_63_7_40C 255;
BA_ "GenSigStartValue" SG_ 1036 Reserved_63_6_40C 255;
BA_ "GenSigInvalidValue" SG_ 1036 Reserved_63_6_40C 255;
BA_ "GenSigStartValue" SG_ 1036 Reserved_63_5_40C 255;
BA_ "GenSigInvalidValue" SG_ 1036 Reserved_63_5_40C 255;
BA_ "GenSigStartValue" SG_ 1036 Reserved_63_4_40C 255;
BA_ "GenSigInvalidValue" SG_ 1036 Reserved_63_4_40C 255;
BA_ "GenSigStartValue" SG_ 1036 Reserved_63_3_40C 255;
BA_ "GenSigInvalidValue" SG_ 1036 Reserved_63_3_40C 255;
BA_ "GenSigStartValue" SG_ 1036 Reserved_63_2_40C 255;
BA_ "GenSigInvalidValue" SG_ 1036 Reserved_63_2_40C 255;
BA_ "GenSigStartValue" SG_ 1036 Reserved_63_1_40C 255;
BA_ "GenSigInvalidValue" SG_ 1036 Reserved_63_1_40C 255;
BA_ "GenSigStartValue" SG_ 1036 Reserved_62_7_40C 255;
BA_ "GenSigInvalidValue" SG_ 1036 Reserved_62_7_40C 255;
BA_ "GenSigStartValue" SG_ 1036 Reserved_62_6_40C 255;
BA_ "GenSigInvalidValue" SG_ 1036 Reserved_62_6_40C 255;
BA_ "GenSigStartValue" SG_ 1036 Reserved_62_5_40C 255;
BA_ "GenSigInvalidValue" SG_ 1036 Reserved_62_5_40C 255;
BA_ "GenSigStartValue" SG_ 1036 Reserved_62_4_40C 255;
BA_ "GenSigInvalidValue" SG_ 1036 Reserved_62_4_40C 255;
BA_ "GenSigStartValue" SG_ 1036 Reserved_62_3_40C 255;
BA_ "GenSigInvalidValue" SG_ 1036 Reserved_62_3_40C 255;
BA_ "GenSigStartValue" SG_ 1036 Reserved_62_2_40C 255;
BA_ "GenSigInvalidValue" SG_ 1036 Reserved_62_2_40C 255;
BA_ "GenSigStartValue" SG_ 1036 Reserved_62_1_40C 255;
BA_ "GenSigInvalidValue" SG_ 1036 Reserved_62_1_40C 255;
BA_ "GenSigStartValue" SG_ 1036 Reserved_60_7_40C 255;
BA_ "GenSigInvalidValue" SG_ 1036 Reserved_60_7_40C 255;
BA_ "GenSigStartValue" SG_ 1036 Reserved_60_6_40C 255;
BA_ "GenSigInvalidValue" SG_ 1036 Reserved_60_6_40C 255;
BA_ "GenSigStartValue" SG_ 1036 Reserved_60_5_40C 255;
BA_ "GenSigInvalidValue" SG_ 1036 Reserved_60_5_40C 255;
BA_ "GenSigStartValue" SG_ 1036 Reserved_60_4_40C 255;
BA_ "GenSigInvalidValue" SG_ 1036 Reserved_60_4_40C 255;
BA_ "GenSigStartValue" SG_ 1036 Reserved_60_3_40C 255;
BA_ "GenSigInvalidValue" SG_ 1036 Reserved_60_3_40C 255;
BA_ "GenSigStartValue" SG_ 1036 Reserved_60_2_40C 255;
BA_ "GenSigInvalidValue" SG_ 1036 Reserved_60_2_40C 255;
BA_ "GenSigStartValue" SG_ 1036 Reserved_60_1_40C 255;
BA_ "GenSigInvalidValue" SG_ 1036 Reserved_60_1_40C 255;
BA_ "GenSigStartValue" SG_ 1036 Reserved_52_7_40C 255;
BA_ "GenSigInvalidValue" SG_ 1036 Reserved_52_7_40C 255;
BA_ "GenSigStartValue" SG_ 1036 Reserved_52_6_40C 255;
BA_ "GenSigInvalidValue" SG_ 1036 Reserved_52_6_40C 255;
BA_ "GenSigStartValue" SG_ 1036 Reserved_52_5_40C 255;
BA_ "GenSigInvalidValue" SG_ 1036 Reserved_52_5_40C 255;
BA_ "GenSigStartValue" SG_ 1036 Reserved_52_4_40C 255;
BA_ "GenSigInvalidValue" SG_ 1036 Reserved_52_4_40C 255;
BA_ "GenSigStartValue" SG_ 1036 Reserved_52_3_40C 255;
BA_ "GenSigInvalidValue" SG_ 1036 Reserved_52_3_40C 255;
BA_ "GenSigStartValue" SG_ 1036 Reserved_52_2_40C 255;
BA_ "GenSigInvalidValue" SG_ 1036 Reserved_52_2_40C 255;
BA_ "GenSigStartValue" SG_ 1036 Reserved_52_1_40C 255;
BA_ "GenSigInvalidValue" SG_ 1036 Reserved_52_1_40C 255;
BA_ "GenSigStartValue" SG_ 1036 Reserved_50_7_40C 255;
BA_ "GenSigInvalidValue" SG_ 1036 Reserved_50_7_40C 255;
BA_ "GenSigStartValue" SG_ 1036 Reserved_50_6_40C 255;
BA_ "GenSigInvalidValue" SG_ 1036 Reserved_50_6_40C 255;
BA_ "GenSigStartValue" SG_ 1036 Reserved_50_5_40C 255;
BA_ "GenSigInvalidValue" SG_ 1036 Reserved_50_5_40C 255;
BA_ "GenSigStartValue" SG_ 1036 Reserved_50_4_40C 255;
BA_ "GenSigInvalidValue" SG_ 1036 Reserved_50_4_40C 255;
BA_ "GenSigStartValue" SG_ 1036 Reserved_50_3_40C 255;
BA_ "GenSigInvalidValue" SG_ 1036 Reserved_50_3_40C 255;
BA_ "GenSigStartValue" SG_ 1036 Reserved_50_2_40C 255;
BA_ "GenSigInvalidValue" SG_ 1036 Reserved_50_2_40C 255;
BA_ "GenSigStartValue" SG_ 1036 Reserved_50_1_40C 255;
BA_ "GenSigInvalidValue" SG_ 1036 Reserved_50_1_40C 255;
BA_ "GenSigStartValue" SG_ 1036 Reserved_40_7_40C 255;
BA_ "GenSigInvalidValue" SG_ 1036 Reserved_40_7_40C 255;
BA_ "GenSigStartValue" SG_ 1036 Reserved_40_6_40C 255;
BA_ "GenSigInvalidValue" SG_ 1036 Reserved_40_6_40C 255;
BA_ "GenSigStartValue" SG_ 1036 Reserved_40_5_40C 255;
BA_ "GenSigInvalidValue" SG_ 1036 Reserved_40_5_40C 255;
BA_ "GenSigStartValue" SG_ 1036 Reserved_40_4_40C 255;
BA_ "GenSigInvalidValue" SG_ 1036 Reserved_40_4_40C 255;
BA_ "GenSigStartValue" SG_ 1036 Reserved_40_3_40C 255;
BA_ "GenSigInvalidValue" SG_ 1036 Reserved_40_3_40C 255;
BA_ "GenSigStartValue" SG_ 1036 Reserved_40_2_40C 255;
BA_ "GenSigInvalidValue" SG_ 1036 Reserved_40_2_40C 255;
BA_ "GenSigStartValue" SG_ 1036 Reserved_40_1_40C 255;
BA_ "GenSigInvalidValue" SG_ 1036 Reserved_40_1_40C 255;
BA_ "GenSigStartValue" SG_ 1036 Reserved_30_7_40C 255;
BA_ "GenSigInvalidValue" SG_ 1036 Reserved_30_7_40C 255;
BA_ "GenSigStartValue" SG_ 1036 Reserved_30_6_40C 255;
BA_ "GenSigInvalidValue" SG_ 1036 Reserved_30_6_40C 255;
BA_ "GenSigStartValue" SG_ 1036 Reserved_30_5_40C 255;
BA_ "GenSigInvalidValue" SG_ 1036 Reserved_30_5_40C 255;
BA_ "GenSigStartValue" SG_ 1036 Reserved_30_4_40C 255;
BA_ "GenSigInvalidValue" SG_ 1036 Reserved_30_4_40C 255;
BA_ "GenSigStartValue" SG_ 1036 Reserved_30_3_40C 255;
BA_ "GenSigInvalidValue" SG_ 1036 Reserved_30_3_40C 255;
BA_ "GenSigStartValue" SG_ 1036 Reserved_30_2_40C 255;
BA_ "GenSigInvalidValue" SG_ 1036 Reserved_30_2_40C 255;
BA_ "GenSigStartValue" SG_ 1036 Reserved_30_1_40C 255;
BA_ "GenSigInvalidValue" SG_ 1036 Reserved_30_1_40C 255;
BA_ "GenSigStartValue" SG_ 1036 Reserved_25_7_40C 255;
BA_ "GenSigInvalidValue" SG_ 1036 Reserved_25_7_40C 255;
BA_ "GenSigStartValue" SG_ 1036 Reserved_25_6_40C 255;
BA_ "GenSigInvalidValue" SG_ 1036 Reserved_25_6_40C 255;
BA_ "GenSigStartValue" SG_ 1036 Reserved_25_5_40C 255;
BA_ "GenSigInvalidValue" SG_ 1036 Reserved_25_5_40C 255;
BA_ "GenSigStartValue" SG_ 1036 Reserved_25_4_40C 255;
BA_ "GenSigInvalidValue" SG_ 1036 Reserved_25_4_40C 255;
BA_ "GenSigStartValue" SG_ 1036 Reserved_25_3_40C 255;
BA_ "GenSigInvalidValue" SG_ 1036 Reserved_25_3_40C 255;
BA_ "GenSigStartValue" SG_ 1036 Reserved_25_2_40C 255;
BA_ "GenSigInvalidValue" SG_ 1036 Reserved_25_2_40C 255;
BA_ "GenSigStartValue" SG_ 1036 Reserved_25_1_40C 255;
BA_ "GenSigInvalidValue" SG_ 1036 Reserved_25_1_40C 255;
BA_ "GenSigStartValue" SG_ 1036 Reserved_20_7_40C 255;
BA_ "GenSigInvalidValue" SG_ 1036 Reserved_20_7_40C 255;
BA_ "GenSigStartValue" SG_ 1036 Reserved_20_6_40C 255;
BA_ "GenSigInvalidValue" SG_ 1036 Reserved_20_6_40C 255;
BA_ "GenSigStartValue" SG_ 1036 Reserved_20_5_40C 255;
BA_ "GenSigInvalidValue" SG_ 1036 Reserved_20_5_40C 255;
BA_ "GenSigStartValue" SG_ 1036 Reserved_20_4_40C 255;
BA_ "GenSigInvalidValue" SG_ 1036 Reserved_20_4_40C 255;
BA_ "GenSigStartValue" SG_ 1036 Reserved_20_3_40C 255;
BA_ "GenSigInvalidValue" SG_ 1036 Reserved_20_3_40C 255;
BA_ "GenSigStartValue" SG_ 1036 Reserved_20_2_40C 255;
BA_ "GenSigInvalidValue" SG_ 1036 Reserved_20_2_40C 255;
BA_ "GenSigStartValue" SG_ 1036 Reserved_20_1_40C 255;
BA_ "GenSigInvalidValue" SG_ 1036 Reserved_20_1_40C 255;
BA_ "GenSigStartValue" SG_ 1036 Reserved_16_7_40C 255;
BA_ "GenSigInvalidValue" SG_ 1036 Reserved_16_7_40C 255;
BA_ "GenSigStartValue" SG_ 1036 Reserved_16_6_40C 255;
BA_ "GenSigInvalidValue" SG_ 1036 Reserved_16_6_40C 255;
BA_ "GenSigStartValue" SG_ 1036 Reserved_16_5_40C 255;
BA_ "GenSigInvalidValue" SG_ 1036 Reserved_16_5_40C 255;
BA_ "GenSigStartValue" SG_ 1036 Reserved_16_4_40C 255;
BA_ "GenSigInvalidValue" SG_ 1036 Reserved_16_4_40C 255;
BA_ "GenSigStartValue" SG_ 1036 Reserved_16_3_40C 255;
BA_ "GenSigInvalidValue" SG_ 1036 Reserved_16_3_40C 255;
BA_ "GenSigStartValue" SG_ 1036 Reserved_16_2_40C 255;
BA_ "GenSigInvalidValue" SG_ 1036 Reserved_16_2_40C 255;
BA_ "GenSigStartValue" SG_ 1036 Reserved_16_1_40C 255;
BA_ "GenSigInvalidValue" SG_ 1036 Reserved_16_1_40C 255;
BA_ "GenSigStartValue" SG_ 1036 Reserved_15_7_40C 255;
BA_ "GenSigInvalidValue" SG_ 1036 Reserved_15_7_40C 255;
BA_ "GenSigStartValue" SG_ 1036 Reserved_15_6_40C 255;
BA_ "GenSigInvalidValue" SG_ 1036 Reserved_15_6_40C 255;
BA_ "GenSigStartValue" SG_ 1036 Reserved_15_5_40C 255;
BA_ "GenSigInvalidValue" SG_ 1036 Reserved_15_5_40C 255;
BA_ "GenSigStartValue" SG_ 1036 Reserved_15_4_40C 255;
BA_ "GenSigInvalidValue" SG_ 1036 Reserved_15_4_40C 255;
BA_ "GenSigStartValue" SG_ 1036 Reserved_15_3_40C 255;
BA_ "GenSigInvalidValue" SG_ 1036 Reserved_15_3_40C 255;
BA_ "GenSigStartValue" SG_ 1036 Reserved_15_2_40C 255;
BA_ "GenSigInvalidValue" SG_ 1036 Reserved_15_2_40C 255;
BA_ "GenSigStartValue" SG_ 1036 Reserved_15_1_40C 255;
BA_ "GenSigInvalidValue" SG_ 1036 Reserved_15_1_40C 255;
BA_ "GenSigStartValue" SG_ 1036 Reserved_14_7_40C 255;
BA_ "GenSigInvalidValue" SG_ 1036 Reserved_14_7_40C 255;
BA_ "GenSigStartValue" SG_ 1036 Reserved_14_6_40C 255;
BA_ "GenSigInvalidValue" SG_ 1036 Reserved_14_6_40C 255;
BA_ "GenSigStartValue" SG_ 1036 Reserved_14_5_40C 255;
BA_ "GenSigInvalidValue" SG_ 1036 Reserved_14_5_40C 255;
BA_ "GenSigStartValue" SG_ 1036 Reserved_14_4_40C 255;
BA_ "GenSigInvalidValue" SG_ 1036 Reserved_14_4_40C 255;
BA_ "GenSigStartValue" SG_ 1036 Reserved_14_3_40C 255;
BA_ "GenSigInvalidValue" SG_ 1036 Reserved_14_3_40C 255;
BA_ "GenSigStartValue" SG_ 1036 Reserved_14_2_40C 255;
BA_ "GenSigInvalidValue" SG_ 1036 Reserved_14_2_40C 255;
BA_ "GenSigStartValue" SG_ 1036 Reserved_14_1_40C 255;
BA_ "GenSigInvalidValue" SG_ 1036 Reserved_14_1_40C 255;
BA_ "GenSigStartValue" SG_ 1036 Reserved_13_7_40C 255;
BA_ "GenSigInvalidValue" SG_ 1036 Reserved_13_7_40C 255;
BA_ "GenSigStartValue" SG_ 1036 Reserved_13_6_40C 255;
BA_ "GenSigInvalidValue" SG_ 1036 Reserved_13_6_40C 255;
BA_ "GenSigStartValue" SG_ 1036 Reserved_13_5_40C 255;
BA_ "GenSigInvalidValue" SG_ 1036 Reserved_13_5_40C 255;
BA_ "GenSigStartValue" SG_ 1036 Reserved_13_4_40C 255;
BA_ "GenSigInvalidValue" SG_ 1036 Reserved_13_4_40C 255;
BA_ "GenSigStartValue" SG_ 1036 Reserved_13_3_40C 255;
BA_ "GenSigInvalidValue" SG_ 1036 Reserved_13_3_40C 255;
BA_ "GenSigStartValue" SG_ 1036 Reserved_13_2_40C 255;
BA_ "GenSigInvalidValue" SG_ 1036 Reserved_13_2_40C 255;
BA_ "GenSigStartValue" SG_ 1036 Reserved_13_1_40C 255;
BA_ "GenSigInvalidValue" SG_ 1036 Reserved_13_1_40C 255;
BA_ "GenSigStartValue" SG_ 1036 Reserved_12_7_40C 255;
BA_ "GenSigInvalidValue" SG_ 1036 Reserved_12_7_40C 255;
BA_ "GenSigStartValue" SG_ 1036 Reserved_12_6_40C 255;
BA_ "GenSigInvalidValue" SG_ 1036 Reserved_12_6_40C 255;
BA_ "GenSigStartValue" SG_ 1036 Reserved_12_5_40C 255;
BA_ "GenSigInvalidValue" SG_ 1036 Reserved_12_5_40C 255;
BA_ "GenSigStartValue" SG_ 1036 Reserved_12_4_40C 255;
BA_ "GenSigInvalidValue" SG_ 1036 Reserved_12_4_40C 255;
BA_ "GenSigStartValue" SG_ 1036 Reserved_12_3_40C 255;
BA_ "GenSigInvalidValue" SG_ 1036 Reserved_12_3_40C 255;
BA_ "GenSigStartValue" SG_ 1036 Reserved_12_2_40C 255;
BA_ "GenSigInvalidValue" SG_ 1036 Reserved_12_2_40C 255;
BA_ "GenSigStartValue" SG_ 1036 Reserved_12_1_40C 255;
BA_ "GenSigInvalidValue" SG_ 1036 Reserved_12_1_40C 255;
BA_ "GenSigStartValue" SG_ 1036 Reserved_11_7_40C 255;
BA_ "GenSigInvalidValue" SG_ 1036 Reserved_11_7_40C 255;
BA_ "GenSigStartValue" SG_ 1036 Reserved_11_6_40C 255;
BA_ "GenSigInvalidValue" SG_ 1036 Reserved_11_6_40C 255;
BA_ "GenSigStartValue" SG_ 1036 Reserved_11_5_40C 255;
BA_ "GenSigInvalidValue" SG_ 1036 Reserved_11_5_40C 255;
BA_ "GenSigStartValue" SG_ 1036 Reserved_11_4_40C 255;
BA_ "GenSigInvalidValue" SG_ 1036 Reserved_11_4_40C 255;
BA_ "GenSigStartValue" SG_ 1036 Country_3 255;
BA_ "GenSigInvalidValue" SG_ 1036 Country_3 255;
BA_ "GenSigStartValue" SG_ 1036 Country_2 255;
BA_ "GenSigInvalidValue" SG_ 1036 Country_2 255;
BA_ "GenSigStartValue" SG_ 1036 Country_1 255;
BA_ "GenSigInvalidValue" SG_ 1036 Country_1 255;
BA_ "GenSigStartValue" SG_ 1036 AIC_14 255;
BA_ "GenSigInvalidValue" SG_ 1036 AIC_14 255;
BA_ "GenSigStartValue" SG_ 1036 AIC_13 255;
BA_ "GenSigInvalidValue" SG_ 1036 AIC_13 255;
BA_ "GenSigStartValue" SG_ 1036 AIC_12 255;
BA_ "GenSigInvalidValue" SG_ 1036 AIC_12 255;
BA_ "GenSigStartValue" SG_ 1036 AIC_11 255;
BA_ "GenSigInvalidValue" SG_ 1036 AIC_11 255;
BA_ "GenSigStartValue" SG_ 1036 AIC_10 255;
BA_ "GenSigInvalidValue" SG_ 1036 AIC_10 255;
BA_ "GenSigStartValue" SG_ 1036 AIC_09 255;
BA_ "GenSigInvalidValue" SG_ 1036 AIC_09 255;
BA_ "GenSigStartValue" SG_ 1036 AIC_08 255;
BA_ "GenSigInvalidValue" SG_ 1036 AIC_08 255;
BA_ "GenSigStartValue" SG_ 1036 AIC_07 255;
BA_ "GenSigInvalidValue" SG_ 1036 AIC_07 255;
BA_ "GenSigStartValue" SG_ 1036 AIC_06 255;
BA_ "GenSigInvalidValue" SG_ 1036 AIC_06 255;
BA_ "GenSigStartValue" SG_ 1036 AIC_05 255;
BA_ "GenSigInvalidValue" SG_ 1036 AIC_05 255;
BA_ "GenSigStartValue" SG_ 1036 AIC_04 255;
BA_ "GenSigInvalidValue" SG_ 1036 AIC_04 255;
BA_ "GenSigStartValue" SG_ 1036 AIC_03 255;
BA_ "GenSigInvalidValue" SG_ 1036 AIC_03 255;
BA_ "GenSigStartValue" SG_ 1036 AIC_02 255;
BA_ "GenSigInvalidValue" SG_ 1036 AIC_02 255;
BA_ "GenSigStartValue" SG_ 1036 AIC_01 255;
BA_ "GenSigInvalidValue" SG_ 1036 AIC_01 255;
BA_ "GenSigStartValue" SG_ 1036 Reserved_05_1_40C 16777215;
BA_ "GenSigInvalidValue" SG_ 1036 Reserved_05_1_40C 16777215;
BA_ "GenSigStartValue" SG_ 1036 Project_Code_4th_40C 255;
BA_ "GenSigInvalidValue" SG_ 1036 Project_Code_4th_40C 255;
BA_ "GenSigStartValue" SG_ 1036 Project_Code_3rd_40C 255;
BA_ "GenSigInvalidValue" SG_ 1036 Project_Code_3rd_40C 255;
BA_ "GenSigStartValue" SG_ 1036 Project_Code_2nd_40C 255;
BA_ "GenSigInvalidValue" SG_ 1036 Project_Code_2nd_40C 255;
BA_ "GenSigStartValue" SG_ 1036 Project_Code_1st_40C 255;
BA_ "GenSigInvalidValue" SG_ 1036 Project_Code_1st_40C 255;
BA_ "GenSigStartValue" SG_ 1036 Outer_Color_3_40C 255;
BA_ "GenSigInvalidValue" SG_ 1036 Outer_Color_3_40C 255;
BA_ "GenSigStartValue" SG_ 1036 Outer_Color_2_40C 255;
BA_ "GenSigInvalidValue" SG_ 1036 Outer_Color_2_40C 255;
BA_ "GenSigStartValue" SG_ 1036 Outer_Color_1_40C 255;
BA_ "GenSigInvalidValue" SG_ 1036 Outer_Color_1_40C 255;
BA_ "GenSigStartValue" SG_ 1036 Unit_Serial_Number_40C 255;
BA_ "GenSigInvalidValue" SG_ 1036 Unit_Serial_Number_40C 255;
BA_ "GenSigStartValue" SG_ 1036 Unit_Destination_40C 255;
BA_ "GenSigInvalidValue" SG_ 1036 Unit_Destination_40C 255;
BA_ "GenSigStartValue" SG_ 1036 Unit_Series_40C 255;
BA_ "GenSigInvalidValue" SG_ 1036 Unit_Series_40C 255;
BA_ "GenSigStartValue" SG_ 1036 Unit_Car_Line_40C 255;
BA_ "GenSigInvalidValue" SG_ 1036 Unit_Car_Line_40C 255;
BA_ "GenSigStartValue" SG_ 1036 VIN_Character_21_40C 255;
BA_ "GenSigInvalidValue" SG_ 1036 VIN_Character_21_40C 255;
BA_ "GenSigStartValue" SG_ 1036 VIN_Character_20_40C 255;
BA_ "GenSigInvalidValue" SG_ 1036 VIN_Character_20_40C 255;
BA_ "GenSigStartValue" SG_ 1036 VIN_Character_19_40C 255;
BA_ "GenSigInvalidValue" SG_ 1036 VIN_Character_19_40C 255;
BA_ "GenSigStartValue" SG_ 1036 VIN_Character_18_40C 255;
BA_ "GenSigInvalidValue" SG_ 1036 VIN_Character_18_40C 255;
BA_ "GenSigStartValue" SG_ 1036 VIN_Character_17_40C 255;
BA_ "GenSigInvalidValue" SG_ 1036 VIN_Character_17_40C 255;
BA_ "GenSigStartValue" SG_ 1036 VIN_Character_16_40C 255;
BA_ "GenSigInvalidValue" SG_ 1036 VIN_Character_16_40C 255;
BA_ "GenSigStartValue" SG_ 1036 VIN_Character_15_40C 255;
BA_ "GenSigInvalidValue" SG_ 1036 VIN_Character_15_40C 255;
BA_ "GenSigStartValue" SG_ 1036 VIN_Character_14_40C 255;
BA_ "GenSigInvalidValue" SG_ 1036 VIN_Character_14_40C 255;
BA_ "GenSigStartValue" SG_ 1036 VIN_Character_13_40C 255;
BA_ "GenSigInvalidValue" SG_ 1036 VIN_Character_13_40C 255;
BA_ "GenSigStartValue" SG_ 1036 VIN_Character_12_40C 255;
BA_ "GenSigInvalidValue" SG_ 1036 VIN_Character_12_40C 255;
BA_ "GenSigStartValue" SG_ 1036 VIN_Character_11_40C 255;
BA_ "GenSigInvalidValue" SG_ 1036 VIN_Character_11_40C 255;
BA_ "GenSigStartValue" SG_ 1036 VIN_Character_10_40C 255;
BA_ "GenSigInvalidValue" SG_ 1036 VIN_Character_10_40C 255;
BA_ "GenSigStartValue" SG_ 1036 VIN_Character_09_40C 255;
BA_ "GenSigInvalidValue" SG_ 1036 VIN_Character_09_40C 255;
BA_ "GenSigStartValue" SG_ 1036 VIN_Character_08_40C 255;
BA_ "GenSigInvalidValue" SG_ 1036 VIN_Character_08_40C 255;
BA_ "GenSigStartValue" SG_ 1036 VIN_Character_07_40C 255;
BA_ "GenSigInvalidValue" SG_ 1036 VIN_Character_07_40C 255;
BA_ "GenSigStartValue" SG_ 1036 VIN_Character_06_40C 255;
BA_ "GenSigInvalidValue" SG_ 1036 VIN_Character_06_40C 255;
BA_ "GenSigStartValue" SG_ 1036 VIN_Character_05_40C 255;
BA_ "GenSigInvalidValue" SG_ 1036 VIN_Character_05_40C 255;
BA_ "GenSigStartValue" SG_ 1036 VIN_Character_04_40C 255;
BA_ "GenSigInvalidValue" SG_ 1036 VIN_Character_04_40C 255;
BA_ "GenSigStartValue" SG_ 1036 VIN_Character_03_40C 255;
BA_ "GenSigInvalidValue" SG_ 1036 VIN_Character_03_40C 255;
BA_ "GenSigStartValue" SG_ 1036 VIN_Character_02_40C 255;
BA_ "GenSigInvalidValue" SG_ 1036 VIN_Character_02_40C 255;
BA_ "GenSigStartValue" SG_ 1036 VIN_Character_01_40C 255;
BA_ "GenSigInvalidValue" SG_ 1036 VIN_Character_01_40C 255;
BA_ "GenSigStartValue" SG_ 1034 Central_CRC 65535;
BA_ "GenSigInvalidValue" SG_ 1034 Central_CRC 65535;
BA_ "GenSigStartValue" SG_ 1034 CDID_Total_Number 255;
BA_ "GenSigInvalidValue" SG_ 1034 CDID_Total_Number 255;
BA_ "GenSigStartValue" SG_ 1034 Reserved_E0_2 65535;
BA_ "GenSigInvalidValue" SG_ 1034 Reserved_E0_2 65535;
BA_ "GenSigStartValue" SG_ 1034 Reserved_E0_1 65535;
BA_ "GenSigInvalidValue" SG_ 1034 Reserved_E0_1 65535;
BA_ "GenSigStartValue" SG_ 1034 Reserved_95_7 255;
BA_ "GenSigInvalidValue" SG_ 1034 Reserved_95_7 255;
BA_ "GenSigStartValue" SG_ 1034 Reserved_95_6 255;
BA_ "GenSigInvalidValue" SG_ 1034 Reserved_95_6 255;
BA_ "GenSigStartValue" SG_ 1034 Reserved_95_5 255;
BA_ "GenSigInvalidValue" SG_ 1034 Reserved_95_5 255;
BA_ "GenSigStartValue" SG_ 1034 Reserved_95_4 255;
BA_ "GenSigInvalidValue" SG_ 1034 Reserved_95_4 255;
BA_ "GenSigStartValue" SG_ 1034 Reserved_95_3 255;
BA_ "GenSigInvalidValue" SG_ 1034 Reserved_95_3 255;
BA_ "GenSigStartValue" SG_ 1034 Reserved_95_2 255;
BA_ "GenSigInvalidValue" SG_ 1034 Reserved_95_2 255;
BA_ "GenSigStartValue" SG_ 1034 Reserved_95_1 255;
BA_ "GenSigInvalidValue" SG_ 1034 Reserved_95_1 255;
BA_ "GenSigStartValue" SG_ 1034 Reserved_94_7 255;
BA_ "GenSigInvalidValue" SG_ 1034 Reserved_94_7 255;
BA_ "GenSigStartValue" SG_ 1034 Reserved_94_6 255;
BA_ "GenSigInvalidValue" SG_ 1034 Reserved_94_6 255;
BA_ "GenSigStartValue" SG_ 1034 Reserved_94_5 255;
BA_ "GenSigInvalidValue" SG_ 1034 Reserved_94_5 255;
BA_ "GenSigStartValue" SG_ 1034 Reserved_94_4 255;
BA_ "GenSigInvalidValue" SG_ 1034 Reserved_94_4 255;
BA_ "GenSigStartValue" SG_ 1034 Reserved_94_3 255;
BA_ "GenSigInvalidValue" SG_ 1034 Reserved_94_3 255;
BA_ "GenSigStartValue" SG_ 1034 Reserved_94_2 255;
BA_ "GenSigInvalidValue" SG_ 1034 Reserved_94_2 255;
BA_ "GenSigStartValue" SG_ 1034 Reserved_94_1 255;
BA_ "GenSigInvalidValue" SG_ 1034 Reserved_94_1 255;
BA_ "GenSigStartValue" SG_ 1034 Reserved_93_7 255;
BA_ "GenSigInvalidValue" SG_ 1034 Reserved_93_7 255;
BA_ "GenSigStartValue" SG_ 1034 Reserved_93_6 255;
BA_ "GenSigInvalidValue" SG_ 1034 Reserved_93_6 255;
BA_ "GenSigStartValue" SG_ 1034 Reserved_93_5 255;
BA_ "GenSigInvalidValue" SG_ 1034 Reserved_93_5 255;
BA_ "GenSigStartValue" SG_ 1034 Reserved_93_4 255;
BA_ "GenSigInvalidValue" SG_ 1034 Reserved_93_4 255;
BA_ "GenSigStartValue" SG_ 1034 Reserved_93_3 255;
BA_ "GenSigInvalidValue" SG_ 1034 Reserved_93_3 255;
BA_ "GenSigStartValue" SG_ 1034 Reserved_93_2 255;
BA_ "GenSigInvalidValue" SG_ 1034 Reserved_93_2 255;
BA_ "GenSigStartValue" SG_ 1034 Reserved_93_1 255;
BA_ "GenSigInvalidValue" SG_ 1034 Reserved_93_1 255;
BA_ "GenSigStartValue" SG_ 1034 Reserved_92_7 255;
BA_ "GenSigInvalidValue" SG_ 1034 Reserved_92_7 255;
BA_ "GenSigStartValue" SG_ 1034 Reserved_92_6 255;
BA_ "GenSigInvalidValue" SG_ 1034 Reserved_92_6 255;
BA_ "GenSigStartValue" SG_ 1034 Reserved_92_5 255;
BA_ "GenSigInvalidValue" SG_ 1034 Reserved_92_5 255;
BA_ "GenSigStartValue" SG_ 1034 Reserved_92_4 255;
BA_ "GenSigInvalidValue" SG_ 1034 Reserved_92_4 255;
BA_ "GenSigStartValue" SG_ 1034 Reserved_92_3 255;
BA_ "GenSigInvalidValue" SG_ 1034 Reserved_92_3 255;
BA_ "GenSigStartValue" SG_ 1034 Reserved_92_2 255;
BA_ "GenSigInvalidValue" SG_ 1034 Reserved_92_2 255;
BA_ "GenSigStartValue" SG_ 1034 ADAS_VARIATION_1 255;
BA_ "GenSigInvalidValue" SG_ 1034 ADAS_VARIATION_1 255;
BA_ "GenSigStartValue" SG_ 1034 Reserved_91_7 255;
BA_ "GenSigInvalidValue" SG_ 1034 Reserved_91_7 255;
BA_ "GenSigStartValue" SG_ 1034 Reserved_91_6 255;
BA_ "GenSigInvalidValue" SG_ 1034 Reserved_91_6 255;
BA_ "GenSigStartValue" SG_ 1034 Reserved_91_5 255;
BA_ "GenSigInvalidValue" SG_ 1034 Reserved_91_5 255;
BA_ "GenSigStartValue" SG_ 1034 Reserved_91_4 255;
BA_ "GenSigInvalidValue" SG_ 1034 Reserved_91_4 255;
BA_ "GenSigStartValue" SG_ 1034 ADAS_COUNTRY_3 255;
BA_ "GenSigInvalidValue" SG_ 1034 ADAS_COUNTRY_3 255;
BA_ "GenSigStartValue" SG_ 1034 ADAS_COUNTRY_2 255;
BA_ "GenSigInvalidValue" SG_ 1034 ADAS_COUNTRY_2 255;
BA_ "GenSigStartValue" SG_ 1034 ADAS_COUNTRY_1 255;
BA_ "GenSigInvalidValue" SG_ 1034 ADAS_COUNTRY_1 255;
BA_ "GenSigStartValue" SG_ 1034 Reserved_90_7 255;
BA_ "GenSigInvalidValue" SG_ 1034 Reserved_90_7 255;
BA_ "GenSigStartValue" SG_ 1034 Reserved_90_6 255;
BA_ "GenSigInvalidValue" SG_ 1034 Reserved_90_6 255;
BA_ "GenSigStartValue" SG_ 1034 PRECEDING_VEHICLE_NOTIFICATION 255;
BA_ "GenSigInvalidValue" SG_ 1034 PRECEDING_VEHICLE_NOTIFICATION 255;
BA_ "GenSigStartValue" SG_ 1034 Reserved_90_4 255;
BA_ "GenSigInvalidValue" SG_ 1034 Reserved_90_4 255;
BA_ "GenSigStartValue" SG_ 1034 Reserved_90_3 255;
BA_ "GenSigInvalidValue" SG_ 1034 Reserved_90_3 255;
BA_ "GenSigStartValue" SG_ 1034 FR_POSITION_TYPE 255;
BA_ "GenSigInvalidValue" SG_ 1034 FR_POSITION_TYPE 255;
BA_ "GenSigStartValue" SG_ 1034 RBUMPER_SHAPE_TYPE 255;
BA_ "GenSigInvalidValue" SG_ 1034 RBUMPER_SHAPE_TYPE 255;
BA_ "GenSigStartValue" SG_ 1034 Reserved_82_8 15;
BA_ "GenSigInvalidValue" SG_ 1034 Reserved_82_8 15;
BA_ "GenSigStartValue" SG_ 1034 IP_DECORATION_ILLUMI 15;
BA_ "GenSigInvalidValue" SG_ 1034 IP_DECORATION_ILLUMI 15;
BA_ "GenSigStartValue" SG_ 1034 DRIVE_RECORDER 15;
BA_ "GenSigInvalidValue" SG_ 1034 DRIVE_RECORDER 15;
BA_ "GenSigStartValue" SG_ 1034 ALEXA 15;
BA_ "GenSigInvalidValue" SG_ 1034 ALEXA 15;
BA_ "GenSigStartValue" SG_ 1034 ASE_SYSTEM 15;
BA_ "GenSigInvalidValue" SG_ 1034 ASE_SYSTEM 15;
BA_ "GenSigStartValue" SG_ 1034 WIRELESS_CHARGE 15;
BA_ "GenSigInvalidValue" SG_ 1034 WIRELESS_CHARGE 15;
BA_ "GenSigStartValue" SG_ 1034 FBUMPER_ASSY_TYPE 15;
BA_ "GenSigInvalidValue" SG_ 1034 FBUMPER_ASSY_TYPE 15;
BA_ "GenSigStartValue" SG_ 1034 FBUMPER_SHAPE_TYPE 15;
BA_ "GenSigInvalidValue" SG_ 1034 FBUMPER_SHAPE_TYPE 15;
BA_ "GenSigStartValue" SG_ 1034 EMERGENCY_DRIVER_ASSIST 15;
BA_ "GenSigInvalidValue" SG_ 1034 EMERGENCY_DRIVER_ASSIST 15;
BA_ "GenSigStartValue" SG_ 1034 VMC_COMMUNICATION_TYPE 15;
BA_ "GenSigInvalidValue" SG_ 1034 VMC_COMMUNICATION_TYPE 15;
BA_ "GenSigStartValue" SG_ 1034 VMC_POSITION 3;
BA_ "GenSigInvalidValue" SG_ 1034 VMC_POSITION 3;
BA_ "GenSigStartValue" SG_ 1034 Reserved_82_3 3;
BA_ "GenSigInvalidValue" SG_ 1034 Reserved_82_3 3;
BA_ "GenSigStartValue" SG_ 1034 INTERSECTION_BRAKE_SUPP 15;
BA_ "GenSigInvalidValue" SG_ 1034 INTERSECTION_BRAKE_SUPP 15;
BA_ "GenSigStartValue" SG_ 1034 PERSONALIZE_SYSTEM 15;
BA_ "GenSigInvalidValue" SG_ 1034 PERSONALIZE_SYSTEM 15;
BA_ "GenSigStartValue" SG_ 1034 TAP 15;
BA_ "GenSigInvalidValue" SG_ 1034 TAP 15;
BA_ "GenSigStartValue" SG_ 1034 Reserved_80_5 15;
BA_ "GenSigInvalidValue" SG_ 1034 Reserved_80_5 15;
BA_ "GenSigStartValue" SG_ 1034 ENGINE_POWER_TYPE 15;
BA_ "GenSigInvalidValue" SG_ 1034 ENGINE_POWER_TYPE 15;
BA_ "GenSigStartValue" SG_ 1034 Number_Of_Cylinders 15;
BA_ "GenSigInvalidValue" SG_ 1034 Number_Of_Cylinders 15;
BA_ "GenSigStartValue" SG_ 1034 TURBO_ENGINE 15;
BA_ "GenSigInvalidValue" SG_ 1034 TURBO_ENGINE 15;
BA_ "GenSigStartValue" SG_ 1034 CYLINDER_DEACTIVATION 15;
BA_ "GenSigInvalidValue" SG_ 1034 CYLINDER_DEACTIVATION 15;
BA_ "GenSigStartValue" SG_ 1034 UPGRADE_ENGINE 15;
BA_ "GenSigInvalidValue" SG_ 1034 UPGRADE_ENGINE 15;
BA_ "GenSigStartValue" SG_ 1034 ENGINE_TYPE 255;
BA_ "GenSigInvalidValue" SG_ 1034 ENGINE_TYPE 255;
BA_ "GenSigStartValue" SG_ 1034 Reserved_80_3 15;
BA_ "GenSigInvalidValue" SG_ 1034 Reserved_80_3 15;
BA_ "GenSigStartValue" SG_ 1034 AC_CHARGING_TYPE 15;
BA_ "GenSigInvalidValue" SG_ 1034 AC_CHARGING_TYPE 15;
BA_ "GenSigStartValue" SG_ 1034 DC_CHARGING_TYPE 15;
BA_ "GenSigInvalidValue" SG_ 1034 DC_CHARGING_TYPE 15;
BA_ "GenSigStartValue" SG_ 1034 AUX_POWER_UNIT 15;
BA_ "GenSigInvalidValue" SG_ 1034 AUX_POWER_UNIT 15;
BA_ "GenSigStartValue" SG_ 1034 Reserved_80_1 15;
BA_ "GenSigInvalidValue" SG_ 1034 Reserved_80_1 15;
BA_ "GenSigStartValue" SG_ 1034 XEV_TYPE 15;
BA_ "GenSigInvalidValue" SG_ 1034 XEV_TYPE 15;
BA_ "GenSigStartValue" SG_ 1034 Reserved_72_4 3;
BA_ "GenSigInvalidValue" SG_ 1034 Reserved_72_4 3;
BA_ "GenSigStartValue" SG_ 1034 REMOTE_ENGINE_START_OPT 3;
BA_ "GenSigInvalidValue" SG_ 1034 REMOTE_ENGINE_START_OPT 3;
BA_ "GenSigStartValue" SG_ 1034 DOWN_LIGHT 3;
BA_ "GenSigInvalidValue" SG_ 1034 DOWN_LIGHT 3;
BA_ "GenSigStartValue" SG_ 1034 KEYLESS_WINDOW_CONTROL 3;
BA_ "GenSigInvalidValue" SG_ 1034 KEYLESS_WINDOW_CONTROL 3;
BA_ "GenSigStartValue" SG_ 1034 KEY_LESS_COMPT 3;
BA_ "GenSigInvalidValue" SG_ 1034 KEY_LESS_COMPT 3;
BA_ "GenSigStartValue" SG_ 1034 SMART_KEYLESS 3;
BA_ "GenSigInvalidValue" SG_ 1034 SMART_KEYLESS 3;
BA_ "GenSigStartValue" SG_ 1034 KEY_LESS_ENTRY 15;
BA_ "GenSigInvalidValue" SG_ 1034 KEY_LESS_ENTRY 15;
BA_ "GenSigStartValue" SG_ 1034 Reserved_72_2 15;
BA_ "GenSigInvalidValue" SG_ 1034 Reserved_72_2 15;
BA_ "GenSigStartValue" SG_ 1034 PGR_AIR_BAG_CUT_INDICATOR 15;
BA_ "GenSigInvalidValue" SG_ 1034 PGR_AIR_BAG_CUT_INDICATOR 15;
BA_ "GenSigStartValue" SG_ 1034 REMINDER_CONTROL_SPEC 255;
BA_ "GenSigInvalidValue" SG_ 1034 REMINDER_CONTROL_SPEC 255;
BA_ "GenSigStartValue" SG_ 1034 SEAT_BELT_WARNING_SYSTEM 15;
BA_ "GenSigInvalidValue" SG_ 1034 SEAT_BELT_WARNING_SYSTEM 15;
BA_ "GenSigStartValue" SG_ 1034 OCCUPANT_SENSING_SYSTEM 15;
BA_ "GenSigInvalidValue" SG_ 1034 OCCUPANT_SENSING_SYSTEM 15;
BA_ "GenSigStartValue" SG_ 1034 Reserved_70_4 255;
BA_ "GenSigInvalidValue" SG_ 1034 Reserved_70_4 255;
BA_ "GenSigStartValue" SG_ 1034 R_SEAT_NO2_TYPE 15;
BA_ "GenSigInvalidValue" SG_ 1034 R_SEAT_NO2_TYPE 15;
BA_ "GenSigStartValue" SG_ 1034 R_SEAT_NO1_TYPE 15;
BA_ "GenSigInvalidValue" SG_ 1034 R_SEAT_NO1_TYPE 15;
BA_ "GenSigStartValue" SG_ 1034 EXTERIOR_ALERT_TYPE 15;
BA_ "GenSigInvalidValue" SG_ 1034 EXTERIOR_ALERT_TYPE 15;
BA_ "GenSigStartValue" SG_ 1034 CPD_CONTROL_TYPE 15;
BA_ "GenSigInvalidValue" SG_ 1034 CPD_CONTROL_TYPE 15;
BA_ "GenSigStartValue" SG_ 1034 Reserved_70_3 3;
BA_ "GenSigInvalidValue" SG_ 1034 Reserved_70_3 3;
BA_ "GenSigStartValue" SG_ 1034 F_SEAT_VENTILATION 3;
BA_ "GenSigInvalidValue" SG_ 1034 F_SEAT_VENTILATION 3;
BA_ "GenSigStartValue" SG_ 1034 F_SEAT_TYPE 15;
BA_ "GenSigInvalidValue" SG_ 1034 F_SEAT_TYPE 15;
BA_ "GenSigStartValue" SG_ 1034 Reserved_70_2 3;
BA_ "GenSigInvalidValue" SG_ 1034 Reserved_70_2 3;
BA_ "GenSigStartValue" SG_ 1034 R_SEAT_WARMER 3;
BA_ "GenSigInvalidValue" SG_ 1034 R_SEAT_WARMER 3;
BA_ "GenSigStartValue" SG_ 1034 F_SEAT_WARMER 15;
BA_ "GenSigInvalidValue" SG_ 1034 F_SEAT_WARMER 15;
BA_ "GenSigStartValue" SG_ 1034 Reserved_70_1 15;
BA_ "GenSigInvalidValue" SG_ 1034 Reserved_70_1 15;
BA_ "GenSigStartValue" SG_ 1034 F_SEAT_LIFT_MECHANISM 15;
BA_ "GenSigInvalidValue" SG_ 1034 F_SEAT_LIFT_MECHANISM 15;
BA_ "GenSigStartValue" SG_ 1034 SEAT_MATERIAL 255;
BA_ "GenSigInvalidValue" SG_ 1034 SEAT_MATERIAL 255;
BA_ "GenSigStartValue" SG_ 1034 Reserved_63_1 255;
BA_ "GenSigInvalidValue" SG_ 1034 Reserved_63_1 255;
BA_ "GenSigStartValue" SG_ 1034 Vehicle_Height 65535;
BA_ "GenSigInvalidValue" SG_ 1034 Vehicle_Height 65535;
BA_ "GenSigStartValue" SG_ 1034 Vehicle_Width 65535;
BA_ "GenSigInvalidValue" SG_ 1034 Vehicle_Width 65535;
BA_ "GenSigStartValue" SG_ 1034 Vehicle_Length 65535;
BA_ "GenSigInvalidValue" SG_ 1034 Vehicle_Length 65535;
BA_ "GenSigStartValue" SG_ 1034 Reserved_62_2 3;
BA_ "GenSigInvalidValue" SG_ 1034 Reserved_62_2 3;
BA_ "GenSigStartValue" SG_ 1034 TOUCH_PANEL 3;
BA_ "GenSigInvalidValue" SG_ 1034 TOUCH_PANEL 3;
BA_ "GenSigStartValue" SG_ 1034 DISPLAY_SIZE 15;
BA_ "GenSigInvalidValue" SG_ 1034 DISPLAY_SIZE 15;
BA_ "GenSigStartValue" SG_ 1034 HD_Radio 3;
BA_ "GenSigInvalidValue" SG_ 1034 HD_Radio 3;
BA_ "GenSigStartValue" SG_ 1034 TELEMATICS_COM_UNIT 3;
BA_ "GenSigInvalidValue" SG_ 1034 TELEMATICS_COM_UNIT 3;
BA_ "GenSigStartValue" SG_ 1034 B_CALL 255;
BA_ "GenSigInvalidValue" SG_ 1034 B_CALL 255;
BA_ "GenSigStartValue" SG_ 1034 CMU_Spec 15;
BA_ "GenSigInvalidValue" SG_ 1034 CMU_Spec 15;
BA_ "GenSigStartValue" SG_ 1034 Number_Of_Seat_Rows 3;
BA_ "GenSigInvalidValue" SG_ 1034 Number_Of_Seat_Rows 3;
BA_ "GenSigStartValue" SG_ 1034 Tuner_AM_Range 3;
BA_ "GenSigInvalidValue" SG_ 1034 Tuner_AM_Range 3;
BA_ "GenSigStartValue" SG_ 1034 Pandora 3;
BA_ "GenSigInvalidValue" SG_ 1034 Pandora 3;
BA_ "GenSigStartValue" SG_ 1034 Mobile_911 3;
BA_ "GenSigInvalidValue" SG_ 1034 Mobile_911 3;
BA_ "GenSigStartValue" SG_ 1034 HDMI 3;
BA_ "GenSigInvalidValue" SG_ 1034 HDMI 3;
BA_ "GenSigStartValue" SG_ 1034 LW 3;
BA_ "GenSigInvalidValue" SG_ 1034 LW 3;
BA_ "GenSigStartValue" SG_ 1034 Limit_Of_DAB_Range 15;
BA_ "GenSigInvalidValue" SG_ 1034 Limit_Of_DAB_Range 15;
BA_ "GenSigStartValue" SG_ 1034 ELK_CUSTOMIZE_TYPE 3;
BA_ "GenSigInvalidValue" SG_ 1034 ELK_CUSTOMIZE_TYPE 3;
BA_ "GenSigStartValue" SG_ 1034 Microphone 3;
BA_ "GenSigInvalidValue" SG_ 1034 Microphone 3;
BA_ "GenSigStartValue" SG_ 1034 DAA_Default 3;
BA_ "GenSigInvalidValue" SG_ 1034 DAA_Default 3;
BA_ "GenSigStartValue" SG_ 1034 Carplay 3;
BA_ "GenSigInvalidValue" SG_ 1034 Carplay 3;
BA_ "GenSigStartValue" SG_ 1034 Android_Auto 3;
BA_ "GenSigInvalidValue" SG_ 1034 Android_Auto 3;
BA_ "GenSigStartValue" SG_ 1034 Wi_Fi_Frequency 3;
BA_ "GenSigInvalidValue" SG_ 1034 Wi_Fi_Frequency 3;
BA_ "GenSigStartValue" SG_ 1034 Commander_Touchpad 3;
BA_ "GenSigInvalidValue" SG_ 1034 Commander_Touchpad 3;
BA_ "GenSigStartValue" SG_ 1034 TPEG 3;
BA_ "GenSigInvalidValue" SG_ 1034 TPEG 3;
BA_ "GenSigStartValue" SG_ 1034 Reserved_60_1 255;
BA_ "GenSigInvalidValue" SG_ 1034 Reserved_60_1 255;
BA_ "GenSigStartValue" SG_ 1034 SIGN_DISPLAY 15;
BA_ "GenSigInvalidValue" SG_ 1034 SIGN_DISPLAY 15;
BA_ "GenSigStartValue" SG_ 1034 UI_RESTRICTION 15;
BA_ "GenSigInvalidValue" SG_ 1034 UI_RESTRICTION 15;
BA_ "GenSigStartValue" SG_ 1034 ADAS_MAP_SYSTEM 15;
BA_ "GenSigInvalidValue" SG_ 1034 ADAS_MAP_SYSTEM 15;
BA_ "GenSigStartValue" SG_ 1034 RDS_SPEC 15;
BA_ "GenSigInvalidValue" SG_ 1034 RDS_SPEC 15;
BA_ "GenSigStartValue" SG_ 1034 EMERGENCY_CALL 15;
BA_ "GenSigInvalidValue" SG_ 1034 EMERGENCY_CALL 15;
BA_ "GenSigStartValue" SG_ 1034 SATELITE_SPEC 15;
BA_ "GenSigInvalidValue" SG_ 1034 SATELITE_SPEC 15;
BA_ "GenSigStartValue" SG_ 1034 NAVI_MAP_DATA 15;
BA_ "GenSigInvalidValue" SG_ 1034 NAVI_MAP_DATA 15;
BA_ "GenSigStartValue" SG_ 1034 CD_Ripping 3;
BA_ "GenSigInvalidValue" SG_ 1034 CD_Ripping 3;
BA_ "GenSigStartValue" SG_ 1034 TV_TUNER 3;
BA_ "GenSigInvalidValue" SG_ 1034 TV_TUNER 3;
BA_ "GenSigStartValue" SG_ 1034 SPEAKER_TYPE 15;
BA_ "GenSigInvalidValue" SG_ 1034 SPEAKER_TYPE 15;
BA_ "GenSigStartValue" SG_ 1034 DVD 3;
BA_ "GenSigInvalidValue" SG_ 1034 DVD 3;
BA_ "GenSigStartValue" SG_ 1034 CD 3;
BA_ "GenSigInvalidValue" SG_ 1034 CD 3;
BA_ "GenSigStartValue" SG_ 1034 FREQUENCY 15;
BA_ "GenSigInvalidValue" SG_ 1034 FREQUENCY 15;
BA_ "GenSigStartValue" SG_ 1034 RDS 3;
BA_ "GenSigInvalidValue" SG_ 1034 RDS 3;
BA_ "GenSigStartValue" SG_ 1034 DAB 3;
BA_ "GenSigInvalidValue" SG_ 1034 DAB 3;
BA_ "GenSigStartValue" SG_ 1034 Reserved_52_6 255;
BA_ "GenSigInvalidValue" SG_ 1034 Reserved_52_6 255;
BA_ "GenSigStartValue" SG_ 1034 AT_SHIFT_SW 15;
BA_ "GenSigInvalidValue" SG_ 1034 AT_SHIFT_SW 15;
BA_ "GenSigStartValue" SG_ 1034 ELECTRIC_SHIFT 15;
BA_ "GenSigInvalidValue" SG_ 1034 ELECTRIC_SHIFT 15;
BA_ "GenSigStartValue" SG_ 1034 Reserved_52_5 3;
BA_ "GenSigInvalidValue" SG_ 1034 Reserved_52_5 3;
BA_ "GenSigStartValue" SG_ 1034 STG_WHEEL_WARMER 3;
BA_ "GenSigInvalidValue" SG_ 1034 STG_WHEEL_WARMER 3;
BA_ "GenSigStartValue" SG_ 1034 TILT_STG 15;
BA_ "GenSigInvalidValue" SG_ 1034 TILT_STG 15;
BA_ "GenSigStartValue" SG_ 1034 Reserved_52_4 255;
BA_ "GenSigInvalidValue" SG_ 1034 Reserved_52_4 255;
BA_ "GenSigStartValue" SG_ 1034 DRIVE_SELECTION_MODE 15;
BA_ "GenSigInvalidValue" SG_ 1034 DRIVE_SELECTION_MODE 15;
BA_ "GenSigStartValue" SG_ 1034 Reserved_52_3 3;
BA_ "GenSigInvalidValue" SG_ 1034 Reserved_52_3 3;
BA_ "GenSigStartValue" SG_ 1034 DRIVE_SELECTION 3;
BA_ "GenSigInvalidValue" SG_ 1034 DRIVE_SELECTION 3;
BA_ "GenSigStartValue" SG_ 1034 I_DM 3;
BA_ "GenSigInvalidValue" SG_ 1034 I_DM 3;
BA_ "GenSigStartValue" SG_ 1034 Reserved_52_2 3;
BA_ "GenSigInvalidValue" SG_ 1034 Reserved_52_2 3;
BA_ "GenSigStartValue" SG_ 1034 OVER_HEAD_CONSOLE 15;
BA_ "GenSigInvalidValue" SG_ 1034 OVER_HEAD_CONSOLE 15;
BA_ "GenSigStartValue" SG_ 1034 AT_INTERLOCK_UNLOCK_SYS 15;
BA_ "GenSigInvalidValue" SG_ 1034 AT_INTERLOCK_UNLOCK_SYS 15;
BA_ "GenSigStartValue" SG_ 1034 BURGLAR_ALARM_SYSTEM 15;
BA_ "GenSigInvalidValue" SG_ 1034 BURGLAR_ALARM_SYSTEM 15;
BA_ "GenSigStartValue" SG_ 1034 Reserved_50_3 16777215;
BA_ "GenSigInvalidValue" SG_ 1034 Reserved_50_3 16777215;
BA_ "GenSigStartValue" SG_ 1034 TSR_GSR_TYPE 15;
BA_ "GenSigInvalidValue" SG_ 1034 TSR_GSR_TYPE 15;
BA_ "GenSigStartValue" SG_ 1034 SPEED_METER 15;
BA_ "GenSigInvalidValue" SG_ 1034 SPEED_METER 15;
BA_ "GenSigStartValue" SG_ 1034 FUEL_CONSUMPTION_UNIT 15;
BA_ "GenSigInvalidValue" SG_ 1034 FUEL_CONSUMPTION_UNIT 15;
BA_ "GenSigStartValue" SG_ 1034 TRIP_COMPUTER 15;
BA_ "GenSigInvalidValue" SG_ 1034 TRIP_COMPUTER 15;
BA_ "GenSigStartValue" SG_ 1034 HEAD_UP_DISPLAY 3;
BA_ "GenSigInvalidValue" SG_ 1034 HEAD_UP_DISPLAY 3;
BA_ "GenSigStartValue" SG_ 1034 WARNING_BUZZER_120KMH 3;
BA_ "GenSigInvalidValue" SG_ 1034 WARNING_BUZZER_120KMH 3;
BA_ "GenSigStartValue" SG_ 1034 TURN_SIGNAL_SWITCH 3;
BA_ "GenSigInvalidValue" SG_ 1034 TURN_SIGNAL_SWITCH 3;
BA_ "GenSigStartValue" SG_ 1034 Reserved_50_1 3;
BA_ "GenSigInvalidValue" SG_ 1034 Reserved_50_1 3;
BA_ "GenSigStartValue" SG_ 1034 MULTI_DOT_DISPLAY 3;
BA_ "GenSigInvalidValue" SG_ 1034 MULTI_DOT_DISPLAY 3;
BA_ "GenSigStartValue" SG_ 1034 Reserved_50_4 3;
BA_ "GenSigInvalidValue" SG_ 1034 Reserved_50_4 3;
BA_ "GenSigStartValue" SG_ 1034 IND_STD_OF_SPEED_METER 15;
BA_ "GenSigInvalidValue" SG_ 1034 IND_STD_OF_SPEED_METER 15;
BA_ "GenSigStartValue" SG_ 1034 F_EX_MIRROR_AUTO_FOLD 3;
BA_ "GenSigInvalidValue" SG_ 1034 F_EX_MIRROR_AUTO_FOLD 3;
BA_ "GenSigStartValue" SG_ 1034 F_EXT_MIRROR_ADJ_MEMORY 3;
BA_ "GenSigInvalidValue" SG_ 1034 F_EXT_MIRROR_ADJ_MEMORY 3;
BA_ "GenSigStartValue" SG_ 1034 F_EXT_MIRROR_HEATER 3;
BA_ "GenSigInvalidValue" SG_ 1034 F_EXT_MIRROR_HEATER 3;
BA_ "GenSigStartValue" SG_ 1034 F_EX_MIRROR_POWER_FOLD 3;
BA_ "GenSigInvalidValue" SG_ 1034 F_EX_MIRROR_POWER_FOLD 3;
BA_ "GenSigStartValue" SG_ 1034 Reserved_40_3 65535;
BA_ "GenSigInvalidValue" SG_ 1034 Reserved_40_3 65535;
BA_ "GenSigStartValue" SG_ 1034 R_SEAT_NO1_SEAT_TRACK 15;
BA_ "GenSigInvalidValue" SG_ 1034 R_SEAT_NO1_SEAT_TRACK 15;
BA_ "GenSigStartValue" SG_ 1034 ONE_TOUCH_SYSTEM 15;
BA_ "GenSigInvalidValue" SG_ 1034 ONE_TOUCH_SYSTEM 15;
BA_ "GenSigStartValue" SG_ 1034 R_SEAT_VENTILATION 3;
BA_ "GenSigInvalidValue" SG_ 1034 R_SEAT_VENTILATION 3;
BA_ "GenSigStartValue" SG_ 1034 WASHER_LEVEL_LAMP 3;
BA_ "GenSigInvalidValue" SG_ 1034 WASHER_LEVEL_LAMP 3;
BA_ "GenSigStartValue" SG_ 1034 F_WIPER_INTERMITTENT 15;
BA_ "GenSigInvalidValue" SG_ 1034 F_WIPER_INTERMITTENT 15;
BA_ "GenSigStartValue" SG_ 1034 Reserved_30_6 255;
BA_ "GenSigInvalidValue" SG_ 1034 Reserved_30_6 255;
BA_ "GenSigStartValue" SG_ 1034 AUTO_DOOR_LOCK 15;
BA_ "GenSigInvalidValue" SG_ 1034 AUTO_DOOR_LOCK 15;
BA_ "GenSigStartValue" SG_ 1034 Reserved_30_5 3;
BA_ "GenSigInvalidValue" SG_ 1034 Reserved_30_5 3;
BA_ "GenSigStartValue" SG_ 1034 SUPER_LOCK_SYSTEM 3;
BA_ "GenSigInvalidValue" SG_ 1034 SUPER_LOCK_SYSTEM 3;
BA_ "GenSigStartValue" SG_ 1034 POWER_DOOR_LOCK_SW 15;
BA_ "GenSigInvalidValue" SG_ 1034 POWER_DOOR_LOCK_SW 15;
BA_ "GenSigStartValue" SG_ 1034 POWER_DOOR_LOCK 15;
BA_ "GenSigInvalidValue" SG_ 1034 POWER_DOOR_LOCK 15;
BA_ "GenSigStartValue" SG_ 1034 Reserved_30_4 255;
BA_ "GenSigInvalidValue" SG_ 1034 Reserved_30_4 255;
BA_ "GenSigStartValue" SG_ 1034 Reserved_30_3 63;
BA_ "GenSigInvalidValue" SG_ 1034 Reserved_30_3 63;
BA_ "GenSigStartValue" SG_ 1034 POWER_BACK_DOOR 3;
BA_ "GenSigInvalidValue" SG_ 1034 POWER_BACK_DOOR 3;
BA_ "GenSigStartValue" SG_ 1034 Reserved_30_2 255;
BA_ "GenSigInvalidValue" SG_ 1034 Reserved_30_2 255;
BA_ "GenSigStartValue" SG_ 1034 Reserved_30_1 15;
BA_ "GenSigInvalidValue" SG_ 1034 Reserved_30_1 15;
BA_ "GenSigStartValue" SG_ 1034 TRUNK_LID_OPENER 15;
BA_ "GenSigInvalidValue" SG_ 1034 TRUNK_LID_OPENER 15;
BA_ "GenSigStartValue" SG_ 1034 Reserved_25_4 16777215;
BA_ "GenSigInvalidValue" SG_ 1034 Reserved_25_4 16777215;
BA_ "GenSigStartValue" SG_ 1034 DEFAULT_ONE_TOUCH_TURN 3;
BA_ "GenSigInvalidValue" SG_ 1034 DEFAULT_ONE_TOUCH_TURN 3;
BA_ "GenSigStartValue" SG_ 1034 ESS 3;
BA_ "GenSigInvalidValue" SG_ 1034 ESS 3;
BA_ "GenSigStartValue" SG_ 1034 R_FOG_LAMP 3;
BA_ "GenSigInvalidValue" SG_ 1034 R_FOG_LAMP 3;
BA_ "GenSigStartValue" SG_ 1034 F_FOG_LAMP 3;
BA_ "GenSigInvalidValue" SG_ 1034 F_FOG_LAMP 3;
BA_ "GenSigStartValue" SG_ 1034 Reserved_25_3 15;
BA_ "GenSigInvalidValue" SG_ 1034 Reserved_25_3 15;
BA_ "GenSigStartValue" SG_ 1034 PASSIVE_COLLISION_SIGNAL 15;
BA_ "GenSigInvalidValue" SG_ 1034 PASSIVE_COLLISION_SIGNAL 15;
BA_ "GenSigStartValue" SG_ 1034 F_AND_R_SIDE_MARKER_US 3;
BA_ "GenSigInvalidValue" SG_ 1034 F_AND_R_SIDE_MARKER_US 3;
BA_ "GenSigStartValue" SG_ 1034 AUTO_HEAD_LAMP_ON_OFF 3;
BA_ "GenSigInvalidValue" SG_ 1034 AUTO_HEAD_LAMP_ON_OFF 3;
BA_ "GenSigStartValue" SG_ 1034 RUNNING_LAMP_CUSTOMIZE 15;
BA_ "GenSigInvalidValue" SG_ 1034 RUNNING_LAMP_CUSTOMIZE 15;
BA_ "GenSigStartValue" SG_ 1034 F_COMBI_SIGNATURE_ILLUMI 3;
BA_ "GenSigInvalidValue" SG_ 1034 F_COMBI_SIGNATURE_ILLUMI 3;
BA_ "GenSigStartValue" SG_ 1034 HEAD_LAMP_CLEANER 3;
BA_ "GenSigInvalidValue" SG_ 1034 HEAD_LAMP_CLEANER 3;
BA_ "GenSigStartValue" SG_ 1034 Headlamp_Control 15;
BA_ "GenSigInvalidValue" SG_ 1034 Headlamp_Control 15;
BA_ "GenSigStartValue" SG_ 1034 AC_Refrigerant_Gas 15;
BA_ "GenSigInvalidValue" SG_ 1034 AC_Refrigerant_Gas 15;
BA_ "GenSigStartValue" SG_ 1034 AC_Compressor 15;
BA_ "GenSigInvalidValue" SG_ 1034 AC_Compressor 15;
BA_ "GenSigStartValue" SG_ 1034 Reserved_20_2 15;
BA_ "GenSigInvalidValue" SG_ 1034 Reserved_20_2 15;
BA_ "GenSigStartValue" SG_ 1034 SERVER_REGION 15;
BA_ "GenSigInvalidValue" SG_ 1034 SERVER_REGION 15;
BA_ "GenSigStartValue" SG_ 1034 DEFROSTER_CIRCULATION_CONTROL 15;
BA_ "GenSigInvalidValue" SG_ 1034 DEFROSTER_CIRCULATION_CONTROL 15;
BA_ "GenSigStartValue" SG_ 1034 TEMPERATURE_SETTING_RANGE 15;
BA_ "GenSigInvalidValue" SG_ 1034 TEMPERATURE_SETTING_RANGE 15;
BA_ "GenSigStartValue" SG_ 1034 Reserved_20_1 3;
BA_ "GenSigInvalidValue" SG_ 1034 Reserved_20_1 3;
BA_ "GenSigStartValue" SG_ 1034 PreAirCon_OperatingTime 15;
BA_ "GenSigInvalidValue" SG_ 1034 PreAirCon_OperatingTime 15;
BA_ "GenSigStartValue" SG_ 1034 R_VENT_COOLER 3;
BA_ "GenSigInvalidValue" SG_ 1034 R_VENT_COOLER 3;
BA_ "GenSigStartValue" SG_ 1034 HUMIDITY_SENSOR 3;
BA_ "GenSigInvalidValue" SG_ 1034 HUMIDITY_SENSOR 3;
BA_ "GenSigStartValue" SG_ 1034 PTC_HEATER 3;
BA_ "GenSigInvalidValue" SG_ 1034 PTC_HEATER 3;
BA_ "GenSigStartValue" SG_ 1034 F_AIR_CONDITIONER 15;
BA_ "GenSigInvalidValue" SG_ 1034 F_AIR_CONDITIONER 15;
BA_ "GenSigStartValue" SG_ 1034 Reserved_16_3 16777215;
BA_ "GenSigInvalidValue" SG_ 1034 Reserved_16_3 16777215;
BA_ "GenSigStartValue" SG_ 1034 Reserved_16_2 15;
BA_ "GenSigInvalidValue" SG_ 1034 Reserved_16_2 15;
BA_ "GenSigStartValue" SG_ 1034 OCCUPANT_MONITOR_SYSTEM 3;
BA_ "GenSigInvalidValue" SG_ 1034 OCCUPANT_MONITOR_SYSTEM 3;
BA_ "GenSigStartValue" SG_ 1034 FRONT_SIDE_RADAR 3;
BA_ "GenSigInvalidValue" SG_ 1034 FRONT_SIDE_RADAR 3;
BA_ "GenSigStartValue" SG_ 1034 TJA_TYPE 15;
BA_ "GenSigInvalidValue" SG_ 1034 TJA_TYPE 15;
BA_ "GenSigStartValue" SG_ 1034 VIEW_MONITOR_CAMERA 15;
BA_ "GenSigInvalidValue" SG_ 1034 VIEW_MONITOR_CAMERA 15;
BA_ "GenSigStartValue" SG_ 1034 FRONT_REAR_SIDE_SONAR 15;
BA_ "GenSigInvalidValue" SG_ 1034 FRONT_REAR_SIDE_SONAR 15;
BA_ "GenSigStartValue" SG_ 1034 DRIVER_MONITOR 3;
BA_ "GenSigInvalidValue" SG_ 1034 DRIVER_MONITOR 3;
BA_ "GenSigStartValue" SG_ 1034 FRONT_CROSS_TRAFFIC_ALERT 3;
BA_ "GenSigInvalidValue" SG_ 1034 FRONT_CROSS_TRAFFIC_ALERT 3;
BA_ "GenSigStartValue" SG_ 1034 INTERSECTION_BRAKE_TYPE 15;
BA_ "GenSigInvalidValue" SG_ 1034 INTERSECTION_BRAKE_TYPE 15;
BA_ "GenSigStartValue" SG_ 1034 BLIND_SPOT_PREVENTION 3;
BA_ "GenSigInvalidValue" SG_ 1034 BLIND_SPOT_PREVENTION 3;
BA_ "GenSigStartValue" SG_ 1034 Reserved_16_1 3;
BA_ "GenSigInvalidValue" SG_ 1034 Reserved_16_1 3;
BA_ "GenSigStartValue" SG_ 1034 Reserved_15_3 16777215;
BA_ "GenSigInvalidValue" SG_ 1034 Reserved_15_3 16777215;
BA_ "GenSigStartValue" SG_ 1034 SBS_VRU_TYPE 15;
BA_ "GenSigInvalidValue" SG_ 1034 SBS_VRU_TYPE 15;
BA_ "GenSigStartValue" SG_ 1034 ADAS_REGULATION_TYPE 15;
BA_ "GenSigInvalidValue" SG_ 1034 ADAS_REGULATION_TYPE 15;
BA_ "GenSigStartValue" SG_ 1034 REMOTE_PARKING 3;
BA_ "GenSigInvalidValue" SG_ 1034 REMOTE_PARKING 3;
BA_ "GenSigStartValue" SG_ 1034 AUTO_PARKING 3;
BA_ "GenSigInvalidValue" SG_ 1034 AUTO_PARKING 3;
BA_ "GenSigStartValue" SG_ 1034 ACCELERATION_RESTRAINT 15;
BA_ "GenSigInvalidValue" SG_ 1034 ACCELERATION_RESTRAINT 15;
BA_ "GenSigStartValue" SG_ 1034 REAR_SONAR 15;
BA_ "GenSigInvalidValue" SG_ 1034 REAR_SONAR 15;
BA_ "GenSigStartValue" SG_ 1034 FRONT_SONAR 15;
BA_ "GenSigInvalidValue" SG_ 1034 FRONT_SONAR 15;
BA_ "GenSigStartValue" SG_ 1034 PARKING_SENSOR 15;
BA_ "GenSigInvalidValue" SG_ 1034 PARKING_SENSOR 15;
BA_ "GenSigStartValue" SG_ 1034 REAR_DIRECTION_BASE_SAFETY 15;
BA_ "GenSigInvalidValue" SG_ 1034 REAR_DIRECTION_BASE_SAFETY 15;
BA_ "GenSigStartValue" SG_ 1034 Reserved_14_2 15;
BA_ "GenSigInvalidValue" SG_ 1034 Reserved_14_2 15;
BA_ "GenSigStartValue" SG_ 1034 SBS_TARGET_TYPE 15;
BA_ "GenSigInvalidValue" SG_ 1034 SBS_TARGET_TYPE 15;
BA_ "GenSigStartValue" SG_ 1034 IACC_TYPE 15;
BA_ "GenSigInvalidValue" SG_ 1034 IACC_TYPE 15;
BA_ "GenSigStartValue" SG_ 1034 HEAD_ON 15;
BA_ "GenSigInvalidValue" SG_ 1034 HEAD_ON 15;
BA_ "GenSigStartValue" SG_ 1034 LAS_TYPE 15;
BA_ "GenSigInvalidValue" SG_ 1034 LAS_TYPE 15;
BA_ "GenSigStartValue" SG_ 1034 MRCC_TYPE 15;
BA_ "GenSigInvalidValue" SG_ 1034 MRCC_TYPE 15;
BA_ "GenSigStartValue" SG_ 1034 Reserved_14_1 3;
BA_ "GenSigInvalidValue" SG_ 1034 Reserved_14_1 3;
BA_ "GenSigStartValue" SG_ 1034 BLIND_SPOT_MONITORING 3;
BA_ "GenSigInvalidValue" SG_ 1034 BLIND_SPOT_MONITORING 3;
BA_ "GenSigStartValue" SG_ 1034 REAR_SIDE_RADAR 3;
BA_ "GenSigInvalidValue" SG_ 1034 REAR_SIDE_RADAR 3;
BA_ "GenSigStartValue" SG_ 1034 FRONT_RADAR 3;
BA_ "GenSigInvalidValue" SG_ 1034 FRONT_RADAR 3;
BA_ "GenSigStartValue" SG_ 1034 ADJUSTABLE_SPEED_LIMITER 15;
BA_ "GenSigInvalidValue" SG_ 1034 ADJUSTABLE_SPEED_LIMITER 15;
BA_ "GenSigStartValue" SG_ 1034 AUTO_CRUISER 15;
BA_ "GenSigInvalidValue" SG_ 1034 AUTO_CRUISER 15;
BA_ "GenSigStartValue" SG_ 1034 DAS_TYPE 15;
BA_ "GenSigInvalidValue" SG_ 1034 DAS_TYPE 15;
BA_ "GenSigStartValue" SG_ 1034 DRIVER_ATTENTION_ALERT 3;
BA_ "GenSigInvalidValue" SG_ 1034 DRIVER_ATTENTION_ALERT 3;
BA_ "GenSigStartValue" SG_ 1034 TRAFFIC_SIGN_RECOGNITION 3;
BA_ "GenSigInvalidValue" SG_ 1034 TRAFFIC_SIGN_RECOGNITION 3;
BA_ "GenSigStartValue" SG_ 1034 FRONT_DIRECTION_BASE_SAFETY 15;
BA_ "GenSigInvalidValue" SG_ 1034 FRONT_DIRECTION_BASE_SAFETY 15;
BA_ "GenSigStartValue" SG_ 1034 HIGH_BEAM_CONTROL 3;
BA_ "GenSigInvalidValue" SG_ 1034 HIGH_BEAM_CONTROL 3;
BA_ "GenSigStartValue" SG_ 1034 FORWARD_SENSING_CAMERA 3;
BA_ "GenSigInvalidValue" SG_ 1034 FORWARD_SENSING_CAMERA 3;
BA_ "GenSigStartValue" SG_ 1034 Reserved_13_3 16777215;
BA_ "GenSigInvalidValue" SG_ 1034 Reserved_13_3 16777215;
BA_ "GenSigStartValue" SG_ 1034 Reserved_13_2 255;
BA_ "GenSigInvalidValue" SG_ 1034 Reserved_13_2 255;
BA_ "GenSigStartValue" SG_ 1034 Reserved_13_1 15;
BA_ "GenSigInvalidValue" SG_ 1034 Reserved_13_1 15;
BA_ "GenSigStartValue" SG_ 1034 F_TIRE_SIZE 15;
BA_ "GenSigInvalidValue" SG_ 1034 F_TIRE_SIZE 15;
BA_ "GenSigStartValue" SG_ 1034 EPS_Assist_Map 255;
BA_ "GenSigInvalidValue" SG_ 1034 EPS_Assist_Map 255;
BA_ "GenSigStartValue" SG_ 1034 Booster_Failure_Support 3;
BA_ "GenSigInvalidValue" SG_ 1034 Booster_Failure_Support 3;
BA_ "GenSigStartValue" SG_ 1034 DYC 3;
BA_ "GenSigInvalidValue" SG_ 1034 DYC 3;
BA_ "GenSigStartValue" SG_ 1034 Brake_Pad_Material 15;
BA_ "GenSigInvalidValue" SG_ 1034 Brake_Pad_Material 15;
BA_ "GenSigStartValue" SG_ 1034 Rear_Brake_Size 15;
BA_ "GenSigInvalidValue" SG_ 1034 Rear_Brake_Size 15;
BA_ "GenSigStartValue" SG_ 1034 Front_Brake_Size 15;
BA_ "GenSigInvalidValue" SG_ 1034 Front_Brake_Size 15;
BA_ "GenSigStartValue" SG_ 1034 NVH_SPEC 15;
BA_ "GenSigInvalidValue" SG_ 1034 NVH_SPEC 15;
BA_ "GenSigStartValue" SG_ 1034 TIRE_PRESSURE_MONITOR_S 15;
BA_ "GenSigInvalidValue" SG_ 1034 TIRE_PRESSURE_MONITOR_S 15;
BA_ "GenSigStartValue" SG_ 1034 BATTERY_HEATER 15;
BA_ "GenSigInvalidValue" SG_ 1034 BATTERY_HEATER 15;
BA_ "GenSigStartValue" SG_ 1034 Reserved_11_1 3;
BA_ "GenSigInvalidValue" SG_ 1034 Reserved_11_1 3;
BA_ "GenSigStartValue" SG_ 1034 TSA 3;
BA_ "GenSigInvalidValue" SG_ 1034 TSA 3;
BA_ "GenSigStartValue" SG_ 1034 AUTO_HOLD 3;
BA_ "GenSigInvalidValue" SG_ 1034 AUTO_HOLD 3;
BA_ "GenSigStartValue" SG_ 1034 EPB 3;
BA_ "GenSigInvalidValue" SG_ 1034 EPB 3;
BA_ "GenSigStartValue" SG_ 1034 Brake_Control 15;
BA_ "GenSigInvalidValue" SG_ 1034 Brake_Control 15;
BA_ "GenSigStartValue" SG_ 1034 Reserved_10_2 65535;
BA_ "GenSigInvalidValue" SG_ 1034 Reserved_10_2 65535;
BA_ "GenSigStartValue" SG_ 1034 OBD_CONFIG_INFORMATION 15;
BA_ "GenSigInvalidValue" SG_ 1034 OBD_CONFIG_INFORMATION 15;
BA_ "GenSigStartValue" SG_ 1034 CLOSED_FUEL_TANK_SYSTEM 15;
BA_ "GenSigInvalidValue" SG_ 1034 CLOSED_FUEL_TANK_SYSTEM 15;
BA_ "GenSigStartValue" SG_ 1034 BEV_MAINTENANCE_LIMIT 255;
BA_ "GenSigInvalidValue" SG_ 1034 BEV_MAINTENANCE_LIMIT 255;
BA_ "GenSigStartValue" SG_ 1034 Reserved_10_1 4095;
BA_ "GenSigInvalidValue" SG_ 1034 Reserved_10_1 4095;
BA_ "GenSigStartValue" SG_ 1034 E_OIL_MAINTENANCE_LIMIT 15;
BA_ "GenSigInvalidValue" SG_ 1034 E_OIL_MAINTENANCE_LIMIT 15;
BA_ "GenSigStartValue" SG_ 1034 REGENERATION_TYPE 15;
BA_ "GenSigInvalidValue" SG_ 1034 REGENERATION_TYPE 15;
BA_ "GenSigStartValue" SG_ 1034 I_STOP_TYPE 15;
BA_ "GenSigInvalidValue" SG_ 1034 I_STOP_TYPE 15;
BA_ "GenSigStartValue" SG_ 1034 DEVELOPMENT_FUEL 15;
BA_ "GenSigInvalidValue" SG_ 1034 DEVELOPMENT_FUEL 15;
BA_ "GenSigStartValue" SG_ 1034 PLANT 15;
BA_ "GenSigInvalidValue" SG_ 1034 PLANT 15;
BA_ "GenSigStartValue" SG_ 1034 Reserved_06_1 3;
BA_ "GenSigInvalidValue" SG_ 1034 Reserved_06_1 3;
BA_ "GenSigStartValue" SG_ 1034 Steering_Position 3;
BA_ "GenSigInvalidValue" SG_ 1034 Steering_Position 3;
BA_ "GenSigStartValue" SG_ 1034 ROOF 15;
BA_ "GenSigInvalidValue" SG_ 1034 ROOF 15;
BA_ "GenSigStartValue" SG_ 1034 TRANSMISSION 3;
BA_ "GenSigInvalidValue" SG_ 1034 TRANSMISSION 3;
BA_ "GenSigStartValue" SG_ 1034 DRIVE 3;
BA_ "GenSigInvalidValue" SG_ 1034 DRIVE 3;
BA_ "GenSigStartValue" SG_ 1034 ENGINE 15;
BA_ "GenSigInvalidValue" SG_ 1034 ENGINE 15;
BA_ "GenSigStartValue" SG_ 1034 BODY 15;
BA_ "GenSigInvalidValue" SG_ 1034 BODY 15;
BA_ "GenSigStartValue" SG_ 1034 BRAND 15;
BA_ "GenSigInvalidValue" SG_ 1034 BRAND 15;
BA_ "GenSigStartValue" SG_ 1034 MARKET 255;
BA_ "GenSigInvalidValue" SG_ 1034 MARKET 255;
BA_ "GenSigStartValue" SG_ 1034 Reserved_05_1 16777215;
BA_ "GenSigInvalidValue" SG_ 1034 Reserved_05_1 16777215;
BA_ "GenSigStartValue" SG_ 1034 Project_Code_4th 255;
BA_ "GenSigInvalidValue" SG_ 1034 Project_Code_4th 255;
BA_ "GenSigStartValue" SG_ 1034 Project_Code_3rd 255;
BA_ "GenSigInvalidValue" SG_ 1034 Project_Code_3rd 255;
BA_ "GenSigStartValue" SG_ 1034 Project_Code_2nd 255;
BA_ "GenSigInvalidValue" SG_ 1034 Project_Code_2nd 255;
BA_ "GenSigStartValue" SG_ 1034 Project_Code_1st 255;
BA_ "GenSigInvalidValue" SG_ 1034 Project_Code_1st 255;
BA_ "GenSigStartValue" SG_ 1034 Outer_Color_3 255;
BA_ "GenSigInvalidValue" SG_ 1034 Outer_Color_3 255;
BA_ "GenSigStartValue" SG_ 1034 Outer_Color_2 255;
BA_ "GenSigInvalidValue" SG_ 1034 Outer_Color_2 255;
BA_ "GenSigStartValue" SG_ 1034 Outer_Color_1 255;
BA_ "GenSigInvalidValue" SG_ 1034 Outer_Color_1 255;
BA_ "GenSigStartValue" SG_ 1034 Unit_Serial_Number 255;
BA_ "GenSigInvalidValue" SG_ 1034 Unit_Serial_Number 255;
BA_ "GenSigStartValue" SG_ 1034 Unit_Destination 255;
BA_ "GenSigInvalidValue" SG_ 1034 Unit_Destination 255;
BA_ "GenSigStartValue" SG_ 1034 Unit_Series 255;
BA_ "GenSigInvalidValue" SG_ 1034 Unit_Series 255;
BA_ "GenSigStartValue" SG_ 1034 Unit_Car_Line 255;
BA_ "GenSigInvalidValue" SG_ 1034 Unit_Car_Line 255;
BA_ "GenSigStartValue" SG_ 1034 VIN_Character_21 255;
BA_ "GenSigInvalidValue" SG_ 1034 VIN_Character_21 255;
BA_ "GenSigStartValue" SG_ 1034 VIN_Character_20 255;
BA_ "GenSigInvalidValue" SG_ 1034 VIN_Character_20 255;
BA_ "GenSigStartValue" SG_ 1034 VIN_Character_19 255;
BA_ "GenSigInvalidValue" SG_ 1034 VIN_Character_19 255;
BA_ "GenSigStartValue" SG_ 1034 VIN_Character_18 255;
BA_ "GenSigInvalidValue" SG_ 1034 VIN_Character_18 255;
BA_ "GenSigStartValue" SG_ 1034 VIN_Character_17 255;
BA_ "GenSigInvalidValue" SG_ 1034 VIN_Character_17 255;
BA_ "GenSigStartValue" SG_ 1034 VIN_Character_16 255;
BA_ "GenSigInvalidValue" SG_ 1034 VIN_Character_16 255;
BA_ "GenSigStartValue" SG_ 1034 VIN_Character_15 255;
BA_ "GenSigInvalidValue" SG_ 1034 VIN_Character_15 255;
BA_ "GenSigStartValue" SG_ 1034 VIN_Character_14 255;
BA_ "GenSigInvalidValue" SG_ 1034 VIN_Character_14 255;
BA_ "GenSigStartValue" SG_ 1034 VIN_Character_13 255;
BA_ "GenSigInvalidValue" SG_ 1034 VIN_Character_13 255;
BA_ "GenSigStartValue" SG_ 1034 VIN_Character_12 255;
BA_ "GenSigInvalidValue" SG_ 1034 VIN_Character_12 255;
BA_ "GenSigStartValue" SG_ 1034 VIN_Character_11 255;
BA_ "GenSigInvalidValue" SG_ 1034 VIN_Character_11 255;
BA_ "GenSigStartValue" SG_ 1034 VIN_Character_10 255;
BA_ "GenSigInvalidValue" SG_ 1034 VIN_Character_10 255;
BA_ "GenSigStartValue" SG_ 1034 VIN_Character_09 255;
BA_ "GenSigInvalidValue" SG_ 1034 VIN_Character_09 255;
BA_ "GenSigStartValue" SG_ 1034 VIN_Character_08 255;
BA_ "GenSigInvalidValue" SG_ 1034 VIN_Character_08 255;
BA_ "GenSigStartValue" SG_ 1034 VIN_Character_07 255;
BA_ "GenSigInvalidValue" SG_ 1034 VIN_Character_07 255;
BA_ "GenSigStartValue" SG_ 1034 VIN_Character_06 255;
BA_ "GenSigInvalidValue" SG_ 1034 VIN_Character_06 255;
BA_ "GenSigStartValue" SG_ 1034 VIN_Character_05 255;
BA_ "GenSigInvalidValue" SG_ 1034 VIN_Character_05 255;
BA_ "GenSigStartValue" SG_ 1034 VIN_Character_04 255;
BA_ "GenSigInvalidValue" SG_ 1034 VIN_Character_04 255;
BA_ "GenSigStartValue" SG_ 1034 VIN_Character_03 255;
BA_ "GenSigInvalidValue" SG_ 1034 VIN_Character_03 255;
BA_ "GenSigStartValue" SG_ 1034 VIN_Character_02 255;
BA_ "GenSigInvalidValue" SG_ 1034 VIN_Character_02 255;
BA_ "GenSigStartValue" SG_ 1034 VIN_Character_01 255;
BA_ "GenSigInvalidValue" SG_ 1034 VIN_Character_01 255;
BA_ "GenSigSendType" SG_ 1032 ACCMMOD 3;
BA_ "GenSigSendType" SG_ 1032 ACCMAPP 3;
VAL_ 1103 PDA_disp_forward_vehicle 0 "no target" 1 "forward_vehicle" ;
VAL_ 1103 PDA_disp_traffic 0 "no target" 1 "traffic" ;
VAL_ 1103 PDA_disp_curve 0 "no target" 1 "curve" ;
VAL_ 1103 PDA_state 0 "not adopted" 1 "off" 2 "inactive" 3 "active" 4 "control" 5 "notification" 6 "reserved" 7 "reserved" 8 "reserved" 9 "reserved" 10 "reserved" 11 "reserved" 12 "towing off" 13 "temporary failure" 14 "initialization" 15 "failure" ;
VAL_ 1103 ISA_fallback 0 "normal range" 1 "fallback" 2 "fallback2" ;
VAL_ 1103 ISA_overspeed 0 "normal" 1 "over speed1" 2 "over speed2" ;
VAL_ 1103 ISA_state 0 "not adopted" 1 "off" 2 "inactive" 3 "active" 4 "control" 5 "notification" 6 "kickdown(override)" 7 "reserved" 8 "reserved" 9 "reserved" 10 "reserved" 11 "reserved" 12 "towing off" 13 "temporary failure" 14 "initialization" 15 "failure" ;
VAL_ 1103 ISA_EV_kickdown 0 "no event" 1 "event occurrence" ;
VAL_ 1103 ISA_sign 0 "no sign" 1 "sign" 2 "offer_sign" 3 "offer_sign_next" ;
VAL_ 1103 ASC_state 0 "not adopted" 1 "off" 2 "inactive" 3 "active" 4 "control" 5 "notification" 6 "override" 7 "reserved" 8 "reserved" 9 "reserved" 10 "reserved" 11 "reserved" 12 "towing off" 13 "temporary failure" 14 "initialization" 15 "failure" ;
VAL_ 1103 ACC_EV_override 0 "no event" 1 "event occurrence" ;
VAL_ 1103 ACC_EV_offer_sign 0 "no event" 1 "event occurrence" ;
VAL_ 1103 ACC_EV_mode_change_reject 0 "no event" 1 "event occurrence" ;
VAL_ 1103 ACC_EV_mode_change_accept 0 "no event" 1 "event occurrence" ;
VAL_ 1103 ACC_EV_set_dist 0 "no event" 1 "event occurrence" ;
VAL_ 1103 ACC_set_distance 0 "off" 1 "Distance 1" 2 "Distance 2" 3 "Distance 3" 4 "Distance 4" ;
VAL_ 1103 ACC_sign 0 "no sign" 1 "sign" 2 "offer sign" 3 "offer sign next" 4 "sign auto" 5 "notice sign" 6 "notice sign next" ;
VAL_ 1103 ACC_stop 0 "not stop" 1 "stop" ;
VAL_ 1103 ACC_target_decel 0 "no target" 1 "curve" 2 "intersection" 3 "toll gate" 4 "stop sign" 5 "vehicle stopped on the roadside" 6 "T-intersection" 7 "roundabout" 8 "left side lane vehicle(EU)" ;
VAL_ 1103 ACC_state 0 "not adopted" 1 "off" 2 "inactive" 3 "active" 4 "control" 5 "notification" 6 "override" 7 "reserved" 8 "reserved" 9 "reserved" 10 "reserved" 11 "reserved" 12 "towing off" 13 "temporary failure" 14 "initialization" 15 "failure" ;
VAL_ 1103 ACC_target 0 "none" 1 "vehicle" 2 "truck" 3 "bike" 4 "pedestrian$03:reserved" ;
VAL_ 1103 AD_state 0 "off" 1 "acc" 2 "tja" 3 "asc" 4 "isa" 5 "hof" 6 "reserved" 7 "reserved" 8 "reserved" ;
VAL_ 1103 OCP_opp_lh 0 "none" 1 "Detect" 2 "Warn" 3 "none" ;
VAL_ 1103 OCP_opp_rh 0 "none" 1 "Detect" 2 "Warn" 3 "none" ;
VAL_ 1103 OCP_lane_lh 0 "none" 1 "Detect" 2 "Warn" 3 "none" ;
VAL_ 1103 OCP_lane_rh 0 "none" 1 "Detect" 2 "Warn" 3 "none" ;
VAL_ 1103 OCP_state 0 "not adopted" 1 "off" 2 "inactive" 3 "active" 4 "control" 5 "notification" 6 "reserved" 7 "reserved" 8 "reserved" 9 "reserved" 10 "reserved" 11 "reserved" 12 "towing off" 13 "temporary failure" 14 "initialization" 15 "failure" ;
VAL_ 1103 CBDA_target_lh 0 "none" 1 "Detect" 2 "Warn" 3 "none" ;
VAL_ 1103 CBDA_target_rh 0 "none" 1 "Detect" 2 "Warn" 3 "none" ;
VAL_ 1103 CBDA_state 0 "not adopted" 1 "off" 2 "inactive" 3 "active" 4 "control" 5 "notification" 6 "reserved" 7 "reserved" 8 "reserved" 9 "reserved" 10 "reserved" 11 "reserved" 12 "towing off" 13 "temporary failure" 14 "initialization" 15 "failure" ;
VAL_ 1103 BSM_target_lh 0 "none" 1 "Detect" 2 "Warn" 3 "none" ;
VAL_ 1103 BSM_target_rh 0 "none" 1 "Detect" 2 "Warn" 3 "none" ;
VAL_ 1103 BSM_state 0 "not adopted" 1 "off" 2 "inactive" 3 "active" 4 "control" 5 "notification" 6 "reserved" 7 "reserved" 8 "reserved" 9 "reserved" 10 "reserved" 11 "reserved" 12 "towing off" 13 "temporary failure" 14 "initialization" 15 "failure" ;
VAL_ 1103 FCTA_target_lh 0 "none" 1 "Detect" 2 "Warn" 3 "none" ;
VAL_ 1103 FCTA_target_rh 0 "none" 1 "Detect" 2 "Warn" 3 "none" ;
VAL_ 1103 FCTA_state 0 "not adopted" 1 "off" 2 "inactive" 3 "active" 4 "control" 5 "notification" 6 "reserved" 7 "reserved" 8 "reserved" 9 "reserved" 10 "reserved" 11 "reserved" 12 "towing off" 13 "temporary failure" 14 "initialization" 15 "failure" ;
VAL_ 1103 BSP_target_lh 0 "none" 1 "Detect" 2 "Warn" 3 "none" ;
VAL_ 1103 BSP_target_rh 0 "none" 1 "Detect" 2 "Warn" 3 "none" ;
VAL_ 1103 BSP_lane_lh 0 "none" 1 "Detect" 2 "Warn" 3 "none" ;
VAL_ 1103 BSP_lane_rh 0 "none" 1 "Detect" 2 "Warn" 3 "none" ;
VAL_ 1103 BSP_state 0 "not adopted" 1 "off" 2 "inactive" 3 "active" 4 "control" 5 "notification" 6 "reserved" 7 "reserved" 8 "reserved" 9 "reserved" 10 "reserved" 11 "reserved" 12 "towing off" 13 "temporary failure" 14 "initialization" 15 "failure" ;
VAL_ 1103 RDP_roadedge_lh 0 "none" 1 "Detect" 2 "Warn" 3 "none" ;
VAL_ 1103 RDP_roadedge_rh 0 "none" 1 "Detect" 2 "Warn" 3 "none" ;
VAL_ 1103 RDP_state 0 "not adopted" 1 "off" 2 "inactive" 3 "active" 4 "control" 5 "notification" 6 "reserved" 7 "reserved" 8 "reserved" 9 "reserved" 10 "reserved" 11 "reserved" 12 "towing off" 13 "temporary failure" 14 "initialization" 15 "failure" ;
VAL_ 1103 LDW_lane_lh 0 "none" 1 "Detect" 2 "Warn" 3 "none" ;
VAL_ 1103 LDW_lane_rh 0 "none" 1 "Detect" 2 "Warn" 3 "none" ;
VAL_ 1103 LDW_state 0 "not adopted" 1 "off" 2 "inactive" 3 "active" 4 "control" 5 "notification" 6 "reserved" 7 "reserved" 8 "reserved" 9 "reserved" 10 "reserved" 11 "reserved" 12 "towing off" 13 "temporary failure" 14 "initialization" 15 "failure" ;
VAL_ 1103 LDP_lane_lh 0 "none" 1 "Detect" 2 "Warn" 3 "none" ;
VAL_ 1103 LDP_lane_rh 0 "none" 1 "Detect" 2 "Warn" 3 "none" ;
VAL_ 1103 LDP_state 0 "not adopted" 1 "off" 2 "inactive" 3 "active" 4 "control" 5 "notification" 6 "reserved" 7 "reserved" 8 "reserved" 9 "reserved" 10 "reserved" 11 "reserved" 12 "towing off" 13 "temporary failure" 14 "initialization" 15 "failure" ;
VAL_ 1103 AES_state 0 "not adopted" 1 "off" 2 "inactive" 3 "active" 4 "control" 5 "notification" 6 "reserved" 7 "reserved" 8 "reserved" 9 "reserved" 10 "reserved" 11 "reserved" 12 "towing off" 13 "temporary failure" 14 "initialization" 15 "failure" ;
VAL_ 1103 RCTB_state 0 "not adopted" 1 "off" 2 "inactive" 3 "active" 4 "control" 5 "notification" 6 "reserved" 7 "reserved" 8 "reserved" 9 "reserved" 10 "reserved" 11 "reserved" 12 "towing off" 13 "temporary failure" 14 "initialization" 15 "failure" ;
VAL_ 1103 RCTA_target_lh 0 "none" 1 "Detect" 2 "Warn" 3 "none" ;
VAL_ 1103 RCTA_target_rh 0 "none" 1 "Detect" 2 "Warn" 3 "none" ;
VAL_ 1103 RCTA_state 0 "not adopted" 1 "off" 2 "inactive" 3 "active" 4 "control" 5 "notification" 6 "reserved" 7 "reserved" 8 "reserved" 9 "reserved" 10 "reserved" 11 "reserved" 12 "towing off" 13 "temporary failure" 14 "initialization" 15 "failure" ;
VAL_ 1103 RPTC_state 0 "not adopted" 1 "off" 2 "inactive" 3 "active" 4 "control" 5 "notification" 6 "reserved" 7 "reserved" 8 "reserved" 9 "reserved" 10 "reserved" 11 "reserved" 12 "towing off" 13 "temporary failure" 14 "initialization" 15 "failure" ;
VAL_ 1103 PAEB_state 0 "not adopted" 1 "off" 2 "inactive" 3 "active" 4 "control" 5 "notification" 6 "reserved" 7 "reserved" 8 "reserved" 9 "reserved" 10 "reserved" 11 "reserved" 12 "towing off" 13 "temporary failure" 14 "initialization" 15 "failure" ;
VAL_ 1103 CTB_target_lh 0 "none" 1 "Detect" 2 "Warn" 3 "none" ;
VAL_ 1103 CTB_target_rh 0 "none" 1 "Detect" 2 "Warn" 3 "none" ;
VAL_ 1103 CTB_state 0 "not adopted" 1 "off" 2 "inactive" 3 "active" 4 "control" 5 "notification" 6 "reserved" 7 "reserved" 8 "reserved" 9 "reserved" 10 "reserved" 11 "reserved" 12 "towing off" 13 "temporary failure" 14 "initialization" 15 "failure" ;
VAL_ 1103 PTC_state 0 "not adopted" 1 "off" 2 "inactive" 3 "active" 4 "control" 5 "notification" 6 "reserved" 7 "reserved" 8 "reserved" 9 "reserved" 10 "reserved" 11 "reserved" 12 "towing off" 13 "temporary failure" 14 "initialization" 15 "failure" ;
VAL_ 1103 SBS_IND_state 0 "Off" 1 "On" ;
VAL_ 1103 AEB_state 0 "not adopted" 1 "off" 2 "inactive" 3 "active" 4 "control" 5 "notification" 6 "reserved" 7 "reserved" 8 "reserved" 9 "reserved" 10 "reserved" 11 "reserved" 12 "towing off" 13 "temporary failure" 14 "initialization" 15 "failure" ;
VAL_ 1100 LMkrRReli_FSC1_01 0 "Not detected" 1 "False detection:over 50%" 2 "False detection:10 - 50%" 3 "False detection:5 - 10%" 4 "False detection:1 - 5%" 5 "False detection:under 1%" 6 "Reserved" 7 "Invalid value" ;
VAL_ 1100 LMkrLReli_FSC1_01 0 "Not detected" 1 "False detection:over 50%" 2 "False detection:10 - 50%" 3 "False detection:5 - 10%" 4 "False detection:1 - 5%" 5 "False detection:under 1%" 6 "Reserved" 7 "Invalid value" ;
VAL_ 1090 MirrorLED2_status 0 "Normal" 1 "Abnormal" ;
VAL_ 1090 DrLock_Message_P_Rsp 0 "Unknown" 1 "NG" 2 "OK" ;
VAL_ 1090 PsgDLMotorDriveStat 0 "Not Drive" 1 "All LockDrive" 2 "All SuperLockDrive" 3 "All UnLockDrive" 4 "Reserve" 5 "Return All LockDrive" 6 "Reserve" 7 "Reserve" ;
VAL_ 1090 Ctrl_DLSw_Psg_Stat 0 "Neutral" 1 "Lock" 2 "Unlock" ;
VAL_ 1090 DrivingPositionStatus 0 "OFF" 1 "Completed" 2 "Reject" 3 "NoNeed" ;
VAL_ 1090 LockLinkSwPsngr_D_Actl 0 "Lock" 1 "Unlock" ;
VAL_ 1090 DrStatPsngr_D_Qf 0 "Faulty" 1 "Undefined" 2 "Not within specification" 3 "OK" ;
VAL_ 1090 DrStatPsngr_B_Actl 0 "Door Closed" 1 "Door Ajar" ;
VAL_ 1088 Move_AutoDposMirror_Res 0 "No Action" 1 "AutoDpos Complete" 2 "AutoDpos Reject" 3 "(Reserve)" ;
VAL_ 1088 MirrorLED1_status 0 "Normal" 1 "Abnormal" ;
VAL_ 1088 DrLock_Message_D_Rsp 0 "Unknown" 1 "NG" 2 "OK" ;
VAL_ 1088 DrivingPositionRequest 0 "No Action" 1 "Record Request" 2 "Erase Request" 3 "Recall Request" ;
VAL_ 1088 Mirror_AjustSelSW_Status 0 "OFF" 1 "Right ON" 2 "Left ON" 3 "Reserved" ;
VAL_ 1088 MirrorFoldRequest 0 "OFF" 1 "Fold" 2 "Unfold" 3 "Reserved" ;
VAL_ 1088 MirrorAdjustRequest 0 "OFF" 1 "Up" 2 "Down" 3 "Right" 4 "Left" 5 "Reserved" 6 "Reserved" 7 "Reserved" ;
VAL_ 1088 MirrorAdjst_Manual_Status 0 "OFF" 1 "ON" ;
VAL_ 1088 MirrorAdjst_Status 0 "Stop" 1 "Moving" ;
VAL_ 1088 Erase_MirrorMem_Res 0 "No Action" 1 "Complete" 2 "Reject" 3 "(Reserve)" ;
VAL_ 1088 Recall_MirrorMem_Res 0 "No Action" 1 "Complete" 2 "Reject" 3 "NoNeed" ;
VAL_ 1088 Record_MirrorMem_Res 0 "No Action" 1 "Complete" 2 "Reject" 3 "(Reserve)" ;
VAL_ 1088 PW_Move_R 0 "OFF" 1 "ManualOpen" 2 "ManualClose" 3 "AutoOpen" 4 "AutoClose" 5 "Stop" 6 "Reserved" 7 "Reserved" ;
VAL_ 1088 PW_Move_P 0 "OFF" 1 "ManualOpen" 2 "ManualClose" 3 "AutoOpen" 4 "AutoClose" 5 "Stop" 6 "Reserved" 7 "Reserved" ;
VAL_ 1088 PWcut_D_Actl 0 "Unknown" 1 "OFF" 2 "ON" 3 "Reserve" ;
VAL_ 1088 DrvDLMotorDriveStat 0 "Not Drive" 1 "All LockDrive" 2 "All SuperLockDrive" 3 "All UnLockDrive" 4 "Only DrvUnLockDrive" 5 "Return All LockDrive" 6 "Reserve" 7 "Reserve" ;
VAL_ 1088 Ctrl_DLSw_Drv_Stat 0 "Neutral" 1 "Lock" 2 "Unlock" ;
VAL_ 1088 LockLinkSwDrv_D_Actl 0 "Unlock" 1 "Neutral" 2 "Lock" 3 "Failure" ;
VAL_ 1088 DrStatDrv_D_Qf 0 "Faulty" 1 "Undefined" 2 "Not within specification" 3 "OK" ;
VAL_ 1088 DrStatDrv_B_Actl 0 "Door Closed" 1 "Door Ajar" ;
VAL_ 1087 RearWipr_Pos_Actl 0 "Unknown" 1 "Parking_Position" 2 "Not_Parking_Position" 3 "AS_SW_Failure" ;
VAL_ 1087 Rearfog_D_Act 0 "OFF" 1 "Normal ON" 2 "Fail1" 3 "Fail2" ;
VAL_ 1087 Reverse_D_Act 0 "OFF" 1 "Normal ON" 2 "Fail1" 3 "Fail2" ;
VAL_ 1087 Stoplamp_D_Act 0 "OFF" 1 "Normal ON" 2 "Fail1" 3 "Fail2" ;
VAL_ 1087 Taillamp2_D_Act 0 "OFF" 1 "Normal ON" 2 "Fail1" 3 "Fail2" ;
VAL_ 1087 Taillamp1_D_Act 0 "OFF" 1 "Normal ON" 2 "Fail1" 3 "Fail2" ;
VAL_ 1087 RearTurnL_D_Act 0 "OFF" 1 "Normal ON" 2 "Fail1" 3 "Fail2" ;
VAL_ 1087 RearTurnR_D_Act 0 "OFF" 1 "Normal ON" 2 "Fail1" 3 "Fail2" ;
VAL_ 1087 RearWipr_Stall_Status 0 "OK" 1 "Stall" ;
VAL_ 1087 RearWipr_Ctrl_Status 0 "Deactivate" 1 "Activate" 2 "Fail(Circuit Short to Ground)" 3 "Fail(Circuit Open)" 4 "Fail(Circuit Short to Battery)" 5 "Reserved" 6 "Reserved" 7 "Reserved" ;
VAL_ 1087 Trailer_Towing_B_Actl 0 "OFF" 1 "ON" ;
VAL_ 1087 Trailer_Hitch_B_Actl 0 "OFF" 1 "ON" ;
VAL_ 1086 PreAirCon_Timer_Reservation_FS 0 "Normal" 1 "Fail" ;
VAL_ 1086 Charge_Timer_Reservation_FS 0 "Normal" 1 "Fail" ;
VAL_ 1086 RsvTime_PreAirCon_Status 0 "NonArrival" 1 "Arrival" ;
VAL_ 1086 Charge_Distance_Impossible 0 "Possible to set distance" 1 "Impossible to set distance" ;
VAL_ 1086 RsvTime_Charge_Status 0 "NonArrival" 1 "Arrival" ;
VAL_ 1086 Balarm_Reason_D_Actl 0 "No Reason" 1 "Door" 2 "Trunk" 3 "Hood" 4 "Battery" 5 "Invasion" 6 "Inclination" 7 "Broken Glass" 8 "IG ON" ;
VAL_ 1086 UP_Light_SENSOR_Qf 0 "OK" 1 "NG" ;
VAL_ 1086 DrStatHood_B_Actl 0 "Door Closed" 1 "Door Ajar" ;
VAL_ 1086 Burglar_Status 0 "DEAD" 1 "INITIAL" 2 "PRE-ARMING" 3 "ARMING" 4 "ARMING STAND BY" 5 "ALARM" 6 "ALARM STAND BY" ;
VAL_ 1084 Ota_SuppIgonStat 0 "Unknown(default)" 1 "Suppression off" 2 "Suppression active" 3 "Reserved" 4 "Reserved" 5 "Reserved" 6 "Reserved" 7 "Reserved" 8 "Reserved" 9 "Reserved" 10 "Reserved" 11 "Reserved" 12 "Reserved" 13 "Reserved" 14 "Reserved" 15 "error(reserved)" ;
VAL_ 1084 Charge_Remote_Flag 0 "Unknown" 1 "StartReq" 2 "StopReq" 3 "Reserved" ;
VAL_ 1084 Defroster_Rear_Remote 0 "No_Request" 1 "OFF" 2 "ON" ;
VAL_ 1084 Defroster_Front_Remote 0 "No_Request" 1 "OFF" 2 "ON" ;
VAL_ 1084 PreAircon_Remote_Flag 0 "No_Request" 1 "OFF" 2 "ON" ;
VAL_ 1084 PreAircon_Remote_Cancel_Flag 0 "No_Request" 1 "OFF" 2 "ON" ;
VAL_ 1084 SeatCtrl_Remote_Rr_LH 0 "No_Request" 1 "OFF" 2 "Seat_Heater_low" 3 "Seat_Heater_mid" 4 "Seat_Heater_high" 5 "Seat_Ventilation_low" 6 "Seat_Ventilation_mid" 7 "Seat_Ventilation_high" 8 "Auto" ;
VAL_ 1084 SeatCtrl_Remote_Rr_RH 0 "No_Request" 1 "OFF" 2 "Seat_Heater_low" 3 "Seat_Heater_mid" 4 "Seat_Heater_high" 5 "Seat_Ventilation_low" 6 "Seat_Ventilation_mid" 7 "Seat_Ventilation_high" 8 "Auto" ;
VAL_ 1084 SteeringHeater_Remote 0 "No_Request" 1 "OFF" 2 "ON" 3 "Auto" ;
VAL_ 1084 SeatCtrl_Remote_Ps 0 "No_Request" 1 "OFF" 2 "Seat_Heater_low" 3 "Seat_Heater_mid" 4 "Seat_Heater_high" 5 "Seat_Ventilation_low" 6 "Seat_Ventilation_mid" 7 "Seat_Ventilation_high" 8 "Auto" ;
VAL_ 1084 SeatCtrl_Remote_Dr 0 "No_Request" 1 "OFF" 2 "Seat_Heater_low" 3 "Seat_Heater_mid" 4 "Seat_Heater_high" 5 "Seat_Ventilation_low" 6 "Seat_Ventilation_mid" 7 "Seat_Ventilation_high" 8 "Auto" ;
VAL_ 1084 Fuel_Lid_Motor_Lock_Request 0 "Not Drive" 1 "Lock" 2 "UnLock" ;
VAL_ 1084 FWD_Light_SENSOR_Qf 0 "OK" 1 "NG" ;
VAL_ 1084 DrStatRr_B_Actl 0 "Door Closed" 1 "Door Ajar" ;
VAL_ 1084 PwSavMode_D_Actl 0 "Unknown" 1 "PowerSave" 2 "Normal" 3 "Reserve" ;
VAL_ 1084 DrStatC_D_Qf 0 "Faulty" 1 "Undefined" 2 "Not within Specification" 3 "OK" ;
VAL_ 1084 SecurityStatus 0 "Off" 1 "On" ;
VAL_ 1084 PwSavModeDisp_D_Req 0 "Off" 1 "Engine Start Request" 2 "Ready On Request" 3 "Reserve" ;
VAL_ 1084 GlobalOpenClose_Request 0 "WindowStop" 1 "WindowOpen" 2 "WindowClose" ;
VAL_ 1084 TrnkLg_Motor_Request 0 "OFF" 1 "ON" ;
VAL_ 1084 DrLockUnlock_Ctl_Rq 0 "Not Drive" 1 "All Lock" 2 "All SuperLock" 3 "All UnLock" 4 "Only DrvUnLock" 5 "Return All Lock" ;
VAL_ 1078 SteerHeatIndic_D_Req 0 "Off" 1 "On" 2 "Auto" 3 "Grayout" ;
VAL_ 1078 SeatVentIndicRr_D_Req 0 "Off" 1 "Low" 2 "Mid" 3 "High" 4 "Auto" ;
VAL_ 1078 SeatVentIndicRl_D_Req 0 "Off" 1 "Low" 2 "Mid" 3 "High" 4 "Auto" ;
VAL_ 1078 SeatHeatIndicRr_D_Req 0 "Off" 1 "Low" 2 "Mid" 3 "High" 4 "Auto" ;
VAL_ 1078 SteerHeat_Elm_Enable 0 "ELM Enable" 1 "ELM Disable1" 2 "ELM Disable2" 3 "ELM Disable3" ;
VAL_ 1078 SeatHeat_Elm_Enable 0 "ELM Enable" 1 "ELM Disable1" 2 "ELM Disable2" 3 "ELM Disable3" ;
VAL_ 1078 Charge_Mode_Enabled_SW 0 "Off" 1 "On" 2 "Unknown" ;
VAL_ 1078 Drive_Mode_Enabled_Switch 0 "Off" 1 "SW-Up" 2 "SW-Down" 3 "Unknown" ;
VAL_ 1078 atcControlStatus 0 "NotDefined" 1 "Initialize" 2 "Normal" 3 "FailSafe" ;
VAL_ 1078 SeatVentIndicFr_D_Req 0 "Off" 1 "Low" 2 "Mid" 3 "High" 4 "Auto" 5 "Grayout" 6 "Reserved" 7 "Reserved" ;
VAL_ 1078 SeatVentIndicFl_D_Req 0 "Off" 1 "Low" 2 "Mid" 3 "High" 4 "Auto" 5 "Grayout" 6 "Reserved" 7 "Reserved" ;
VAL_ 1078 SeatHeatIndicFr_D_Req 0 "Off" 1 "Low" 2 "Mid" 3 "High" 4 "Auto" 5 "Grayout" 6 "Reserved" 7 "Reserved" ;
VAL_ 1078 SeatHeatIndicFl_D_Req 0 "Off" 1 "Low" 2 "Mid" 3 "High" 4 "Auto" 5 "Grayout" 6 "Reserved" 7 "Reserved" ;
VAL_ 1078 atcACmodeDisp 0 "NotDefined" 1 "(Reserved)" 2 "OFF" 3 "AC" 4 "AC-ECO" ;
VAL_ 1078 atcAImodeDisp 0 "NotDefined" 1 "(Reserved)" 2 "FRS" 3 "REC" 4 "REC025" 5 "REC050" 6 "REC075" 7 "Variable" ;
VAL_ 1078 atcADmodeDisp 0 "NotDefined" 1 "(Reserved)" 2 "PANEL" 3 "B/L" 4 "FLOOR" 5 "D/F" 6 "DEF" ;
VAL_ 1078 atcBlwLvlDisp 0 "NotDefined" 1 "Level 0(Relay OPEN)" 2 "Level 0(OFF)" 3 "Level 1" 4 "Level 2" 5 "Level 3" 6 "Level 4" 7 "Level 5" 8 "Level 6" 9 "Level 7" ;
VAL_ 1078 HvacEngStopCtrl_D_Actl 0 "Prohibit_Condition" 1 "Cooling" 2 "Heating" 3 "Cooling_Heating" ;
VAL_ 1078 SeatHeatIndicRl_D_Req 0 "Off" 1 "Low" 2 "Mid" 3 "High" 4 "Auto" ;
VAL_ 1078 BlowerSpeed 0 "inactive" 1 "Speed 0" 2 "Speed 1" 3 "Speed 2" 4 "Speed 3" 5 "Speed 4" 6 "Speed 5" 7 "Speed 6" 8 "Speed 7" ;
VAL_ 1078 HvacEngStopInputFail_D_Rq 0 "Normal" 1 "IS Input Fail" 2 "IS Input Fail manual DEF" 3 "Reserved" 4 "Reserved" 5 "Reserved" 6 "Reserved" 7 "Reserved" ;
VAL_ 1078 HvacAirCond_B_Rq 0 "No" 1 "Yes" ;
VAL_ 1078 HvacEngStopDis_B_Rq_exceptTEva 0 "IS Off" 1 "IS On" ;
VAL_ 1078 HvacEngStopDis_B_Rq 0 "IS Off" 1 "IS On" ;
VAL_ 1066 View_RPC_APS_Sw_D_Qf 0 "Faulty" 1 "Undefined" 2 "Not within Specification" 3 "OK" ;
VAL_ 1066 View_RPC_APS_Sw_B_Actl 0 "Off" 1 "On" ;
VAL_ 1066 HdcSw_D_Actl 0 "OFF" 1 "ON" 2 "UNKNOWN" 3 "reserved" ;
VAL_ 1066 FirstRowBuckleDriver 0 "driver belt not used" 1 "driver belt used" 2 "fault(hole IC)/resrve(mech)" 3 "reserve" ;
VAL_ 1064 Outlet_L2_D_Act 0 "OFF" 1 "Normal ON" 2 "Fail" 3 "Reserved" ;
VAL_ 1064 Outlet_L1_D_Act 0 "OFF" 1 "Normal ON" 2 "Fail" 3 "Reserved" ;
VAL_ 1064 FSM_L_D_Act 0 "OFF" 1 "Normal ON" 2 "Fail" 3 "Reserved" ;
VAL_ 1064 LCM_L_Err_Status_Info 0 "Not fail" 1 "Fail" ;
VAL_ 1064 FrontTurn_L_D_Act 0 "OFF" 1 "Normal ON" 2 "Fail" 3 "Reserved" ;
VAL_ 1064 Headlight_L_DRL_D_Act 0 "OFF" 1 "Normal ON" 2 "Fail" 3 "Reserved" ;
VAL_ 1064 Headlight_L_Pos_D_Act 0 "OFF" 1 "Normal ON" 2 "Fail" 3 "Reserved" ;
VAL_ 1064 Headlight_L_Lo_D_Act 0 "OFF" 1 "Normal ON" 2 "Fail" 3 "Reserved" ;
VAL_ 1064 Headlight_L_Hi_D_Act 0 "OFF" 1 "Normal ON" 2 "Fail" 3 "Reserved" ;
VAL_ 1063 Outlet_R2_D_Act 0 "OFF" 1 "Normal ON" 2 "Fail" 3 "Reserved" ;
VAL_ 1063 Outlet_R1_D_Act 0 "OFF" 1 "Normal ON" 2 "Fail" 3 "Reserved" ;
VAL_ 1063 FSM_R_D_Act 0 "OFF" 1 "Normal ON" 2 "Fail" 3 "Reserved" ;
VAL_ 1063 LCM_R_Err_Status_Info 0 "Not fail" 1 "Fail" ;
VAL_ 1063 FrontTurn_R_D_Act 0 "OFF" 1 "Normal ON" 2 "Fail" 3 "Reserved" ;
VAL_ 1063 Headlight_R_DRL_D_Act 0 "OFF" 1 "Normal ON" 2 "Fail" 3 "Reserved" ;
VAL_ 1063 Headlight_R_Pos_D_Act 0 "OFF" 1 "Normal ON" 2 "Fail" 3 "Reserved" ;
VAL_ 1063 Headlight_R_Lo_D_Act 0 "OFF" 1 "Normal ON" 2 "Fail" 3 "Reserved" ;
VAL_ 1063 Headlight_R_Hi_D_Act 0 "OFF" 1 "Normal ON" 2 "Fail" 3 "Reserved" ;
VAL_ 1051 AdbusMde_D_Actl 0 "modeA" 1 "modeB" 2 "modeC" 3 "reserve" ;
VAL_ 1051 BA_PDC 0 "OFF" 1 "ON" ;
VAL_ 1051 BAOF_PDC 0 "OFF" 1 "ON" ;
VAL_ 1050 GSNSOFF 0 "G sensor output on" 1 "G sensor output off" ;
VAL_ 1050 G_DETECT 0 "Not G detected" 1 "G detected" ;
VAL_ 1050 AdbusMde_D_Actl_BCM 0 "modeA" 1 "modeB" 2 "modeC" 3 "reserve" ;
VAL_ 1050 BA_PDC_BCM 0 "OFF" 1 "ON" ;
VAL_ 1050 BAOF_PDC_BCM 0 "OFF" 1 "ON" ;
VAL_ 1050 ACC_PDC 0 "OFF" 1 "ON" ;
VAL_ 1050 IGR_PDC 0 "OFF" 1 "ON" ;
VAL_ 1050 IGP_PDC 0 "OFF" 1 "ON" ;
VAL_ 1050 TRNR_S 0 "OFF" 1 "ON" ;
VAL_ 1050 TRNL_S 0 "OFF" 1 "ON" ;
VAL_ 1049 ALLOF_ST 0 "ALLOFF not requested" 1 "ALLOFF requested" ;
VAL_ 1049 TNS 0 "Undefined" 1 "During turn L output" 2 "During turn R output" 3 "No turn output" ;
VAL_ 1049 PAS_ST 0 "Off" 1 "On" ;
VAL_ 1049 CLL_R 0 "Off" 1 "On" ;
VAL_ 1049 TNLS_ST 0 "Turn lamp OFF" 1 "Turn lamp L ON" 2 "Turn lamp R ON" 3 "Hazard lamp = ON" 4 "communication falt" 5 "Reserved" 6 "Reserved" 7 "Reserved" ;
VAL_ 1049 SB_OK 0 "Off" 1 "On" ;
VAL_ 1049 FRWASH 0 "Front washer is OFF" 1 "Front washer is ON" ;
VAL_ 1049 FRWIPOPE 0 "Front wiper is stopped" 1 "Front wiper is in INT mode" 2 "Front wiper is in LO mode" 3 "Front wiper is in HI mode" 4 "Front wiper is house state" 5 "Front wiper is service state" 6 "Reserved" 7 "Front wiper is fail" ;
VAL_ 1049 FR_EXE 0 "No Request" 1 "Addition" 2 "Deletion" 3 "Cancel" ;
VAL_ 1049 FR_FID 0 "No Request" 1 "Face ID  1" 2 "Face ID  2" 3 "Face ID  3" 4 "Face ID  4" 5 "Face ID  5" 6 "Face ID  6" 7 "Face ID  7" 8 "Face ID  8" 9 "Face ID  9" 10 "Face ID 10" 11 "Face ID 11" 12 "Face ID 12" 13 "Face ID 13" 14 "Face ID 14" 15 "All Face ID" ;
VAL_ 1049 FR_PIDST 0 "Not confirmed State" 1 "Not comfirm FaceID1 Reg" 2 "Not comfirm FaceID2 Reg" 3 "Not comfirm FaceID1 ID2 Reg" 4 "Not comfirm FaceID3 Reg" 5 "Not comfirm FaceID1 ID3 Reg" 6 "Not comfirm FaceID2 ID3 Reg" 7 "Not comfirm FaceID1 ID2 ID3 Reg" 8 "Comfirmed Not comfirm" 9 "Comfirmed FaceID1 Reg" 10 "Comfirmed FaceID2 Reg" 11 "Comfirmed FaceID1 ID2 Reg" 12 "Comfirmed FaceID3 Reg" 13 "Comfirmed FaceID1 ID3 Reg" 14 "Comfirmed FaceID2 ID3 Reg" 15 "Comfirmed FaceID1 ID2 ID3 Reg" ;
VAL_ 1049 PSER 0 "No Request" 1 "Deletion Request" ;
VAL_ 1049 PSEU 0 "Indeterminate" 1 "User 1" 2 "User 2" 3 "User 3" 4 "Reserved" 5 "Reserved" 6 "Reserved" 7 "Guest" ;
VAL_ 1049 PSUN_D 0 "Indeterminate" 1 "User 1" 2 "User 2" 3 "User 3" 4 "Reserved" 5 "Reserved" 6 "Reserved" 7 "Guest" ;
VAL_ 1048 MRMV_R 0 "No Request" 1 "Close" 2 "Open" 3 "Reserved" ;
VAL_ 1047 EPB_TrqRequire 0 "Not Require" 1 "Require" ;
VAL_ 1047 EPB_IGoff_Apply_Inhibit 0 "Not Inhibit" 1 "Inhibit" ;
VAL_ 1047 RGN_StpLmp_Fail_Flag 0 "No" 1 "Yes" ;
VAL_ 1047 BrkSupWhlTq_B_Falt 0 "Off" 1 "On" ;
VAL_ 1047 BrkFluidLvl_D_Actl 0 "Normal" 1 "Low" 2 "Reserved" 3 "Unknown" ;
VAL_ 1047 DSC_OnOff_status 0 "ON" 1 "OFF" ;
VAL_ 1047 TCS_ENG_FAILD 0 "No" 1 "Yes" ;
VAL_ 1047 TCS_BRK_FAILD 0 "No" 1 "Yes" ;
VAL_ 1047 Dsc_B_Falt 0 "No" 1 "Yes" ;
VAL_ 1047 EPB_Status 0 "Released" 1 "Applied" 2 "In operation(applying/releasing)" 3 "Waiting for operating" 4 "Unknown" ;
VAL_ 1047 EPB_SwitchPosition 0 "No request" 1 "Release request" 2 "Apply request" 3 "Error" ;
VAL_ 1047 EPB_EnableExternalApply_PT 0 "Not enable" 1 "Enable" ;
VAL_ 1047 EPB_EnableDecelRequest 0 "Not enable" 1 "Enable" ;
VAL_ 1047 EPB_EnableExternalApply_VCM 0 "Not enable" 1 "Enable" ;
VAL_ 1047 AutoHoldStdbyLamp_D_Rq 0 "Off" 1 "On" 2 "Slow Flash (1.4Hz)" 3 "Slow Flash (1.4Hz)" ;
VAL_ 1046 A_CLR_S 0 "Reserve" 8 "Automated" 9 "Light" 10 "Dark" 15 "initial" ;
VAL_ 1045 DSTVIB 0 "No steering vibration request" 1 "type 1" 2 "type 2" 3 "type 3" ;
VAL_ 1045 FRDHTR_G 0 "StateA" 1 "StateB" ;
VAL_ 1045 ERMCNTST 0 "Eco Run Mode OFF" 1 "Eco Run Mode ON & Prohibit pulse" 2 "Eco Run Mode ON & Glide" 3 "Eco Run Mode ON & Pulse" ;
VAL_ 1045 V_IDARGL 0 "no unrecognized" 1 "with own lane and no both side l" 2 "with own lane and no right line" 3 "with own lane and no left line" 4 "no own lane and no both side lin" 5 "no own lane and no right line" 6 "no own lane and no left line" 7 "reserved" ;
VAL_ 1045 V_IDANOA 0 "no malfunctions" 1 "lane unrecognized" 2 "driver acceleration override" 3 "exceeding a predetermined vehicl" 4 "under a predetermined vehicle sp" 5 "during a curve" 6 "driver deceleration override" 7 "reserved" ;
VAL_ 1045 EJLDACP 0 "Not Cooprated" 1 "Cooprated" ;
VAL_ 1045 V_IDACCL 0 "no cancel" 1 "passing through the target" 2 "achieved control target volume" 3 "target leaves" 4 "acceleration override" 5 "deceleration override" 6 "steering to left direction overr" 7 "steering to right direction over" 8 "below a predetermined min vehicl" ;
VAL_ 1044 ACCMARB 0 "Map ACC not selected" 1 "Map ACC selected" ;
VAL_ 1044 ACCMRCG 0 "No target" 1 "SD map" 2 "SD map+crosswalk" 3 "SD map+stop/yeild line" 4 "SD map+crosswalk+stop/yeild line" ;
VAL_ 1044 ACCMSGN 0 "not detected" 1 "map-only detected" 2 "camera-only detected" 3 "map-camera fusion detection" ;
VAL_ 1044 ACCMPHS 0 "No assistance" 1 "Soft deceleration" 2 "Keep speed" 3 "High deceleration" 4 "assistance limit" 5 "Reserved" 6 "Reserved" 7 "Driver cancel" ;
VAL_ 1036 GCC_CfgParam_40C 240 "BlockNoF0" 241 "BlockNoF1" 242 "BlockNoF2" 243 "BlockNoF3" 1 "BlockNo01" 2 "BlockNo02" 3 "BlockNo03" 4 "BlockNo04" 5 "BlockNo05" 6 "BlockNo06" 16 "BlockNo10" 17 "BlockNo11" 18 "BlockNo12" 19 "BlockNo13" 20 "BlockNo14" 21 "BlockNo15" 22 "BlockNo16" 32 "BlockNo20" 37 "BlockNo25" 48 "BlockNo30" 64 "BlockNo40" 80 "BlockNo50" 82 "BlockNo52" 96 "BlockNo60" 98 "BlockNo62" 99 "BlockNo63" 112 "BlockNo70" 114 "BlockNo72" 128 "BlockNo80" 130 "BlockNo82" 144 "BlockNo90" 145 "BlockNo91" 146 "BlockNo92" 147 "BlockNo93" 148 "BlockNo94" 149 "BlockNo95" 224 "BlockNoE0" ;
VAL_ 1034 GCC_CfgParam 240 "BlockNoF0" 241 "BlockNoF1" 242 "BlockNoF2" 243 "BlockNoF3" 1 "BlockNo01" 2 "BlockNo02" 3 "BlockNo03" 4 "BlockNo04" 5 "BlockNo05" 6 "BlockNo06" 16 "BlockNo10" 17 "BlockNo11" 18 "BlockNo12" 19 "BlockNo13" 20 "BlockNo14" 21 "BlockNo15" 22 "BlockNo16" 32 "BlockNo20" 37 "BlockNo25" 48 "BlockNo30" 64 "BlockNo40" 80 "BlockNo50" 82 "BlockNo52" 96 "BlockNo60" 98 "BlockNo62" 99 "BlockNo63" 112 "BlockNo70" 114 "BlockNo72" 128 "BlockNo80" 130 "BlockNo82" 144 "BlockNo90" 145 "BlockNo91" 146 "BlockNo92" 147 "BlockNo93" 148 "BlockNo94" 149 "BlockNo95" 224 "BlockNoE0" ;
VAL_ 1033 MOURELV 0 "0%" 1 "7%" 2 "13%" 3 "20%" 4 "27%" 5 "33%" 6 "40%" 7 "47%" 8 "53%" 9 "60%" 10 "67%" 11 "73%" 12 "80%" 13 "87%" 14 "93%" 15 "100%" ;
VAL_ 1033 EYERELV 0 "0%" 1 "7%" 2 "13%" 3 "20%" 4 "27%" 5 "33%" 6 "40%" 7 "47%" 8 "53%" 9 "60%" 10 "67%" 11 "73%" 12 "80%" 13 "87%" 14 "93%" 15 "100%" ;
VAL_ 1033 S_SMOKE 0 "Undetect" 1 "Detect" ;
VAL_ 1033 S_SDIST 0 "Undetect" 1 "Detect" ;
VAL_ 1033 S_PHONE 0 "Undetect" 1 "Detect" ;
VAL_ 1033 S_ABUSE 0 "Undetect" 1 "Detect" ;
VAL_ 1033 WL_SDIST 0 "Warning level 0" 1 "Warning level 1" 2 "Warning level 2" 3 "Warning level 3" ;
VAL_ 1033 WL_ABUSE 0 "Warning level 0" 1 "Warning level 1" 2 "Warning level 2" 3 "Warning level 3" ;
VAL_ 1033 WNGVALID 0 "valid state" 1 "invalid state1" 2 "invalid state2" 3 "invalid state3" 4 "invalid state4" 5 "invalid state5" 6 "invalid state6" 7 "invalid state7" ;
VAL_ 1033 GAZEFLAG 0 "Not seen" 1 "Seeing (instantaneous value)" 2 "Seen (instantaneous value)" 3 "Unable to judge" ;
VAL_ 1032 ACCMMOD 0 "OFF" 1 "ON" 2 "Ghost mode" 3 "Reserved" ;
VAL_ 1032 ACCMAPP 0 "Idle (without ODD)" 1 "Traffic light" 2 "Intersection w/o traffic sign" 3 "Roundabout" 4 "Stop" 5 "Yield" 6 "Tollgate" 7 "Pre-curve deceleration" ;
